VERSION "created by canmatrix"

NS_ :

BS_:

BU_: CEM HUT GW T_BOX ESP XBOX_D IFC TCU DVR Tester

BO_ 51 T_BOX_FD1: 16 T_BOX
 SG_ T_BOX_FD1_0x33 : 0|64@1+ (1,0) [0|0] ""  HUT

BO_ 68 HUT7: 8 HUT
 SG_ HUT7_0x44 : 0|64@1+ (1,0) [0|0] "" Vector__XXX

BO_ 74 HUT6: 8 HUT
 SG_ HUT6_0x4A : 0|64@1+ (1,0) [0|0] "" Vector__XXX

BO_ 86 GLO_NASS1: 8 GW
 SG_ GLO_NASS1_0x56 : 0|64@1+ (1,0) [0|0] ""  HUT

BO_ 161 CSA2: 8 GW
 SG_ CSA2_0xA1 : 0|64@1+ (1,0) [0|0] ""  HUT

BO_ 166 DCT3: 8 GW
 SG_ DCT3_0xA6 : 0|64@1+ (1,0) [0|0] ""  HUT

BO_ 200 ESP11: 8 GW
 SG_ ESP11_0xC8 : 0|64@1+ (1,0) [0|0] ""  HUT

BO_ 241 BMS4: 8 GW
 SG_ BMS4_0xF1 : 0|64@1+ (1,0) [0|0] ""  HUT

BO_ 265 IFC1: 8 GW
 SG_ IFC1_0x109 : 0|64@1+ (1,0) [0|0] ""  HUT

BO_ 273 ECM1: 8 GW
 SG_ ECM1_0x111 : 0|64@1+ (1,0) [0|0] ""  HUT

BO_ 288 Ibooster_FD2: 64 GW
 SG_ Ibooster_FD2_0x120 : 0|512@1+ (1,0) [0|0] ""  HUT

BO_ 311 ESP_FD2: 64 ESP
 SG_ ESP_FD2_0x137 : 0|448@1+ (1,0) [0|0] ""  HUT

BO_ 327 EPS_FD1: 64 GW
 SG_ EPS_FD1_0x147 : 0|512@1+ (1,0) [0|0] ""  HUT

BO_ 338 ELD1: 8 GW
 SG_ ELD1_0x152 : 0|64@1+ (1,0) [0|0] ""  HUT

BO_ 347 HAP_FD1: 64 GW
 SG_ HAP_FD1_0x15B : 0|512@1+ (1,0) [0|0] ""  HUT

BO_ 350 CR_FD1: 64 GW
 SG_ CR_FD1_0x15E : 0|512@1+ (1,0) [0|0] ""  HUT

BO_ 357 CSA1: 8 GW
 SG_ CSA1_0x165 : 0|64@1+ (1,0) [0|0] ""  HUT

BO_ 363 EPB1: 8 GW
 SG_ EPB1_0x16B : 0|64@1+ (1,0) [0|0] ""  HUT

BO_ 367 RSDS_FD1: 64 GW
 SG_ RSDS_FD1_0x16F : 0|512@1+ (1,0) [0|0] ""  HUT

BO_ 368 ESP8: 8 GW
 SG_ ESP8_0x170 : 0|64@1+ (1,0) [0|0] ""  HUT

BO_ 395 AEB_FD1: 64 GW
 SG_ AEB_FD1_0x18B : 0|512@1+ (1,0) [0|0] ""  HUT

BO_ 411 F_PBOX1: 8 CEM
 SG_ F_PBOX1_0x19B : 0|64@1+ (1,0) [0|0] ""  HUT

BO_ 412 R_PBOX1: 16 GW
 SG_ R_PBOX1_0x19C : 0|64@1+ (1,0) [0|0] ""  HUT

BO_ 415 IFC_FD5: 64 GW
 SG_ IFC_FD5_0x19F : 0|512@1+ (1,0) [0|0] ""  HUT

BO_ 465 HUT49: 8 HUT
 SG_ HUT49_0x1D1 : 0|64@1+ (1,0) [0|0] "" Vector__XXX

BO_ 473 GW_OTA: 8 CEM
 SG_ GW_OTA_0x1D9 : 0|64@1+ (1,0) [0|0] ""  HUT

BO_ 474 HUT_FD4: 64 HUT
 SG_ HUT_FD4_0x1DA : 0|512@1+ (1,0) [0|0] "" Vector__XXX

BO_ 475 HUT_FD5: 64 HUT
 SG_ HUT_FD5_0x1DB : 0|512@1+ (1,0) [0|0] "" Vector__XXX

BO_ 476 HUT45: 8 HUT
 SG_ HUT45_0x1DC : 0|64@1+ (1,0) [0|0] "" Vector__XXX

BO_ 477 HUT46: 8 HUT
 SG_ HUT46_0x1DD : 0|64@1+ (1,0) [0|0] "" Vector__XXX

BO_ 479 DOCK2: 64 XBOX_D
 SG_ DOCK2_0x1DF : 0|512@1+ (1,0) [0|0] ""  HUT

BO_ 481 T_BOX_FD4: 16 T_BOX
 SG_ T_BOX_FD4_0x1E1 : 0|128@1+ (1,0) [0|0] ""  HUT

BO_ 485 HUT35: 8 HUT
 SG_ HUT35_0x1E5 : 0|64@1+ (1,0) [0|0] "" Vector__XXX

BO_ 487 HUT38: 8 HUT
 SG_ HUT38_0x1E7 : 0|64@1+ (1,0) [0|0] "" Vector__XXX

BO_ 489 HUT30: 8 HUT
 SG_ HUT30_0x1E9 : 0|64@1+ (1,0) [0|0] "" Vector__XXX

BO_ 491 HUT39: 8 HUT
 SG_ HUT39_0x1EB : 0|64@1+ (1,0) [0|0] "" Vector__XXX

BO_ 493 HUT33: 8 HUT
 SG_ HUT33_0x1ED : 0|64@1+ (1,0) [0|0] "" Vector__XXX

BO_ 494 HUT15: 16 HUT
 SG_ HUT15_0x1EE : 0|64@1+ (1,0) [0|0] "" Vector__XXX

BO_ 497 ETC2: 8 GW
 SG_ ETC2_0x1F1 : 0|64@1+ (1,0) [0|0] ""  HUT

BO_ 498 ETC4: 8 GW
 SG_ ETC4_0x1F2 : 0|64@1+ (1,0) [0|0] ""  HUT

BO_ 505 HUT42: 8 HUT
 SG_ HUT42_0x1F9 : 0|64@1+ (1,0) [0|0] "" Vector__XXX

BO_ 506 BLE5: 8 GW
 SG_ BLE5_0x1FA : 0|64@1+ (1,0) [0|0] ""  HUT

BO_ 507 HUT41: 8 HUT
 SG_ HUT41_0x1FB : 0|64@1+ (1,0) [0|0] "" Vector__XXX

BO_ 509 HUT43: 8 HUT
 SG_ HUT43_0x1FD : 0|64@1+ (1,0) [0|0] "" Vector__XXX

BO_ 545 DCT5: 8 GW
 SG_ DCT5_0x221 : 0|64@1+ (1,0) [0|0] ""  HUT

BO_ 546 IFC_FD6: 64 GW
 SG_ IFC_FD6_0x222 : 0|512@1+ (1,0) [0|0] ""  HUT

BO_ 548 HUT40: 8 HUT
 SG_ HUT40_0x224 : 0|64@1+ (1,0) [0|0] "" Vector__XXX

BO_ 551 AEB_FD2: 64 IFC
 SG_ AEB_FD2_0x227 : 0|448@1+ (1,0) [0|0] ""  HUT

BO_ 561 ABS1: 8 GW
 SG_ ABS1_0x231 : 0|64@1+ (1,0) [0|0] ""  HUT

BO_ 566 DCT_FD4: 64 TCU
 SG_ DCT_FD4_0x236 : 0|448@1+ (1,0) [0|0] ""  HUT

BO_ 568 BCM12: 8 CEM
 SG_ BCM12_0x238 : 0|64@1+ (1,0) [0|0] ""  HUT

BO_ 573 IFC_FD2: 64 IFC
 SG_ IFC_FD2_0x23D : 0|448@1+ (1,0) [0|0] ""  HUT

BO_ 579 HUT_FD3: 64 HUT
 SG_ HUT_FD3_0x243 : 0|512@1+ (1,0) [0|0] "" Vector__XXX

BO_ 580 CSA3: 8 GW
 SG_ CSA3_0x244 : 0|64@1+ (1,0) [0|0] ""  HUT

BO_ 581 ABM2: 8 GW
 SG_ ABM2_0x245 : 0|64@1+ (1,0) [0|0] ""  HUT

BO_ 582 ABS2: 8 GW
 SG_ ABS2_0x246 : 0|64@1+ (1,0) [0|0] ""  HUT

BO_ 584 HCU_PT7: 8 GW
 SG_ HCU_PT7_0x248 : 0|64@1+ (1,0) [0|0] ""  HUT

BO_ 589 DMS_FD1: 64 HUT
 SG_ DMS_FD1_0x24D : 0|512@1+ (1,0) [0|0] "" Vector__XXX

BO_ 593 TOD1: 8 GW
 SG_ TOD1_0x251 : 0|64@1+ (1,0) [0|0] ""  HUT

BO_ 604 BLE1: 8 GW
 SG_ BLE1_0x25C : 0|64@1+ (1,0) [0|0] ""  HUT

BO_ 623 HUT32: 8 HUT
 SG_ HUT32_0x26F : 0|64@1+ (1,0) [0|0] "" Vector__XXX

BO_ 625 ECM2: 8 GW
 SG_ ECM2_0x271 : 0|64@1+ (1,0) [0|0] ""  HUT

BO_ 627 Trailer1: 8 GW
 SG_ Trailer1_0x273 : 0|64@1+ (1,0) [0|0] ""  HUT

BO_ 628 HAP_FD2: 64 GW
 SG_ HAP_FD2_0x274 : 0|512@1+ (1,0) [0|0] ""  HUT

BO_ 636 AC8: 8 GW
 SG_ AC8_0x27C : 0|64@1+ (1,0) [0|0] ""  HUT

BO_ 639 IP2: 16 HUT
 SG_ IP2_0x27F : 0|64@1+ (1,0) [0|0] "" Vector__XXX

BO_ 647 ALS1: 16 GW
 SG_ ALS1_0x287 : 0|128@1+ (1,0) [0|0] ""  HUT

BO_ 649 HAP_FD6: 64 GW
 SG_ HAP_FD6_0x289 : 0|512@1+ (1,0) [0|0] ""  HUT

BO_ 653 BCM7: 8 CEM
 SG_ BCM7_0x28D : 0|64@1+ (1,0) [0|0] ""  HUT

BO_ 656 ECM_PT6: 8 GW
 SG_ ECM_PT6_0x290 : 0|64@1+ (1,0) [0|0] ""  HUT

BO_ 659 IP1: 8 HUT
 SG_ IP1_0x293 : 0|64@1+ (1,0) [0|0] "" Vector__XXX

BO_ 661 PEPS2: 8 CEM
 SG_ PEPS2_0x295 : 0|64@1+ (1,0) [0|0] ""  HUT

BO_ 664 HAP_FD3: 64 GW
 SG_ HAP_FD3_0x298 : 0|512@1+ (1,0) [0|0] ""  HUT

BO_ 665 AC14: 8 GW
 SG_ AC14_0x299 : 0|64@1+ (1,0) [0|0] ""  HUT

BO_ 667 HAP_FD7: 64 GW
 SG_ HAP_FD7_0x29B : 0|512@1+ (1,0) [0|0] ""  HUT

BO_ 669 AC1: 8 GW
 SG_ AC1_0x29D : 0|64@1+ (1,0) [0|0] ""  HUT

BO_ 671 BCM8: 8 CEM
 SG_ BCM8_0x29F : 0|64@1+ (1,0) [0|0] ""  HUT

BO_ 675 BCM14: 8 CEM
 SG_ BCM14_0x2A3 : 0|64@1+ (1,0) [0|0] ""  HUT

BO_ 680 EEM1: 8 CEM
 SG_ EEM1_0x2A8 : 0|64@1+ (1,0) [0|0] ""  HUT

BO_ 683 ACC_FD2: 64 IFC
 SG_ ACC_FD2_0x2AB : 0|448@1+ (1,0) [0|0] ""  HUT

BO_ 692 ACC_FD3: 64 GW
 SG_ ACC_FD3_0x2B4 : 0|512@1+ (1,0) [0|0] ""  HUT

BO_ 694 HUT26: 8 HUT
 SG_ HUT26_0x2B6 : 0|64@1+ (1,0) [0|0] "" Vector__XXX

BO_ 696 ACC_FD4: 64 GW
 SG_ ACC_FD4_0x2B8 : 0|512@1+ (1,0) [0|0] ""  HUT

BO_ 697 DWD1: 8 GW
 SG_ DWD1_0x2B9 : 0|64@1+ (1,0) [0|0] ""  HUT

BO_ 698 WPC1: 8 GW
 SG_ WPC1_0x2BA : 0|64@1+ (1,0) [0|0] ""  HUT

BO_ 699 GW_FD1: 64 CEM
 SG_ GW_FD1_0x2BB : 0|512@1+ (1,0) [0|0] ""  HUT

BO_ 705 DSM1: 8 CEM
 SG_ DSM1_0x2C1 : 0|64@1+ (1,0) [0|0] ""  HUT

BO_ 707 HUT_FD1: 64 HUT
 SG_ HUT_FD1_0x2C3 : 0|448@1+ (1,0) [0|0] "" Vector__XXX

BO_ 714 DDCM1: 8 GW
 SG_ DDCM1_0x2CA : 0|64@1+ (1,0) [0|0] ""  HUT

BO_ 716 AC4: 8 GW
 SG_ AC4_0x2CC : 0|64@1+ (1,0) [0|0] ""  HUT

BO_ 717 PDCM1: 8 GW
 SG_ PDCM1_0x2CD : 0|64@1+ (1,0) [0|0] ""  HUT

BO_ 718 DSC4: 8 GW
 SG_ DSC4_0x2CE : 0|64@1+ (1,0) [0|0] ""  HUT

BO_ 719 IFC_FD3: 64 GW
 SG_ IFC_FD3_0x2CF : 0|512@1+ (1,0) [0|0] ""  HUT

BO_ 720 AC7: 8 GW
 SG_ AC7_0x2D0 : 0|64@1+ (1,0) [0|0] ""  HUT

BO_ 721 SCM1: 8 CEM
 SG_ SCM1_0x2D1 : 0|64@1+ (1,0) [0|0] ""  HUT

BO_ 722 AMP4_ANC1: 8 GW
 SG_ AMP4_ANC1_0x2D2 : 0|64@1+ (1,0) [0|0] ""  HUT

BO_ 723 ECM11: 8 GW
 SG_ ECM11_0x2D3 : 0|64@1+ (1,0) [0|0] ""  HUT

BO_ 728 HUT23: 8 HUT
 SG_ HUT23_0x2D8 : 0|64@1+ (1,0) [0|0] "" Vector__XXX

BO_ 730 HUT22: 8 HUT
 SG_ HUT22_0x2DA : 0|64@1+ (1,0) [0|0] "" Vector__XXX

BO_ 733 HUT21: 8 HUT
 SG_ HUT21_0x2DD : 0|64@1+ (1,0) [0|0] "" Vector__XXX

BO_ 734 HUT20: 8 HUT
 SG_ HUT20_0x2DE : 0|64@1+ (1,0) [0|0] "" Vector__XXX

BO_ 748 DVR_FD1: 64 HUT
 SG_ DVR_FD1_0x2EC : 0|512@1+ (1,0) [0|0] "" Vector__XXX

BO_ 752 T_BOX_FD10: 64 T_BOX
 SG_ T_BOX_FD10_0x2F0 : 0|512@1+ (1,0) [0|0] ""  HUT

BO_ 759 DDCM3: 8 GW
 SG_ DDCM3_0x2F7 : 0|64@1+ (1,0) [0|0] ""  HUT

BO_ 760 AC6: 8 GW
 SG_ AC6_0x2F8 : 0|64@1+ (1,0) [0|0] ""  HUT

BO_ 762 HCU_PT4: 8 GW
 SG_ HCU_PT4_0x2FA : 0|64@1+ (1,0) [0|0] ""  HUT

BO_ 765 AC3: 8 GW
 SG_ AC3_0x2FD : 0|64@1+ (1,0) [0|0] ""  HUT

BO_ 770 PEPS4: 8 CEM
 SG_ PEPS4_0x302 : 0|64@1+ (1,0) [0|0] ""  HUT

BO_ 771 ESCL2: 8 GW
 SG_ ESCL2_0x303 : 0|64@1+ (1,0) [0|0] ""  HUT

BO_ 772 HCM_L2: 8 GW
 SG_ HCM_L2_0x304 : 0|64@1+ (1,0) [0|0] ""  HUT

BO_ 773 BCM11: 8 CEM
 SG_ BCM11_0x305 : 0|64@1+ (1,0) [0|0] ""  HUT

BO_ 776 HCM_L1: 8 GW
 SG_ HCM_L1_0x308 : 0|64@1+ (1,0) [0|0] ""  HUT

BO_ 778 RSDS_FD2: 64 GW
 SG_ RSDS_FD2_0x30A : 0|512@1+ (1,0) [0|0] ""  HUT

BO_ 780 HUT31: 8 HUT
 SG_ HUT31_0x30C : 0|64@1+ (1,0) [0|0] "" Vector__XXX

BO_ 781 HCM_R1: 8 GW
 SG_ HCM_R1_0x30D : 0|64@1+ (1,0) [0|0] ""  HUT

BO_ 783 BCM19: 8 CEM
 SG_ BCM19_0x30F : 0|64@1+ (1,0) [0|0] ""  HUT

BO_ 785 DOCK1: 64 XBOX_D
 SG_ DOCK1_0x311 : 0|512@1+ (1,0) [0|0] ""  HUT

BO_ 793 BCM1: 16 GW
 SG_ BCM1_0x319 : 0|64@1+ (1,0) [0|0] ""  HUT

BO_ 796 HUT13: 8 HUT
 SG_ HUT13_0x31C : 0|64@1+ (1,0) [0|0] "" Vector__XXX

BO_ 805 HUD1: 8 GW
 SG_ HUD1_0x325 : 0|64@1+ (1,0) [0|0] ""  HUT

BO_ 816 HCM_R2: 8 GW
 SG_ HCM_R2_0x330 : 0|64@1+ (1,0) [0|0] ""  HUT

BO_ 817 HUT10: 8 HUT
 SG_ HUT10_0x331 : 0|64@1+ (1,0) [0|0] "" Vector__XXX

BO_ 818 RFCM_L1: 8 GW
 SG_ RFCM_L1_0x332 : 0|64@1+ (1,0) [0|0] ""  HUT

BO_ 819 RFCM_R1: 8 GW
 SG_ RFCM_R1_0x333 : 0|64@1+ (1,0) [0|0] ""  HUT

BO_ 825 HUT25: 8 HUT
 SG_ HUT25_0x339 : 0|64@1+ (1,0) [0|0] "" Vector__XXX

BO_ 827 HUT17: 8 HUT
 SG_ HUT17_0x33B : 0|64@1+ (1,0) [0|0] "" Vector__XXX

BO_ 833 TPMS1: 16 GW
 SG_ TPMS1_0x341 : 0|64@1+ (1,0) [0|0] ""  HUT

BO_ 836 ETC3: 8 GW
 SG_ ETC3_0x344 : 0|64@1+ (1,0) [0|0] ""  HUT

BO_ 837 BCM3: 16 GW
 SG_ BCM3_0x345 : 0|64@1+ (1,0) [0|0] ""  HUT

BO_ 840 HUT16: 8 HUT
 SG_ HUT16_0x348 : 0|64@1+ (1,0) [0|0] "" Vector__XXX

BO_ 842 IP3: 16 HUT
 SG_ IP3_0x34A : 0|128@1+ (1,0) [0|0] "" Vector__XXX

BO_ 845 BCM18: 8 CEM
 SG_ BCM18_0x34D : 0|64@1+ (1,0) [0|0] ""  HUT

BO_ 849 ABM1: 16 GW
 SG_ ABM1_0x351 : 0|64@1+ (1,0) [0|0] ""  HUT

BO_ 862 CP1: 8 CEM
 SG_ CP1_0x35E : 0|64@1+ (1,0) [0|0] ""  HUT

BO_ 871 HUT1: 8 HUT
 SG_ HUT1_0x367 : 0|64@1+ (1,0) [0|0] "" Vector__XXX

BO_ 873 HUT2: 8 HUT
 SG_ HUT2_0x369 : 0|64@1+ (1,0) [0|0] "" Vector__XXX

BO_ 875 HUT3: 8 HUT
 SG_ HUT3_0x36B : 0|64@1+ (1,0) [0|0] "" Vector__XXX

BO_ 877 HUT4: 8 HUT
 SG_ HUT4_0x36D : 0|64@1+ (1,0) [0|0] "" Vector__XXX

BO_ 880 HUT34: 8 HUT
 SG_ HUT34_0x370 : 0|64@1+ (1,0) [0|0] "" Vector__XXX

BO_ 881 ECM3: 8 GW
 SG_ ECM3_0x371 : 0|64@1+ (1,0) [0|0] ""  HUT

BO_ 901 AC2: 8 GW
 SG_ AC2_0x385 : 0|64@1+ (1,0) [0|0] ""  HUT

BO_ 917 TPMS2: 16 GW
 SG_ TPMS2_0x395 : 0|64@1+ (1,0) [0|0] ""  HUT

BO_ 943 HUT12: 8 HUT
 SG_ HUT12_0x3AF : 0|64@1+ (1,0) [0|0] "" Vector__XXX

BO_ 949 ECM19: 8 GW
 SG_ ECM19_0x3B5 : 0|64@1+ (1,0) [0|0] ""  HUT

BO_ 951 ECM20: 8 GW
 SG_ ECM20_0x3B7 : 0|64@1+ (1,0) [0|0] ""  HUT

BO_ 962 HCU_HC7: 8 GW
 SG_ HCU_HC7_0x3C2 : 0|64@1+ (1,0) [0|0] ""  HUT

BO_ 993 AMP1: 8 GW
 SG_ AMP1_0x3E1 : 0|64@1+ (1,0) [0|0] ""  HUT

BO_ 995 AMP2: 16 GW
 SG_ AMP2_0x3E3 : 0|64@1+ (1,0) [0|0] ""  HUT

BO_ 997 AMP3: 8 GW
 SG_ AMP3_0x3E5 : 0|64@1+ (1,0) [0|0] ""  HUT

BO_ 1001 T_BOX_FD3: 16 T_BOX
 SG_ T_BOX_FD3_0x3E9 : 0|64@1+ (1,0) [0|0] ""  HUT

BO_ 1045 HUT19: 8 HUT
 SG_ HUT19_0x415 : 0|64@1+ (1,0) [0|0] "" Vector__XXX

BO_ 1888 DiagFuncReq: 8 Tester
 SG_ DiagFuncReq : 7|64@0+ (1,0) [0|1.84467440737096E+019] ""  GW,CEM,T_BOX,XBOX_D,DVR,HUT

BO_ 1889 GW_Phy_Req: 8 Tester
 SG_ GW_Phy_Req : 7|64@0+ (1,0) [0|1.84467440737096E+019] ""  GW

BO_ 1918 T_Box_Phy_Req: 8 Tester
 SG_ T_Box_Phy_Req : 7|64@0+ (1,0) [0|1.84467440737096E+019] ""  GW,T_BOX

BO_ 1843 XBOX_D_Phy_Req: 8 Tester
 SG_ XBOX_D_Phy_Req : 7|64@0+ (1,0) [0|1.84467440737096E+019] ""  GW,XBOX_D

BO_ 1907 HUT_Phy_Req: 8 Tester
 SG_ HUT_Phy_Req : 7|64@0+ (1,0) [0|1.84467440737096E+019] ""  GW,HUT

BO_ 1953 GW_Phy_Resp: 8 GW
 SG_ GW_Phy_Resp : 7|64@0+ (1,0) [0|1.84467440737096E+019] ""  Tester

BO_ 1982 T_Box_Phy_Resp: 8 T_BOX
 SG_ T_Box_Phy_Resp : 7|64@0+ (1,0) [0|1.84467440737096E+019] ""  GW,Tester

BO_ 1844 XBOX_D_Phy_Resp: 8 XBOX_D
 SG_ XBOX_D_Phy_Resp : 7|64@0+ (1,0) [0|1.84467440737096E+019] ""  GW,Tester

BO_ 1971 HUT_Phy_Resp: 8 HUT
 SG_ HUT_Phy_Resp : 7|64@0+ (1,0) [0|1.84467440737096E+019] ""  GW,Tester

BO_ 1290 T_Box_NM: 8 T_BOX
 SG_ Destination_T_Box_NM : 7|8@0+ (1,0) [0|255] ""  CEM,XBOX_D,DVR,HUT
 SG_ OpCode_T_Box_NM : 15|8@0+ (1,0) [0|255] ""  CEM,XBOX_D,DVR,HUT

BO_ 1289 HUT_NM: 8 HUT
 SG_ Destination_HUT_NM : 7|8@0+ (1,0) [0|255] ""  CEM,T_BOX,XBOX_D,DVR
 SG_ OpCode_HUT_NM : 15|8@0+ (1,0) [0|255] ""  CEM,T_BOX,XBOX_D,DVR

BO_ 1334 XBOX_D_NM: 8 XBOX_D
 SG_ Destination_XBOX_D_NM : 7|8@0+ (1,0) [0|255] ""  CEM,T_BOX,DVR,HUT
 SG_ OpCode_XBOX_D_NM : 15|8@0+ (1,0) [0|255] ""  CEM,T_BOX,DVR,HUT

BO_ 1281 CEM_NM: 8 CEM
 SG_ Destination_CEM_NM : 7|8@0+ (1,0) [0|255] ""  T_BOX,XBOX_D,DVR,HUT
 SG_ OpCode_CEM_NM : 15|8@0+ (1,0) [0|255] ""  T_BOX,XBOX_D,DVR,HUT

BO_ 1122 HUT_Sync_Req: 16 HUT
 SG_ SyncRequestMessageId : 7|8@0+ (1,0) [0|0] ""  GW
 SG_ SyncRequstReseverData : 15|56@0+ (1,0) [0|0] ""  GW

BO_ 1121 GW_Sync_Req: 16 GW
 SG_ ResetCount : 31|16@0+ (1,0) [0|0] ""  HUT
 SG_ CMACMessageInfo : 47|88@0+ (1,0) [0|0] ""  HUT
 SG_ TripCount : 7|24@0+ (1,0) [0|0] ""  HUT

BO_ 53 PEPS5: 8 CEM
 SG_ PEPS_T_BOXAuth1 : 7|64@0+ (1,0) [0|1.84467440737095E+019] ""  T_BOX

BO_ 54 T_BOX_FD2: 16 T_BOX
 SG_ T_BOX_PEPSAuth1 : 7|64@0+ (1,0) [0|1.84467440737096E+019] ""  CEM

BO_ 70 PEPS11: 8 CEM
 SG_ PEPS_T_BOXAuth2 : 7|64@0+ (1,0) [0|1.84467440737096E+019] ""  T_BOX

BO_ 72 T_BOX_FD7: 16 T_BOX
 SG_ T_BOX_PEPSAuth2 : 7|64@0+ (1,0) [0|1.84467440737096E+019] ""  CEM

BO_ 96 HCU_FD1: 64 GW
 SG_ HCU_FD1_0x60 : 0|512@1+ (1,0) [0|0] ""  HUT

BO_ 142 ECM_PT5: 8 GW
 SG_ ECM_PT5_0x8E : 0|64@1+ (1,0) [0|0] ""  HUT

BO_ 172 P2M1: 8 GW
 SG_ P2M1_0xAC : 0|64@1+ (1,0) [0|0] ""  HUT

BO_ 190 P2M3: 8 GW
 SG_ P2M3_0xBE : 0|64@1+ (1,0) [0|0] ""  HUT

BO_ 249 HCU_HP8: 8 GW
 SG_ HCU_HP8_0xF9 : 0|64@1+ (1,0) [0|0] ""  HUT

BO_ 279 ECM_PT7: 8 GW
 SG_ ECM_PT7_0x117 : 0|64@1+ (1,0) [0|0] ""  HUT

BO_ 282 HCU_HP6: 8 GW
 SG_ HCU_HP6_0x11A : 0|64@1+ (1,0) [0|0] ""  HUT

BO_ 301 EBOOSTER_FD1: 64 GW
 SG_ EBOOSTER_FD1_0x12D : 0|512@1+ (1,0) [0|0] ""  HUT

BO_ 330 HCU_PT5: 8 GW
 SG_ HCU_PT5_0x14A : 0|64@1+ (1,0) [0|0] ""  HUT

BO_ 448 HCU_PT8: 8 GW
 SG_ HCU_PT8_0x1C0 : 0|64@1+ (1,0) [0|0] ""  HUT

BO_ 482 HCU_HC8: 8 GW
 SG_ HCU_HC8_0x1E2 : 0|64@1+ (1,0) [0|0] ""  HUT

BO_ 483 BMS_FD14: 8 GW
 SG_ BMS_FD14_0x1E3 : 0|64@1+ (1,0) [0|0] ""  HUT

BO_ 510 T_BOX_FD9: 8 T_BOX
 SG_ T_BOX_FD9_0x1FE : 0|64@1+ (1,0) [0|0] ""  HUT

BO_ 513 HCU_HP5: 8 GW
 SG_ HCU_HP5_0x201 : 0|64@1+ (1,0) [0|0] ""  HUT

BO_ 515 HUT_FD2: 64 HUT
 SG_ HUT_FD2_0x203 : 0|512@1+ (1,0) [0|0] "" Vector__XXX

BO_ 616 HCU_HC3: 8 GW
 SG_ HCU_HC3_0x268 : 0|64@1+ (1,0) [0|0] ""  HUT

BO_ 645 BMS8: 8 GW
 SG_ BMS8_0x285 : 0|64@1+ (1,0) [0|0] ""  HUT

BO_ 690 HUT27: 8 HUT
 SG_ HUT27_0x2B2 : 0|64@1+ (1,0) [0|0] "" Vector__XXX

BO_ 708 BMS35: 8 GW
 SG_ BMS35_0x2C4 : 0|64@1+ (1,0) [0|0] ""  HUT

BO_ 743 BCM10: 16 CEM
 SG_ RFPosnLmpWorkCmd : 15|1@0+ (1,0) [0|1] ""  T_BOX
 SG_ LFPosnLmpWorkCmd : 12|1@0+ (1,0) [0|1] ""  T_BOX
 SG_ HiBeamWorkCmd : 11|1@0+ (1,0) [0|1] ""  T_BOX
 SG_ LowBeamWorkCmd : 10|1@0+ (1,0) [0|1] ""  T_BOX
 SG_ RTurnLmpWorkCmd : 9|1@0+ (1,0) [0|1] ""  T_BOX
 SG_ LTurnLampWorkCmd : 8|1@0+ (1,0) [0|1] ""  T_BOX
 SG_ RDayRunngLmpWorkCmd : 21|1@0+ (1,0) [0|1] ""  T_BOX
 SG_ LDayRunngLmpWorkCmd : 20|1@0+ (1,0) [0|1] ""  T_BOX
 SG_ RFFogLmpWorkCmd : 19|1@0+ (1,0) [0|1] ""  T_BOX
 SG_ LFFogLmpWorkCmd : 18|1@0+ (1,0) [0|1] ""  T_BOX
 SG_ LicPlateLmpWorkCmd : 27|1@0+ (1,0) [0|1] ""  T_BOX
 SG_ ReversLampWorkCmd : 26|1@0+ (1,0) [0|1] ""  T_BOX
 SG_ BrkLmpWorkCmd : 25|1@0+ (1,0) [0|1] ""  T_BOX
 SG_ RFogLmpWorkCmd : 24|1@0+ (1,0) [0|1] ""  T_BOX
 SG_ RRPosnLmpWorkCmd : 47|1@0+ (1,0) [0|1] ""  T_BOX
 SG_ LRPosnLmpWorkCmd : 46|1@0+ (1,0) [0|1] ""  T_BOX

BO_ 788 HCU_HC6: 8 GW
 SG_ HCU_HC6_0x314 : 0|64@1+ (1,0) [0|0] ""  HUT

BO_ 790 OBC1: 8 GW
 SG_ OBC1_0x316 : 0|64@1+ (1,0) [0|0] ""  HUT

BO_ 791 OBC2: 8 GW
 SG_ OBC2_0x317 : 0|64@1+ (1,0) [0|0] ""  HUT

BO_ 829 T_BOX_FD6: 16 T_BOX
 SG_ T_BOX_RemtLRTempSet : 21|6@0+ (0.5,16) [16.5|31.5] "ÃƒÂ‚Ã‚Â°C"  GW
 SG_ T_BOX_RemtRRTempSet : 29|6@0+ (0.5,16) [16.5|31.5] "ÃƒÂ‚Ã‚Â°C" Vector__XXX
 SG_ T_BOX_RemtRearAutoCtrl : 47|2@0+ (1,0) [0|3] ""  GW
 SG_ T_BOX_RemtSecRowLeSeatVentnLvlSe : 10|3@0+ (1,0) [0|7] ""  CEM
 SG_ T_BOX_RemtSecRowRiSeatVentnLvlSe : 13|3@0+ (1,0) [0|7] ""  CEM
 SG_ T_BOX_MbrMonrEnReq : 35|2@0+ (1,0) [0|3] "" Vector__XXX
 SG_ ReleAlarm_APP : 33|2@0+ (1,0) [0|3] "" Vector__XXX
 SG_ T_BOX_RemtSteerWheelHeatCtrl : 15|2@0+ (1,0) [0|3] ""  GW
 SG_ T_BOX_AVPActvReq : 3|2@0+ (1,0) [0|3] ""  GW

BO_ 850 BMS19: 8 GW
 SG_ BMS19_0x352 : 0|64@1+ (1,0) [0|0] ""  HUT

BO_ 865 HCU_FD6: 64 GW
 SG_ HCU_HVILSts : 218|2@0+ (1,0) [0|3] ""  T_BOX
 SG_ HCU_BMSSleepCmd : 216|1@0+ (1,0) [0|1] ""  T_BOX
 SG_ HCU_P2MActHvDcCurr_RM : 263|16@0+ (0.1,-1000) [-1000|1000] "A"  T_BOX
 SG_ HCU_P2MActHvDcVolt_RM : 279|16@0+ (0.1,0) [0|6000] "V"  T_BOX
 SG_ HCU_DTCNumber1 : 295|10@0+ (1,0) [0|1023] ""  T_BOX
 SG_ HCU_DTCNumber2 : 301|10@0+ (1,0) [0|1023] ""  T_BOX
 SG_ HCU_MotorAmount_RM : 335|8@0+ (1,0) [1|253] ""  T_BOX

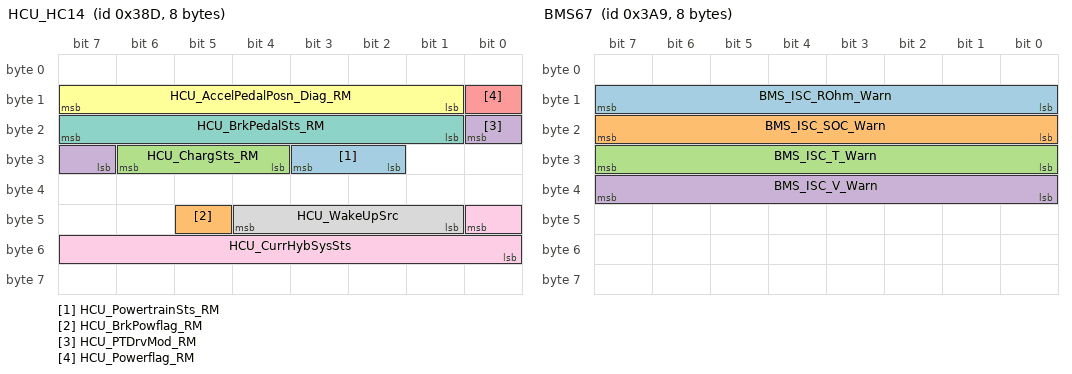
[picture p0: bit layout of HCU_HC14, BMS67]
BO_ 909 HCU_HC14: 8 GW
 SG_ HCU_PowertrainSts_RM : 27|2@0+ (1,0) [0|3] ""  T_BOX
 SG_ HCU_BrkPowflag_RM : 45|1@0+ (1,0) [0|1] ""  T_BOX
 SG_ HCU_ChargSts_RM : 30|3@0+ (1,0) [0|7] ""  T_BOX
 SG_ HCU_PTDrvMod_RM : 16|2@0+ (1,0) [0|3] ""  T_BOX
 SG_ HCU_Powerflag_RM : 8|1@0+ (1,0) [0|1] ""  T_BOX
 SG_ HCU_AccelPedalPosn_Diag_RM : 15|7@0+ (1,0) [0|100] "%"  T_BOX
 SG_ HCU_BrkPedalSts_RM : 23|7@0+ (1,0) [0|101] ""  T_BOX
 SG_ HCU_WakeUpSrc : 44|4@0+ (1,0) [0|15] ""  T_BOX
 SG_ HCU_CurrHybSysSts : 40|9@0+ (1,0) [0|500] ""  T_BOX

BO_ 937 BMS67: 8 GW
 SG_ BMS_ISC_ROhm_Warn : 15|8@0+ (0.1,0) [0|5] ""  T_BOX
 SG_ BMS_ISC_SOC_Warn : 23|8@0+ (1,0) [0|100] ""  T_BOX
 SG_ BMS_ISC_T_Warn : 31|8@0+ (1,-40) [-40|125] "ÃƒÂ‚Ã‚Â°C"  T_BOX
 SG_ BMS_ISC_V_Warn : 39|8@0+ (0.1,0) [0|5] "V"  T_BOX

BO_ 942 BMS66: 8 GW
 SG_ BMS66_0x3AE : 0|64@1+ (1,0) [0|0] ""  HUT

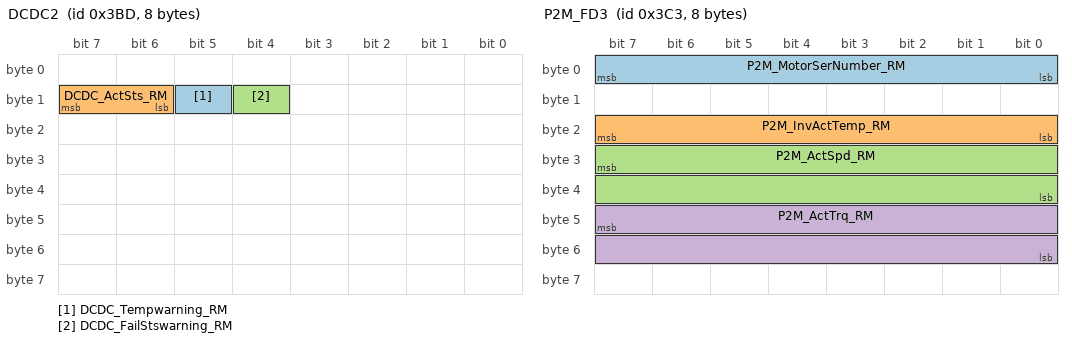
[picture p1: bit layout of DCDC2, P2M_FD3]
BO_ 957 DCDC2: 8 GW
 SG_ DCDC_Tempwarning_RM : 13|1@0+ (1,0) [0|1] ""  T_BOX
 SG_ DCDC_ActSts_RM : 15|2@0+ (1,0) [0|3] ""  T_BOX
 SG_ DCDC_FailStswarning_RM : 12|1@0+ (1,0) [0|1] ""  T_BOX

BO_ 959 BMS22: 8 GW
 SG_ BMS22_0x3BF : 0|64@1+ (1,0) [0|0] ""  HUT

BO_ 963 P2M_FD3: 8 GW
 SG_ P2M_MotorSerNumber_RM : 7|8@0+ (1,0) [1|253] ""  T_BOX
 SG_ P2M_InvActTemp_RM : 23|8@0+ (1,-40) [-40|210] "ÃƒÂ‚Ã‚Â°C"  T_BOX
 SG_ P2M_ActSpd_RM : 31|16@0+ (1,-20000) [-20000|45531] "rpm"  T_BOX
 SG_ P2M_ActTrq_RM : 47|16@0+ (0.1,-2000) [-2000|4553.1] "Nm"  T_BOX

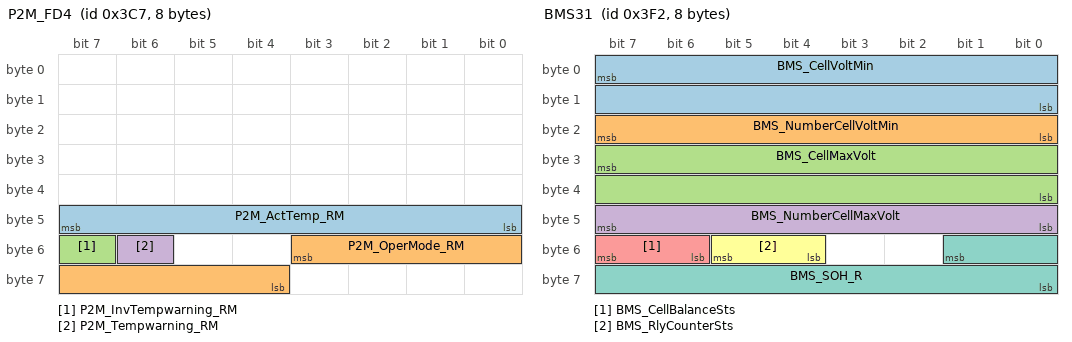
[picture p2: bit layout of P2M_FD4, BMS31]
BO_ 967 P2M_FD4: 8 GW
 SG_ P2M_ActTemp_RM : 47|8@0+ (1,-40) [-40|210] "ÃƒÂ‚Ã‚Â°C"  T_BOX
 SG_ P2M_OperMode_RM : 51|8@0+ (1,0) [0|255] ""  T_BOX
 SG_ P2M_InvTempwarning_RM : 55|1@0+ (1,0) [0|1] ""  T_BOX
 SG_ P2M_Tempwarning_RM : 54|1@0+ (1,0) [0|1] ""  T_BOX

BO_ 976 BMS26: 8 GW
 SG_ BMS_BattTempMax : 15|8@0+ (1,-40) [-40|90] "ÃƒÂ‚Ã‚Â°C"  T_BOX
 SG_ BMS_BattTempMin : 23|8@0+ (1,-40) [-40|90] "ÃƒÂ‚Ã‚Â°C"  T_BOX

BO_ 977 BMS_FD5: 64 GW
 SG_ BMS_SingleCellVolt_1 : 263|16@0+ (0.001,0) [0|60] "V"  T_BOX
 SG_ BMS_SingleCellVolt_2 : 279|16@0+ (0.001,0) [0|60] "V"  T_BOX
 SG_ BMS_SingleCellVolt_3 : 295|16@0+ (0.001,0) [0|60] "V"  T_BOX
 SG_ BMS_SingleCellVolt_4 : 311|16@0+ (0.001,0) [0|60] "V"  T_BOX
 SG_ BMS_SingleCellVolt_5 : 327|16@0+ (0.001,0) [0|60] "V"  T_BOX
 SG_ BMS_SingleCellVolt_6 : 343|16@0+ (0.001,0) [0|60] "V"  T_BOX
 SG_ BMS_SingleCellVolt_7 : 359|16@0+ (0.001,0) [0|60] "V"  T_BOX
 SG_ BMS_SingleCellVolt_8 : 375|16@0+ (0.001,0) [0|60] "V"  T_BOX
 SG_ BMS_SingleCellVolt_9 : 391|16@0+ (0.001,0) [0|60] "V"  T_BOX
 SG_ BMS_SingleCellVolt_10 : 407|16@0+ (0.001,0) [0|60] "V"  T_BOX
 SG_ BMS_SingleCellVolt_11 : 423|16@0+ (0.001,0) [0|60] "V"  T_BOX
 SG_ BMS_SingleCellVolt_12 : 439|16@0+ (0.001,0) [0|60] "V"  T_BOX
 SG_ BMS_BattModuleTe_11 : 135|8@0+ (1,-40) [-40|125] "ÃƒÂ‚Ã‚Â°C"  T_BOX
 SG_ BMS_BattModuleTe_12 : 143|8@0+ (1,-40) [-40|125] "ÃƒÂ‚Ã‚Â°C"  T_BOX
 SG_ BMS_BattModuleTe_21 : 151|8@0+ (1,-40) [-40|125] "ÃƒÂ‚Ã‚Â°C"  T_BOX
 SG_ BMS_BattModuleTe_22 : 159|8@0+ (1,-40) [-40|125] "ÃƒÂ‚Ã‚Â°C"  T_BOX
 SG_ BMS_BattModuleTe_31 : 167|8@0+ (1,-40) [-40|125] "ÃƒÂ‚Ã‚Â°C"  T_BOX
 SG_ BMS_BattModuleTe_32 : 175|8@0+ (1,-40) [-40|125] "ÃƒÂ‚Ã‚Â°C"  T_BOX
 SG_ BMS_BattModuleTe_41 : 183|8@0+ (1,-40) [-40|125] "ÃƒÂ‚Ã‚Â°C"  T_BOX
 SG_ BMS_BattModuleTe_42 : 191|8@0+ (1,-40) [-40|125] "ÃƒÂ‚Ã‚Â°C"  T_BOX
 SG_ BMS_BattModuleTe_51 : 71|8@0+ (1,-40) [-40|125] "ÃƒÂ‚Ã‚ÂºC"  T_BOX
 SG_ BMS_BattModuleTe_52 : 79|8@0+ (1,-40) [-40|125] "ÃƒÂ‚Ã‚ÂºC"  T_BOX
 SG_ BMS_BattModuleTe_61 : 87|8@0+ (1,-40) [-40|125] "ÃƒÂ‚Ã‚ÂºC"  T_BOX
 SG_ BMS_BattModuleTe_62 : 95|8@0+ (1,-40) [-40|125] "ÃƒÂ‚Ã‚ÂºC"  T_BOX
 SG_ BMS_BattModuleTe_71 : 103|8@0+ (1,-40) [-40|125] "ÃƒÂ‚Ã‚ÂºC"  T_BOX
 SG_ BMS_BattModuleTe_72 : 111|8@0+ (1,-40) [-40|125] "ÃƒÂ‚Ã‚ÂºC"  T_BOX
 SG_ BMS_BattModuleTe_81 : 119|8@0+ (1,-40) [-40|125] "ÃƒÂ‚Ã‚ÂºC"  T_BOX
 SG_ BMS_BattModuleTe_82 : 127|8@0+ (1,-40) [-40|125] "ÃƒÂ‚Ã‚ÂºC"  T_BOX

BO_ 978 BMS_FD6: 64 GW
 SG_ BMS_SingleCellVolt_13 : 7|16@0+ (0.001,0) [0|60] "V"  T_BOX
 SG_ BMS_SingleCellVolt_14 : 23|16@0+ (0.001,0) [0|60] "V"  T_BOX
 SG_ BMS_SingleCellVolt_15 : 39|16@0+ (0.001,0) [0|60] "V"  T_BOX
 SG_ BMS_SingleCellVolt_16 : 55|16@0+ (0.001,0) [0|60] "V"  T_BOX
 SG_ BMS_SingleCellVolt_17 : 71|16@0+ (0.001,0) [0|60] "V"  T_BOX
 SG_ BMS_SingleCellVolt_18 : 87|16@0+ (0.001,0) [0|60] "V"  T_BOX
 SG_ BMS_SingleCellVolt_19 : 103|16@0+ (0.001,0) [0|60] "V"  T_BOX
 SG_ BMS_SingleCellVolt_20 : 119|16@0+ (0.001,0) [0|60] "V"  T_BOX
 SG_ BMS_SingleCellVolt_21 : 135|16@0+ (0.001,0) [0|60] "V"  T_BOX
 SG_ BMS_SingleCellVolt_22 : 151|16@0+ (0.001,0) [0|60] "V"  T_BOX
 SG_ BMS_SingleCellVolt_23 : 167|16@0+ (0.001,0) [0|60] "V"  T_BOX
 SG_ BMS_SingleCellVolt_24 : 183|16@0+ (0.001,0) [0|60] "V"  T_BOX
 SG_ BMS_SingleCellVolt_25 : 199|16@0+ (0.001,0) [0|60] "V"  T_BOX
 SG_ BMS_SingleCellVolt_26 : 215|16@0+ (0.001,0) [0|60] "V"  T_BOX
 SG_ BMS_SingleCellVolt_27 : 231|16@0+ (0.001,0) [0|60] "V"  T_BOX
 SG_ BMS_SingleCellVolt_28 : 247|16@0+ (0.001,0) [0|60] "V"  T_BOX
 SG_ BMS_SingleCellVolt_29 : 263|16@0+ (0.001,0) [0|60] "V"  T_BOX
 SG_ BMS_SingleCellVolt_30 : 279|16@0+ (0.001,0) [0|60] "V"  T_BOX
 SG_ BMS_SingleCellVolt_31 : 295|16@0+ (0.001,0) [0|60] "V"  T_BOX
 SG_ BMS_SingleCellVolt_32 : 311|16@0+ (0.001,0) [0|60] "V"  T_BOX
 SG_ BMS_SingleCellVolt_33 : 327|16@0+ (0.001,0) [0|60] "V"  T_BOX
 SG_ BMS_SingleCellVolt_34 : 343|16@0+ (0.001,0) [0|60] "V"  T_BOX
 SG_ BMS_SingleCellVolt_35 : 359|16@0+ (0.001,0) [0|60] "V"  T_BOX
 SG_ BMS_SingleCellVolt_36 : 375|16@0+ (0.001,0) [0|60] "V"  T_BOX
 SG_ BMS_SingleCellVolt_37 : 391|16@0+ (0.001,0) [0|60] "V"  T_BOX
 SG_ BMS_SingleCellVolt_38 : 407|16@0+ (0.001,0) [0|60] "V"  T_BOX
 SG_ BMS_SingleCellVolt_39 : 423|16@0+ (0.001,0) [0|60] "V"  T_BOX
 SG_ BMS_SingleCellVolt_40 : 439|16@0+ (0.001,0) [0|60] "V"  T_BOX

BO_ 979 BMS_FD7: 64 GW
 SG_ BMS_SingleCellVolt_41 : 7|16@0+ (0.001,0) [0|60] "V"  T_BOX
 SG_ BMS_SingleCellVolt_42 : 23|16@0+ (0.001,0) [0|60] "V"  T_BOX
 SG_ BMS_SingleCellVolt_43 : 39|16@0+ (0.001,0) [0|60] "V"  T_BOX
 SG_ BMS_SingleCellVolt_44 : 55|16@0+ (0.001,0) [0|60] "V"  T_BOX
 SG_ BMS_SingleCellVolt_45 : 71|16@0+ (0.001,0) [0|60] "V"  T_BOX
 SG_ BMS_SingleCellVolt_46 : 87|16@0+ (0.001,0) [0|60] "V"  T_BOX
 SG_ BMS_SingleCellVolt_47 : 103|16@0+ (0.001,0) [0|60] "V"  T_BOX
 SG_ BMS_SingleCellVolt_48 : 119|16@0+ (0.001,0) [0|60] "V"  T_BOX
 SG_ BMS_SingleCellVolt_49 : 135|16@0+ (0.001,0) [0|60] "V"  T_BOX
 SG_ BMS_SingleCellVolt_50 : 151|16@0+ (0.001,0) [0|60] "V"  T_BOX
 SG_ BMS_SingleCellVolt_51 : 167|16@0+ (0.001,0) [0|60] "V"  T_BOX
 SG_ BMS_SingleCellVolt_52 : 183|16@0+ (0.001,0) [0|60] "V"  T_BOX
 SG_ BMS_SingleCellVolt_53 : 199|16@0+ (0.001,0) [0|60] "V"  T_BOX
 SG_ BMS_SingleCellVolt_54 : 215|16@0+ (0.001,0) [0|60] "V"  T_BOX
 SG_ BMS_SingleCellVolt_55 : 231|16@0+ (0.001,0) [0|60] "V"  T_BOX
 SG_ BMS_SingleCellVolt_56 : 247|16@0+ (0.001,0) [0|60] "V"  T_BOX
 SG_ BMS_SingleCellVolt_57 : 263|16@0+ (0.001,0) [0|60] "V"  T_BOX
 SG_ BMS_SingleCellVolt_58 : 279|16@0+ (0.001,0) [0|60] "V"  T_BOX
 SG_ BMS_SingleCellVolt_59 : 295|16@0+ (0.001,0) [0|60] "V"  T_BOX
 SG_ BMS_SingleCellVolt_60 : 311|16@0+ (0.001,0) [0|60] "V"  T_BOX
 SG_ BMS_SingleCellVolt_61 : 327|16@0+ (0.001,0) [0|60] "V"  T_BOX
 SG_ BMS_SingleCellVolt_62 : 343|16@0+ (0.001,0) [0|60] "V"  T_BOX
 SG_ BMS_SingleCellVolt_63 : 359|16@0+ (0.001,0) [0|60] "V"  T_BOX
 SG_ BMS_SingleCellVolt_64 : 375|16@0+ (0.001,0) [0|60] "V"  T_BOX
 SG_ BMS_SingleCellVolt_65 : 391|16@0+ (0.001,0) [0|60] "V"  T_BOX
 SG_ BMS_SingleCellVolt_66 : 407|16@0+ (0.001,0) [0|60] "V"  T_BOX
 SG_ BMS_SingleCellVolt_67 : 423|16@0+ (0.001,0) [0|60] "V"  T_BOX
 SG_ BMS_SingleCellVolt_68 : 439|16@0+ (0.001,0) [0|60] "V"  T_BOX

BO_ 980 BMS_FD8: 64 GW
 SG_ BMS_SingleCellVolt_69 : 7|16@0+ (0.001,0) [0|60] "V"  T_BOX
 SG_ BMS_SingleCellVolt_70 : 23|16@0+ (0.001,0) [0|60] "V"  T_BOX
 SG_ BMS_SingleCellVolt_71 : 39|16@0+ (0.001,0) [0|60] "V"  T_BOX
 SG_ BMS_SingleCellVolt_72 : 55|16@0+ (0.001,0) [0|60] "V"  T_BOX
 SG_ BMS_SingleCellVolt_73 : 71|16@0+ (0.001,0) [0|60] "V"  T_BOX
 SG_ BMS_SingleCellVolt_74 : 87|16@0+ (0.001,0) [0|60] "V"  T_BOX
 SG_ BMS_SingleCellVolt_75 : 103|16@0+ (0.001,0) [0|60] "V"  T_BOX
 SG_ BMS_SingleCellVolt_76 : 119|16@0+ (0.001,0) [0|60] "V"  T_BOX
 SG_ BMS_SingleCellVolt_77 : 135|16@0+ (0.001,0) [0|60] "V"  T_BOX
 SG_ BMS_SingleCellVolt_78 : 151|16@0+ (0.001,0) [0|60] "V"  T_BOX
 SG_ BMS_SingleCellVolt_79 : 167|16@0+ (0.001,0) [0|60] "V"  T_BOX
 SG_ BMS_SingleCellVolt_80 : 183|16@0+ (0.001,0) [0|60] "V"  T_BOX
 SG_ BMS_SingleCellVolt_81 : 199|16@0+ (0.001,0) [0|60] "V"  T_BOX
 SG_ BMS_SingleCellVolt_82 : 215|16@0+ (0.001,0) [0|60] "V"  T_BOX
 SG_ BMS_SingleCellVolt_83 : 231|16@0+ (0.001,0) [0|60] "V"  T_BOX
 SG_ BMS_SingleCellVolt_84 : 247|16@0+ (0.001,0) [0|60] "V"  T_BOX
 SG_ BMS_SingleCellVolt_85 : 263|16@0+ (0.001,0) [0|60] "V"  T_BOX
 SG_ BMS_SingleCellVolt_86 : 279|16@0+ (0.001,0) [0|60] "V"  T_BOX
 SG_ BMS_SingleCellVolt_87 : 295|16@0+ (0.001,0) [0|60] "V"  T_BOX
 SG_ BMS_SingleCellVolt_88 : 311|16@0+ (0.001,0) [0|60] "V"  T_BOX
 SG_ BMS_SingleCellVolt_89 : 327|16@0+ (0.001,0) [0|60] "V"  T_BOX
 SG_ BMS_SingleCellVolt_90 : 343|16@0+ (0.001,0) [0|60] "V"  T_BOX
 SG_ BMS_SingleCellVolt_91 : 359|16@0+ (0.001,0) [0|60] "V"  T_BOX
 SG_ BMS_SingleCellVolt_92 : 375|16@0+ (0.001,0) [0|60] "V"  T_BOX
 SG_ BMS_SingleCellVolt_93 : 391|16@0+ (0.001,0) [0|60] "V"  T_BOX
 SG_ BMS_SingleCellVolt_94 : 407|16@0+ (0.001,0) [0|60] "V"  T_BOX
 SG_ BMS_SingleCellVolt_95 : 423|16@0+ (0.001,0) [0|60] "V"  T_BOX
 SG_ BMS_SingleCellVolt_96 : 439|16@0+ (0.001,0) [0|60] "V"  T_BOX

BO_ 981 BMS_FD9: 64 GW
 SG_ BMS_SingleCellVolt_97 : 7|16@0+ (0.001,0) [0|60] "V"  T_BOX
 SG_ BMS_SingleCellVolt_98 : 23|16@0+ (0.001,0) [0|60] "V"  T_BOX
 SG_ BMS_SingleCellVolt_99 : 39|16@0+ (0.001,0) [0|60] "V"  T_BOX
 SG_ BMS_SingleCellVolt_100 : 55|16@0+ (0.001,0) [0|60] "V"  T_BOX
 SG_ BMS_SingleCellVolt_101 : 71|16@0+ (0.001,0) [0|60] "V"  T_BOX
 SG_ BMS_SingleCellVolt_102 : 87|16@0+ (0.001,0) [0|60] "V"  T_BOX
 SG_ BMS_SingleCellVolt_103 : 103|16@0+ (0.001,0) [0|60] "V"  T_BOX
 SG_ BMS_SingleCellVolt_104 : 119|16@0+ (0.001,0) [0|60] "V"  T_BOX
 SG_ BMS_SingleCellVolt_105 : 135|16@0+ (0.001,0) [0|60] "V"  T_BOX
 SG_ BMS_SingleCellVolt_106 : 151|16@0+ (0.001,0) [0|60] "V"  T_BOX
 SG_ BMS_SingleCellVolt_107 : 167|16@0+ (0.001,0) [0|60] "V"  T_BOX
 SG_ BMS_SingleCellVolt_108 : 183|16@0+ (0.001,0) [0|60] "V"  T_BOX
 SG_ BMS_BattModuleTe_13 : 391|8@0+ (1,-40) [-40|125] "ÃƒÂ‚Ã‚Â°C"  T_BOX
 SG_ BMS_BattModuleTe_23 : 399|8@0+ (1,-40) [-40|125] "ÃƒÂ‚Ã‚Â°C"  T_BOX
 SG_ BMS_BattModuleTe_33 : 407|8@0+ (1,-40) [-40|125] "ÃƒÂ‚Ã‚Â°C"  T_BOX
 SG_ BMS_DTCNumber : 279|9@0+ (1,0) [0|501] ""  T_BOX
 SG_ BMS_BattModuleTe_91 : 263|8@0+ (1,-40) [-40|125] "ÃƒÂ‚Ã‚Â°C"  T_BOX
 SG_ BMS_BattModuleTe_92 : 271|8@0+ (1,-40) [-40|125] "ÃƒÂ‚Ã‚Â°C"  T_BOX
 SG_ BMS_DTCNumber1 : 335|9@0+ (1,0) [0|500] ""  T_BOX
 SG_ BMS_DTCNumber2 : 342|9@0+ (1,0) [0|500] ""  T_BOX

BO_ 1009 BMS30: 8 GW
 SG_ BMS30_0x3F1 : 0|64@1+ (1,0) [0|0] ""  HUT

BO_ 1010 BMS31: 8 GW
 SG_ BMS_CellVoltMin : 7|16@0+ (0.001,0) [0|5] "V"  T_BOX
 SG_ BMS_NumberCellVoltMin : 23|8@0+ (1,1) [1|108] ""  T_BOX
 SG_ BMS_CellMaxVolt : 31|16@0+ (0.001,0) [0|5] "V"  T_BOX
 SG_ BMS_NumberCellMaxVolt : 47|8@0+ (1,1) [1|108] ""  T_BOX
 SG_ BMS_CellBalanceSts : 55|2@0+ (1,0) [0|1] ""  T_BOX
 SG_ BMS_RlyCounterSts : 53|2@0+ (1,0) [0|3] ""  T_BOX
 SG_ BMS_SOH_R : 49|10@0+ (0.1,100) [100|200] "%"  T_BOX

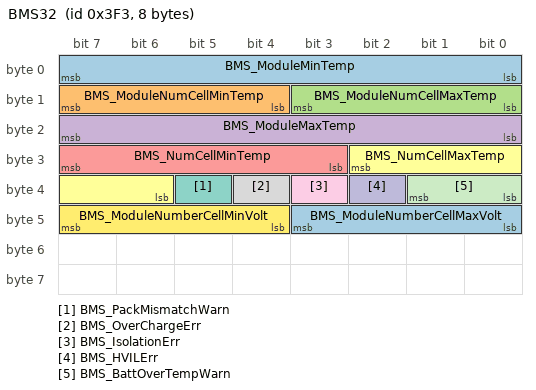
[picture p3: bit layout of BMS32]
BO_ 1011 BMS32: 8 GW
 SG_ BMS_ModuleMinTemp : 7|8@0+ (1,-40) [-40|90] "ÃƒÂ‚Ã‚ÂºC"  T_BOX
 SG_ BMS_ModuleNumCellMinTemp : 15|4@0+ (1,1) [1|9] ""  T_BOX
 SG_ BMS_ModuleNumCellMaxTemp : 11|4@0+ (1,1) [1|9] ""  T_BOX
 SG_ BMS_ModuleMaxTemp : 23|8@0+ (1,-40) [-40|90] "ÃƒÂ‚Ã‚ÂºC"  T_BOX
 SG_ BMS_NumCellMinTemp : 31|5@0+ (1,1) [1|18] "_"  T_BOX
 SG_ BMS_NumCellMaxTemp : 26|5@0+ (1,1) [1|18] "_"  T_BOX
 SG_ BMS_PackMismatchWarn : 37|1@0+ (1,0) [0|1] ""  T_BOX
 SG_ BMS_OverChargeErr : 36|1@0+ (1,0) [0|1] ""  T_BOX
 SG_ BMS_IsolationErr : 35|1@0+ (1,0) [0|1] ""  T_BOX
 SG_ BMS_HVILErr : 34|1@0+ (1,0) [0|1] ""  T_BOX
 SG_ BMS_BattOverTempWarn : 33|2@0+ (1,0) [0|3] ""  T_BOX
 SG_ BMS_ModuleNumberCellMinVolt : 47|4@0+ (1,1) [1|9] ""  T_BOX
 SG_ BMS_ModuleNumberCellMaxVolt : 43|4@0+ (1,1) [1|9] ""  T_BOX

BO_ 130 ECM4: 8 GW
 SG_ ECM4_0x82 : 0|64@1+ (1,0) [0|0] ""  HUT

BO_ 132 ECM7: 8 GW
 SG_ ECM7_0x84 : 0|64@1+ (1,0) [0|0] ""  HUT

BO_ 158 HCU_HC16: 8 GW
 SG_ HCU_HC16_0x9E : 0|64@1+ (1,0) [0|0] ""  HUT

BO_ 258 ECM9: 8 GW
 SG_ ECM9_0x102 : 0|64@1+ (1,0) [0|0] ""  HUT

BO_ 335 BMS65: 8 GW
 SG_ BMS65_0x14F : 0|64@1+ (1,0) [0|0] ""  HUT

BO_ 486 HUT36: 8 HUT
 SG_ HUT36_0x1E6 : 0|64@1+ (1,0) [0|0] "" Vector__XXX

BO_ 492 HUT37: 8 HUT
 SG_ HUT37_0x1EC : 0|64@1+ (1,0) [0|0] "" Vector__XXX

BO_ 724 ECM16: 8 GW
 SG_ ECM16_0x2D4 : 0|64@1+ (1,0) [0|0] ""  HUT

BO_ 763 VMDR1: 8 GW
 SG_ VMDR1_0x2FB : 0|64@1+ (1,0) [0|0] ""  HUT

BO_ 848 ECM24: 8 GW
 SG_ ECM24_0x350 : 0|64@1+ (1,0) [0|0] ""  HUT

BO_ 1560 DVR_Phy_Req: 8 Tester
 SG_ DVR_Phy_Req : 7|64@0+ (1,0) [0|1.84467440737096E+019] ""  GW,DVR

BO_ 1561 DVR_Phy_Resp: 8 DVR
 SG_ DVR_Phy_Resp : 7|64@0+ (1,0) [0|1.84467440737096E+019] ""  GW,Tester

BO_ 1303 DVR_NM: 8 DVR
 SG_ Destination_DVR_NM : 7|8@0+ (1,0) [0|255] ""  CEM,T_BOX,XBOX_D,HUT
 SG_ OpCode_DVR_NM : 15|8@0+ (1,0) [0|255] ""  CEM,T_BOX,XBOX_D,HUT

CM_ SG_ 53 PEPS_T_BOXAuth1 "PEPS anti-theft related signals,PEPS send to T_box";
CM_ SG_ 54 T_BOX_PEPSAuth1 "T_BOX_PEPS anti-theft authentication signals,T_box send to PEPS";
CM_ SG_ 70 PEPS_T_BOXAuth2 "Anti-theft authentication related signals,PEPSKBCMTBK send to T_Box";
CM_ SG_ 72 T_BOX_PEPSAuth2 "Anti-theft authentication related signals,T_BOX send to PEPSKBCMTBK";
CM_ SG_ 743 RFPosnLmpWorkCmd "Right front position lamp work command";
CM_ SG_ 743 LFPosnLmpWorkCmd "Left front position lamp work command";
CM_ SG_ 743 HiBeamWorkCmd "High Beam Command";
CM_ SG_ 743 LowBeamWorkCmd "Low Beam Command";
CM_ SG_ 743 RTurnLmpWorkCmd "Right turn lamp command request";
CM_ SG_ 743 LTurnLampWorkCmd "Left turn lamp command request";
CM_ SG_ 743 RDayRunngLmpWorkCmd "Right day run lamp work command";
CM_ SG_ 743 LDayRunngLmpWorkCmd "Left day run lamp work command";
CM_ SG_ 743 RFFogLmpWorkCmd "Right front fog lamp work command";
CM_ SG_ 743 LFFogLmpWorkCmd "Left front fog lamp work command";
CM_ SG_ 743 LicPlateLmpWorkCmd "License plate lamp work command";
CM_ SG_ 743 ReversLampWorkCmd "Revers Lamp Work  command";
CM_ SG_ 743 BrkLmpWorkCmd "Brake Lamp Work command";
CM_ SG_ 743 RFogLmpWorkCmd "rear  fog lamp work command";
CM_ SG_ 743 RRPosnLmpWorkCmd "Right rear position lamp work command";
CM_ SG_ 743 LRPosnLmpWorkCmd "Left rear position lamp work command";
CM_ SG_ 829 T_BOX_RemtLRTempSet "Remote Left  Rear side temperature setBD1_CAN:To AC";
CM_ SG_ 829 T_BOX_RemtRRTempSet "Remote  Right Rear side temperature set";
CM_ SG_ 829 T_BOX_RemtRearAutoCtrl "Remote Rear auto mode controlBD1_CAN:To AC";
CM_ SG_ 829 T_BOX_RemtSecRowLeSeatVentnLvlSe "Remote second row left seat ventilation set";
CM_ SG_ 829 T_BOX_RemtSecRowRiSeatVentnLvlSe "Remote second row right seat ventilation set";
CM_ SG_ 829 T_BOX_MbrMonrEnReq "Member monitoring enable request from TBOX";
CM_ SG_ 829 ReleAlarm_APP "Relieve  alarm form app";
CM_ SG_ 829 T_BOX_RemtSteerWheelHeatCtrl "Remote  Steer Wheel Heat ControlBD1-CAN To:CSA";
CM_ SG_ 829 T_BOX_AVPActvReq "T_BOX AVP Active RequestADAS_CAN:To IDC1.5";
CM_ SG_ 865 HCU_HVILSts "Hcu HVIL(High voltage interaction loop) statusTSP signal";
CM_ SG_ 865 HCU_BMSSleepCmd "sleep command during power down processTSP signal";
CM_ SG_ 865 HCU_P2MActHvDcCurr_RM "Actual HV DC(High Voltage Direct Current link) Current of P2MTSP signal";
CM_ SG_ 865 HCU_P2MActHvDcVolt_RM "Actual HV DC(High Voltage Direct Current) voltage of P2MTSP signal";
CM_ SG_ 865 HCU_DTCNumber1 "HCU DTC number";
CM_ SG_ 865 HCU_DTCNumber2 "HCU DTC number";
CM_ SG_ 865 HCU_MotorAmount_RM "Actual amount of E-motor for  remote monitorTSP signal";
CM_ SG_ 909 HCU_PowertrainSts_RM "Powertrain Status.";
CM_ SG_ 909 HCU_BrkPowflag_RM "Brake Power flag to Tbox";
CM_ SG_ 909 HCU_ChargSts_RM "Charging  statue";
CM_ SG_ 909 HCU_PTDrvMod_RM "Powertrain current drive mode";
CM_ SG_ 909 HCU_Powerflag_RM "Power flag";
CM_ SG_ 909 HCU_AccelPedalPosn_Diag_RM "Physical acceleration pedal position.
it represents the physical value of acceleration pedal even in CCACC case, in which case normal acceleration pedal is replaced by virtual pedal position.";
CM_ SG_ 909 HCU_BrkPedalSts_RM "indicates the brake pedal is pressed or not or incorrect for
plausibility check.";
CM_ SG_ 909 HCU_WakeUpSrc "the wake up source of power up";
CM_ SG_ 909 HCU_CurrHybSysSts "Current vehicle hybrid system status";
CM_ SG_ 937 BMS_ISC_ROhm_Warn "Battery Internal short circuit of resistance";
CM_ SG_ 937 BMS_ISC_SOC_Warn "Battery Internal short circuit of SOC";
CM_ SG_ 937 BMS_ISC_T_Warn "Battery Internal short circuit of Temperature";
CM_ SG_ 937 BMS_ISC_V_Warn "Battery Internal short circuit of Voltage";
CM_ SG_ 957 DCDC_Tempwarning_RM "DCDC temperapure warning for  remote monitor";
CM_ SG_ 957 DCDC_ActSts_RM "DCDC states";
CM_ SG_ 957 DCDC_FailStswarning_RM "DCDC state warning for  remote monitor";
CM_ SG_ 963 P2M_MotorSerNumber_RM "Actual serial number of E-motor for  remote monitor";
CM_ SG_ 963 P2M_InvActTemp_RM "Actual Virtual Junction Temperature state of hottest Inverter Power-Semiconductor";
CM_ SG_ 963 P2M_ActSpd_RM "Actual mechanical speed of EM(Electric Motor)";
CM_ SG_ 963 P2M_ActTrq_RM "Actual torque at EM(Electric Motor)   shaft";
CM_ SG_ 967 P2M_ActTemp_RM "Actual Temperature of hottest sensor element in EM(Electric Motor)  Winding";
CM_ SG_ 967 P2M_OperMode_RM "Actual operation mode of Actuation Motor";
CM_ SG_ 967 P2M_InvTempwarning_RM "Actual Temperature warrning of hottest sensor element in EM Inverter(Electric Motor)  Winding";
CM_ SG_ 967 P2M_Tempwarning_RM "Actual Temperature warrning of hottest sensor element in EM(Electric Motor)  Winding";
CM_ SG_ 976 BMS_BattTempMax "Battery max temperature of module temperature";
CM_ SG_ 976 BMS_BattTempMin "Battery min temperature of module temperature";
CM_ SG_ 977 BMS_SingleCellVolt_1 "Single cell vlotage of power battery1";
CM_ SG_ 977 BMS_SingleCellVolt_2 "Single cell vlotage of power battery2";
CM_ SG_ 977 BMS_SingleCellVolt_3 "Single cell vlotage of power battery3";
CM_ SG_ 977 BMS_SingleCellVolt_4 "Single cell vlotage of power battery4";
CM_ SG_ 977 BMS_SingleCellVolt_5 "Single cell vlotage of power battery5";
CM_ SG_ 977 BMS_SingleCellVolt_6 "Single cell vlotage of power battery6";
CM_ SG_ 977 BMS_SingleCellVolt_7 "Single cell vlotage of power battery7";
CM_ SG_ 977 BMS_SingleCellVolt_8 "Single cell vlotage of power battery8";
CM_ SG_ 977 BMS_SingleCellVolt_9 "Single cell vlotage of power battery9";
CM_ SG_ 977 BMS_SingleCellVolt_10 "Single cell vlotage of power battery10";
CM_ SG_ 977 BMS_SingleCellVolt_11 "Single cell vlotage of power battery11";
CM_ SG_ 977 BMS_SingleCellVolt_12 "Single cell vlotage of power battery12";
CM_ SG_ 977 BMS_BattModuleTe_11 "module temperature of power battery_1";
CM_ SG_ 977 BMS_BattModuleTe_12 "module temperature of power battery_1";
CM_ SG_ 977 BMS_BattModuleTe_21 "module temperature of power battery_2";
CM_ SG_ 977 BMS_BattModuleTe_22 "module temperature of power battery_2";
CM_ SG_ 977 BMS_BattModuleTe_31 "module temperature of power battery_3";
CM_ SG_ 977 BMS_BattModuleTe_32 "module temperature of power battery_3";
CM_ SG_ 977 BMS_BattModuleTe_41 "module temperature of power battery_4";
CM_ SG_ 977 BMS_BattModuleTe_42 "module temperature of power battery_4";
CM_ SG_ 977 BMS_BattModuleTe_51 "module temperature of power battery_5";
CM_ SG_ 977 BMS_BattModuleTe_52 "module temperature of power battery_5";
CM_ SG_ 977 BMS_BattModuleTe_61 "module temperature of power battery_6";
CM_ SG_ 977 BMS_BattModuleTe_62 "module temperature of power battery_6";
CM_ SG_ 977 BMS_BattModuleTe_71 "module temperature of power battery_7";
CM_ SG_ 977 BMS_BattModuleTe_72 "module temperature of power battery_7";
CM_ SG_ 977 BMS_BattModuleTe_81 "module temperature of power battery_8";
CM_ SG_ 977 BMS_BattModuleTe_82 "module temperature of power battery_8";
CM_ SG_ 978 BMS_SingleCellVolt_13 "Single cell vlotage of power battery13";
CM_ SG_ 978 BMS_SingleCellVolt_14 "Single cell vlotage of power battery14";
CM_ SG_ 978 BMS_SingleCellVolt_15 "Single cell vlotage of power battery15";
CM_ SG_ 978 BMS_SingleCellVolt_16 "Single cell vlotage of power battery16";
CM_ SG_ 978 BMS_SingleCellVolt_17 "Single cell vlotage of power battery17";
CM_ SG_ 978 BMS_SingleCellVolt_18 "Single cell vlotage of power battery18";
CM_ SG_ 978 BMS_SingleCellVolt_19 "Single cell vlotage of power battery19";
CM_ SG_ 978 BMS_SingleCellVolt_20 "Single cell vlotage of power battery20";
CM_ SG_ 978 BMS_SingleCellVolt_21 "Single cell vlotage of power battery21";
CM_ SG_ 978 BMS_SingleCellVolt_22 "Single cell vlotage of power battery22";
CM_ SG_ 978 BMS_SingleCellVolt_23 "Single cell vlotage of power battery23";
CM_ SG_ 978 BMS_SingleCellVolt_24 "Single cell vlotage of power battery24";
CM_ SG_ 978 BMS_SingleCellVolt_25 "Single cell vlotage of power battery25";
CM_ SG_ 978 BMS_SingleCellVolt_26 "Single cell vlotage of power battery26";
CM_ SG_ 978 BMS_SingleCellVolt_27 "Single cell vlotage of power battery27";
CM_ SG_ 978 BMS_SingleCellVolt_28 "Single cell vlotage of power battery28";
CM_ SG_ 978 BMS_SingleCellVolt_29 "Single cell vlotage of power battery29";
CM_ SG_ 978 BMS_SingleCellVolt_30 "Single cell vlotage of power battery30";
CM_ SG_ 978 BMS_SingleCellVolt_31 "Single cell vlotage of power battery31";
CM_ SG_ 978 BMS_SingleCellVolt_32 "Single cell vlotage of power battery32";
CM_ SG_ 978 BMS_SingleCellVolt_33 "Single cell vlotage of power battery33";
CM_ SG_ 978 BMS_SingleCellVolt_34 "Single cell vlotage of power battery34";
CM_ SG_ 978 BMS_SingleCellVolt_35 "Single cell vlotage of power battery35";
CM_ SG_ 978 BMS_SingleCellVolt_36 "Single cell vlotage of power battery36";
CM_ SG_ 978 BMS_SingleCellVolt_37 "Single cell vlotage of power battery37";
CM_ SG_ 978 BMS_SingleCellVolt_38 "Single cell vlotage of power battery38";
CM_ SG_ 978 BMS_SingleCellVolt_39 "Single cell vlotage of power battery39";
CM_ SG_ 978 BMS_SingleCellVolt_40 "Single cell vlotage of power battery40";
CM_ SG_ 979 BMS_SingleCellVolt_41 "Single cell vlotage of power battery41";
CM_ SG_ 979 BMS_SingleCellVolt_42 "Single cell vlotage of power battery42";
CM_ SG_ 979 BMS_SingleCellVolt_43 "Single cell vlotage of power battery43";
CM_ SG_ 979 BMS_SingleCellVolt_44 "Single cell vlotage of power battery44";
CM_ SG_ 979 BMS_SingleCellVolt_45 "Single cell vlotage of power battery45";
CM_ SG_ 979 BMS_SingleCellVolt_46 "Single cell vlotage of power battery46";
CM_ SG_ 979 BMS_SingleCellVolt_47 "Single cell vlotage of power battery47";
CM_ SG_ 979 BMS_SingleCellVolt_48 "Single cell vlotage of power battery48";
CM_ SG_ 979 BMS_SingleCellVolt_49 "Single cell vlotage of power battery49";
CM_ SG_ 979 BMS_SingleCellVolt_50 "Single cell vlotage of power battery50";
CM_ SG_ 979 BMS_SingleCellVolt_51 "Single cell vlotage of power battery51";
CM_ SG_ 979 BMS_SingleCellVolt_52 "Single cell vlotage of power battery52";
CM_ SG_ 979 BMS_SingleCellVolt_53 "Single cell vlotage of power battery53";
CM_ SG_ 979 BMS_SingleCellVolt_54 "Single cell vlotage of power battery54";
CM_ SG_ 979 BMS_SingleCellVolt_55 "Single cell vlotage of power battery55";
CM_ SG_ 979 BMS_SingleCellVolt_56 "Single cell vlotage of power battery56";
CM_ SG_ 979 BMS_SingleCellVolt_57 "Single cell vlotage of power battery57";
CM_ SG_ 979 BMS_SingleCellVolt_58 "Single cell vlotage of power battery58";
CM_ SG_ 979 BMS_SingleCellVolt_59 "Single cell vlotage of power battery59";
CM_ SG_ 979 BMS_SingleCellVolt_60 "Single cell vlotage of power battery60";
CM_ SG_ 979 BMS_SingleCellVolt_61 "Single cell vlotage of power battery61";
CM_ SG_ 979 BMS_SingleCellVolt_62 "Single cell vlotage of power battery62";
CM_ SG_ 979 BMS_SingleCellVolt_63 "Single cell vlotage of power battery63";
CM_ SG_ 979 BMS_SingleCellVolt_64 "Single cell vlotage of power battery64";
CM_ SG_ 979 BMS_SingleCellVolt_65 "Single cell vlotage of power battery65";
CM_ SG_ 979 BMS_SingleCellVolt_66 "Single cell vlotage of power battery66";
CM_ SG_ 979 BMS_SingleCellVolt_67 "Single cell vlotage of power battery67";
CM_ SG_ 979 BMS_SingleCellVolt_68 "Single cell vlotage of power battery68";
CM_ SG_ 980 BMS_SingleCellVolt_69 "Single cell vlotage of power battery69";
CM_ SG_ 980 BMS_SingleCellVolt_70 "Single cell vlotage of power battery70";
CM_ SG_ 980 BMS_SingleCellVolt_71 "Single cell vlotage of power battery71";
CM_ SG_ 980 BMS_SingleCellVolt_72 "Single cell vlotage of power battery72";
CM_ SG_ 980 BMS_SingleCellVolt_73 "Single cell vlotage of power battery73";
CM_ SG_ 980 BMS_SingleCellVolt_74 "Single cell vlotage of power battery74";
CM_ SG_ 980 BMS_SingleCellVolt_75 "Single cell vlotage of power battery75";
CM_ SG_ 980 BMS_SingleCellVolt_76 "Single cell vlotage of power battery76";
CM_ SG_ 980 BMS_SingleCellVolt_77 "Single cell vlotage of power battery77";
CM_ SG_ 980 BMS_SingleCellVolt_78 "Single cell vlotage of power battery78";
CM_ SG_ 980 BMS_SingleCellVolt_79 "Single cell vlotage of power battery79";
CM_ SG_ 980 BMS_SingleCellVolt_80 "Single cell vlotage of power battery80";
CM_ SG_ 980 BMS_SingleCellVolt_81 "Single cell vlotage of power battery81";
CM_ SG_ 980 BMS_SingleCellVolt_82 "Single cell vlotage of power battery82";
CM_ SG_ 980 BMS_SingleCellVolt_83 "Single cell vlotage of power battery83";
CM_ SG_ 980 BMS_SingleCellVolt_84 "Single cell vlotage of power battery84";
CM_ SG_ 980 BMS_SingleCellVolt_85 "Single cell vlotage of power battery85";
CM_ SG_ 980 BMS_SingleCellVolt_86 "Single cell vlotage of power battery86";
CM_ SG_ 980 BMS_SingleCellVolt_87 "Single cell vlotage of power battery87";
CM_ SG_ 980 BMS_SingleCellVolt_88 "Single cell vlotage of power battery88";
CM_ SG_ 980 BMS_SingleCellVolt_89 "Single cell vlotage of power battery89";
CM_ SG_ 980 BMS_SingleCellVolt_90 "Single cell vlotage of power battery90";
CM_ SG_ 980 BMS_SingleCellVolt_91 "Single cell vlotage of power battery91";
CM_ SG_ 980 BMS_SingleCellVolt_92 "Single cell vlotage of power battery92";
CM_ SG_ 980 BMS_SingleCellVolt_93 "Single cell vlotage of power battery93";
CM_ SG_ 980 BMS_SingleCellVolt_94 "Single cell vlotage of power battery94";
CM_ SG_ 980 BMS_SingleCellVolt_95 "Single cell vlotage of power battery95";
CM_ SG_ 980 BMS_SingleCellVolt_96 "Single cell vlotage of power battery96";
CM_ SG_ 981 BMS_SingleCellVolt_97 "Single cell vlotage of power battery97";
CM_ SG_ 981 BMS_SingleCellVolt_98 "Single cell vlotage of power battery98";
CM_ SG_ 981 BMS_SingleCellVolt_99 "Single cell vlotage of power battery99";
CM_ SG_ 981 BMS_SingleCellVolt_100 "Single cell vlotage of power battery100";
CM_ SG_ 981 BMS_SingleCellVolt_101 "Single cell vlotage of power battery101";
CM_ SG_ 981 BMS_SingleCellVolt_102 "Single cell vlotage of power battery102";
CM_ SG_ 981 BMS_SingleCellVolt_103 "Single cell vlotage of power battery103";
CM_ SG_ 981 BMS_SingleCellVolt_104 "Single cell vlotage of power battery104";
CM_ SG_ 981 BMS_SingleCellVolt_105 "Single cell vlotage of power battery105";
CM_ SG_ 981 BMS_SingleCellVolt_106 "Single cell vlotage of power battery106";
CM_ SG_ 981 BMS_SingleCellVolt_107 "Single cell vlotage of power battery107";
CM_ SG_ 981 BMS_SingleCellVolt_108 "Single cell vlotage of power battery108";
CM_ SG_ 981 BMS_BattModuleTe_13 "module temperature of power battery_1";
CM_ SG_ 981 BMS_BattModuleTe_23 "module temperature of power battery_2";
CM_ SG_ 981 BMS_BattModuleTe_33 "module temperature of power battery_3";
CM_ SG_ 981 BMS_DTCNumber "BMS DTC Number
ÃƒÂ§Ã‚Â”Ã‚ÂµÃƒÂ¦Ã‚Â±Ã‚Â ÃƒÂ¤Ã‚Â¸Ã‚ÂŠÃƒÂ¦Ã‚ÂŠÃ‚Â¥ÃƒÂ§Ã‚ÂšÃ‚Â„DTCÃƒÂ§Ã‚ÂŠÃ‚Â¶ÃƒÂ¦Ã‚Â€Ã‚Â";
CM_ SG_ 981 BMS_BattModuleTe_91 "module temperature of power battery_9";
CM_ SG_ 981 BMS_BattModuleTe_92 "module temperature of power battery_9";
CM_ SG_ 981 BMS_DTCNumber1 "BMS_DTCNumber1";
CM_ SG_ 981 BMS_DTCNumber2 "BMS_DTCNumber2";
CM_ SG_ 1010 BMS_CellVoltMin "minimal voltage of cell";
CM_ SG_ 1010 BMS_NumberCellVoltMin "number of minimal voltage of cell";
CM_ SG_ 1010 BMS_CellMaxVolt "maximal voltage of cell";
CM_ SG_ 1010 BMS_NumberCellMaxVolt "number of maximal voltage of cell";
CM_ SG_ 1010 BMS_CellBalanceSts "cell balance state";
CM_ SG_ 1010 BMS_RlyCounterSts "BMS relay counter status";
CM_ SG_ 1010 BMS_SOH_R "SOH( resistance) value";
CM_ SG_ 1011 BMS_ModuleMinTemp "minimal temperature of module";
CM_ SG_ 1011 BMS_ModuleNumCellMinTemp "module number of minimal temperature of cell";
CM_ SG_ 1011 BMS_ModuleNumCellMaxTemp "module number of maximal temperature of cell";
CM_ SG_ 1011 BMS_ModuleMaxTemp "maximal temperature of module";
CM_ SG_ 1011 BMS_NumCellMinTemp "number of minimal temperature of Cell";
CM_ SG_ 1011 BMS_NumCellMaxTemp "number of maximal temperature of Cell";
CM_ SG_ 1011 BMS_PackMismatchWarn "Pack mismatch warning of module";
CM_ SG_ 1011 BMS_OverChargeErr "Battery over charging error";
CM_ SG_ 1011 BMS_IsolationErr "Isolation resistance error";
CM_ SG_ 1011 BMS_HVILErr "HVIL(High voltage interaction loop) error";
CM_ SG_ 1011 BMS_BattOverTempWarn "battery temperature is too higher";
CM_ SG_ 1011 BMS_ModuleNumberCellMinVolt "module number of minimal voltage of cell";
CM_ SG_ 1011 BMS_ModuleNumberCellMaxVolt "module number of minimal voltage of cell";
BA_DEF_ BO_  "DiagRequest" ENUM  "No","Yes";
BA_DEF_ BO_  "DiagResponse" ENUM  "No","Yes";
BA_DEF_ BO_  "DiagState" ENUM  "No","Yes";
BA_DEF_ BO_  "GenMsgCycleTime" INT 0 65535;
BA_DEF_ BO_  "GenMsgCycleTimeFast" INT 0 65535;
BA_DEF_ BO_  "GenMsgILSupport" ENUM  "No","Yes";
BA_DEF_ BO_  "GenMsgNrOfRepetition" INT 0 65535;
BA_DEF_ BO_  "GenMsgSendType" ENUM  "Cyclic","CyclicAndSpontanX","Event";
BA_DEF_ BO_  "NmAsrMessage" ENUM  "No","Yes";
BA_DEF_ BO_  "OriginFrame" STRING ;
BA_DEF_ BO_  "SCP_AuthInfoTxLength" INT 0 512;
BA_DEF_ BO_  "SCP_DataId" INT 0 65535;
BA_DEF_ BO_  "SCP_FreshnessValueLength" INT 0 512;
BA_DEF_ BO_  "SCP_FreshnessValueTxLength" INT 0 512;
BA_DEF_ BO_  "SC_Message" ENUM  "NO","YES";
BA_DEF_ BO_  "VFrameFormat" ENUM  "StandardCAN","ExtendedCAN","reserved","reserved","reserved","reserved","reserved","reserved","reserved","reserved","reserved","reserved","reserved","reserved","StandardCAN_FD","ExtendedCAN_FD";
BA_DEF_ SG_  "GenSigCycleTime" INT 0 65535;
BA_DEF_ SG_  "GenSigSendType" ENUM  "Cyclic","OnWrite","OnWriteWithRepetition","OnChange","OnChangeWithRepetition","NotUsed","NotUsed","NoSigSendType";
BA_DEF_ SG_  "GenSigStartValue" FLOAT 0 100000000000;
BA_DEF_ SG_  "Match" STRING ;
BA_DEF_ SG_  "Origin" STRING ;
BA_DEF_ SG_  "TransparentInitValue" STRING ;
BA_DEF_ BU_  "NmAsrNode" ENUM  "No","Yes";
BA_DEF_  "BusType" STRING ;
BA_DEF_  "DBName" STRING ;
BA_DEF_  "NmAsrBaseAddress" HEX 1024 536870911;
BA_DEF_  "NmAsrCanMsgCycleTime" INT 1 65535;
BA_DEF_  "NmAsrMessageCount" INT 1 256;
BA_DEF_  "NmAsrRepeatMessageTime" INT 1 65535;
BA_DEF_  "NmAsrTimeoutTime" INT 1 65535;
BA_DEF_  "NmAsrWaitBusSleepTime" INT 1 65535;
BA_DEF_  "NmType" STRING ;
BA_DEF_ SG_  "SystemSignalLongSymbol" STRING ;
BA_DEF_DEF_  "DiagRequest" "No";
BA_DEF_DEF_  "DiagResponse" "No";
BA_DEF_DEF_  "DiagState" "No";
BA_DEF_DEF_  "GenMsgCycleTime" 0;
BA_DEF_DEF_  "GenMsgCycleTimeFast" 0;
BA_DEF_DEF_  "GenMsgILSupport" "No";
BA_DEF_DEF_  "GenMsgNrOfRepetition" 0;
BA_DEF_DEF_  "GenMsgSendType" "Cyclic";
BA_DEF_DEF_  "NmAsrMessage" "No";
BA_DEF_DEF_  "OriginFrame" "";
BA_DEF_DEF_  "SCP_AuthInfoTxLength" 0;
BA_DEF_DEF_  "SCP_DataId" 0;
BA_DEF_DEF_  "SCP_FreshnessValueLength" 0;
BA_DEF_DEF_  "SCP_FreshnessValueTxLength" 0;
BA_DEF_DEF_  "SC_Message" "NO";
BA_DEF_DEF_  "VFrameFormat" "";
BA_DEF_DEF_  "GenSigCycleTime" 0;
BA_DEF_DEF_  "GenSigSendType" "Cyclic";
BA_DEF_DEF_  "GenSigStartValue" 0;
BA_DEF_DEF_  "Match" "";
BA_DEF_DEF_  "Origin" "";
BA_DEF_DEF_  "TransparentInitValue" "";
BA_DEF_DEF_  "NmAsrNode" "Yes";
BA_DEF_DEF_  "BusType" "";
BA_DEF_DEF_  "DBName" "B30_for_SC_CAN_V3_2";
BA_DEF_DEF_  "NmAsrBaseAddress" 1280;
BA_DEF_DEF_  "NmAsrCanMsgCycleTime" 500;
BA_DEF_DEF_  "NmAsrMessageCount" 100;
BA_DEF_DEF_  "NmAsrRepeatMessageTime" 1500;
BA_DEF_DEF_  "NmAsrTimeoutTime" 2000;
BA_DEF_DEF_  "NmAsrWaitBusSleepTime" 5000;
BA_DEF_DEF_  "NmType" "NmAsr";
BA_DEF_DEF_  "SystemSignalLongSymbol" "";
BA_ "BusType" "CAN FD";
BA_ "SC_Message" BO_ 51 1;
BA_ "SCP_FreshnessValueTxLength" BO_ 51 16;
BA_ "SCP_FreshnessValueLength" BO_ 51 64;
BA_ "SCP_DataId" BO_ 51 51;
BA_ "SCP_AuthInfoTxLength" BO_ 51 48;
BA_ "OriginFrame" BO_ 51 "fuel,ev";
BA_ "GenMsgSendType" BO_ 51 2;
BA_ "GenMsgNrOfRepetition" BO_ 51 5;
BA_ "GenMsgILSupport" BO_ 51 1;
BA_ "GenMsgCycleTimeFast" BO_ 51 20;
BA_ "VFrameFormat" BO_ 51 14;
BA_ "OriginFrame" BO_ 68 "fuel,ev";
BA_ "GenMsgSendType" BO_ 68 2;
BA_ "GenMsgNrOfRepetition" BO_ 68 5;
BA_ "GenMsgILSupport" BO_ 68 1;
BA_ "GenMsgCycleTimeFast" BO_ 68 50;
BA_ "VFrameFormat" BO_ 68 14;
BA_ "OriginFrame" BO_ 74 "fuel,ev";
BA_ "GenMsgSendType" BO_ 74 2;
BA_ "GenMsgNrOfRepetition" BO_ 74 5;
BA_ "GenMsgILSupport" BO_ 74 1;
BA_ "GenMsgCycleTimeFast" BO_ 74 50;
BA_ "VFrameFormat" BO_ 74 14;
BA_ "OriginFrame" BO_ 86 "fuel,ev";
BA_ "GenMsgSendType" BO_ 86 2;
BA_ "GenMsgNrOfRepetition" BO_ 86 5;
BA_ "GenMsgILSupport" BO_ 86 1;
BA_ "GenMsgCycleTimeFast" BO_ 86 20;
BA_ "VFrameFormat" BO_ 86 14;
BA_ "OriginFrame" BO_ 161 "fuel,ev";
BA_ "GenMsgILSupport" BO_ 161 1;
BA_ "GenMsgCycleTime" BO_ 161 10;
BA_ "VFrameFormat" BO_ 161 14;
BA_ "OriginFrame" BO_ 166 "fuel,ev";
BA_ "GenMsgILSupport" BO_ 166 1;
BA_ "GenMsgCycleTime" BO_ 166 10;
BA_ "VFrameFormat" BO_ 166 14;
BA_ "OriginFrame" BO_ 200 "fuel,ev";
BA_ "GenMsgILSupport" BO_ 200 1;
BA_ "GenMsgCycleTime" BO_ 200 10;
BA_ "VFrameFormat" BO_ 200 14;
BA_ "OriginFrame" BO_ 241 "fuel,ev";
BA_ "GenMsgILSupport" BO_ 241 1;
BA_ "GenMsgCycleTime" BO_ 241 10;
BA_ "VFrameFormat" BO_ 241 14;
BA_ "OriginFrame" BO_ 265 "fuel,ev";
BA_ "GenMsgILSupport" BO_ 265 1;
BA_ "GenMsgCycleTime" BO_ 265 20;
BA_ "VFrameFormat" BO_ 265 14;
BA_ "OriginFrame" BO_ 273 "fuel,ev";
BA_ "GenMsgILSupport" BO_ 273 1;
BA_ "GenMsgCycleTime" BO_ 273 10;
BA_ "VFrameFormat" BO_ 273 14;
BA_ "OriginFrame" BO_ 288 "fuel,ev";
BA_ "GenMsgILSupport" BO_ 288 1;
BA_ "GenMsgCycleTime" BO_ 288 20;
BA_ "VFrameFormat" BO_ 288 14;
BA_ "SC_Message" BO_ 311 1;
BA_ "SCP_FreshnessValueTxLength" BO_ 311 16;
BA_ "SCP_FreshnessValueLength" BO_ 311 64;
BA_ "SCP_DataId" BO_ 311 311;
BA_ "SCP_AuthInfoTxLength" BO_ 311 48;
BA_ "OriginFrame" BO_ 311 "fuel,ev";
BA_ "GenMsgILSupport" BO_ 311 1;
BA_ "GenMsgCycleTime" BO_ 311 20;
BA_ "VFrameFormat" BO_ 311 14;
BA_ "OriginFrame" BO_ 327 "fuel,ev";
BA_ "GenMsgILSupport" BO_ 327 1;
BA_ "GenMsgCycleTime" BO_ 327 20;
BA_ "VFrameFormat" BO_ 327 14;
BA_ "OriginFrame" BO_ 338 "fuel,ev";
BA_ "GenMsgILSupport" BO_ 338 1;
BA_ "GenMsgCycleTime" BO_ 338 20;
BA_ "VFrameFormat" BO_ 338 14;
BA_ "OriginFrame" BO_ 347 "fuel,ev";
BA_ "GenMsgILSupport" BO_ 347 1;
BA_ "GenMsgCycleTime" BO_ 347 20;
BA_ "VFrameFormat" BO_ 347 14;
BA_ "OriginFrame" BO_ 350 "fuel,ev";
BA_ "GenMsgILSupport" BO_ 350 1;
BA_ "GenMsgCycleTime" BO_ 350 20;
BA_ "VFrameFormat" BO_ 350 14;
BA_ "OriginFrame" BO_ 357 "fuel,ev";
BA_ "GenMsgILSupport" BO_ 357 1;
BA_ "GenMsgCycleTime" BO_ 357 20;
BA_ "VFrameFormat" BO_ 357 14;
BA_ "OriginFrame" BO_ 363 "fuel,ev";
BA_ "GenMsgILSupport" BO_ 363 1;
BA_ "GenMsgCycleTime" BO_ 363 20;
BA_ "VFrameFormat" BO_ 363 14;
BA_ "OriginFrame" BO_ 367 "fuel,ev";
BA_ "GenMsgILSupport" BO_ 367 1;
BA_ "GenMsgCycleTime" BO_ 367 20;
BA_ "VFrameFormat" BO_ 367 14;
BA_ "OriginFrame" BO_ 368 "fuel,ev";
BA_ "GenMsgILSupport" BO_ 368 1;
BA_ "GenMsgCycleTime" BO_ 368 20;
BA_ "VFrameFormat" BO_ 368 14;
BA_ "OriginFrame" BO_ 395 "fuel,ev";
BA_ "GenMsgILSupport" BO_ 395 1;
BA_ "GenMsgCycleTime" BO_ 395 20;
BA_ "VFrameFormat" BO_ 395 14;
BA_ "OriginFrame" BO_ 411 "fuel,ev";
BA_ "GenMsgILSupport" BO_ 411 1;
BA_ "GenMsgCycleTime" BO_ 411 50;
BA_ "VFrameFormat" BO_ 411 14;
BA_ "SC_Message" BO_ 412 1;
BA_ "SCP_FreshnessValueTxLength" BO_ 412 16;
BA_ "SCP_FreshnessValueLength" BO_ 412 64;
BA_ "SCP_DataId" BO_ 412 412;
BA_ "SCP_AuthInfoTxLength" BO_ 412 48;
BA_ "OriginFrame" BO_ 412 "fuel,ev";
BA_ "GenMsgILSupport" BO_ 412 1;
BA_ "GenMsgCycleTime" BO_ 412 50;
BA_ "VFrameFormat" BO_ 412 14;
BA_ "OriginFrame" BO_ 415 "fuel,ev";
BA_ "GenMsgILSupport" BO_ 415 1;
BA_ "GenMsgCycleTime" BO_ 415 50;
BA_ "VFrameFormat" BO_ 415 14;
BA_ "OriginFrame" BO_ 465 "fuel,ev";
BA_ "GenMsgSendType" BO_ 465 2;
BA_ "GenMsgNrOfRepetition" BO_ 465 5;
BA_ "GenMsgILSupport" BO_ 465 1;
BA_ "GenMsgCycleTimeFast" BO_ 465 50;
BA_ "VFrameFormat" BO_ 465 14;
BA_ "OriginFrame" BO_ 473 "fuel,ev";
BA_ "GenMsgSendType" BO_ 473 2;
BA_ "GenMsgNrOfRepetition" BO_ 473 5;
BA_ "GenMsgILSupport" BO_ 473 1;
BA_ "GenMsgCycleTimeFast" BO_ 473 20;
BA_ "VFrameFormat" BO_ 473 14;
BA_ "OriginFrame" BO_ 474 "fuel,ev";
BA_ "GenMsgSendType" BO_ 474 2;
BA_ "GenMsgNrOfRepetition" BO_ 474 5;
BA_ "GenMsgILSupport" BO_ 474 1;
BA_ "GenMsgCycleTimeFast" BO_ 474 50;
BA_ "VFrameFormat" BO_ 474 14;
BA_ "OriginFrame" BO_ 475 "fuel,ev";
BA_ "GenMsgSendType" BO_ 475 2;
BA_ "GenMsgNrOfRepetition" BO_ 475 5;
BA_ "GenMsgILSupport" BO_ 475 1;
BA_ "GenMsgCycleTimeFast" BO_ 475 50;
BA_ "VFrameFormat" BO_ 475 14;
BA_ "OriginFrame" BO_ 476 "fuel,ev";
BA_ "GenMsgSendType" BO_ 476 2;
BA_ "GenMsgNrOfRepetition" BO_ 476 5;
BA_ "GenMsgILSupport" BO_ 476 1;
BA_ "GenMsgCycleTimeFast" BO_ 476 50;
BA_ "VFrameFormat" BO_ 476 14;
BA_ "OriginFrame" BO_ 477 "fuel,ev";
BA_ "GenMsgSendType" BO_ 477 2;
BA_ "GenMsgNrOfRepetition" BO_ 477 5;
BA_ "GenMsgILSupport" BO_ 477 1;
BA_ "GenMsgCycleTimeFast" BO_ 477 50;
BA_ "VFrameFormat" BO_ 477 14;
BA_ "OriginFrame" BO_ 479 "fuel,ev";
BA_ "GenMsgSendType" BO_ 479 2;
BA_ "GenMsgNrOfRepetition" BO_ 479 5;
BA_ "GenMsgILSupport" BO_ 479 1;
BA_ "GenMsgCycleTimeFast" BO_ 479 20;
BA_ "VFrameFormat" BO_ 479 14;
BA_ "OriginFrame" BO_ 481 "fuel,ev";
BA_ "GenMsgSendType" BO_ 481 2;
BA_ "GenMsgNrOfRepetition" BO_ 481 5;
BA_ "GenMsgILSupport" BO_ 481 1;
BA_ "GenMsgCycleTimeFast" BO_ 481 20;
BA_ "VFrameFormat" BO_ 481 14;
BA_ "OriginFrame" BO_ 485 "fuel,ev";
BA_ "GenMsgSendType" BO_ 485 2;
BA_ "GenMsgNrOfRepetition" BO_ 485 5;
BA_ "GenMsgILSupport" BO_ 485 1;
BA_ "GenMsgCycleTimeFast" BO_ 485 50;
BA_ "VFrameFormat" BO_ 485 14;
BA_ "OriginFrame" BO_ 487 "fuel,ev";
BA_ "GenMsgSendType" BO_ 487 2;
BA_ "GenMsgNrOfRepetition" BO_ 487 5;
BA_ "GenMsgILSupport" BO_ 487 1;
BA_ "GenMsgCycleTimeFast" BO_ 487 50;
BA_ "VFrameFormat" BO_ 487 14;
BA_ "OriginFrame" BO_ 489 "fuel,ev";
BA_ "GenMsgSendType" BO_ 489 2;
BA_ "GenMsgNrOfRepetition" BO_ 489 5;
BA_ "GenMsgILSupport" BO_ 489 1;
BA_ "GenMsgCycleTimeFast" BO_ 489 50;
BA_ "VFrameFormat" BO_ 489 14;
BA_ "OriginFrame" BO_ 491 "fuel,ev";
BA_ "GenMsgSendType" BO_ 491 2;
BA_ "GenMsgNrOfRepetition" BO_ 491 5;
BA_ "GenMsgILSupport" BO_ 491 1;
BA_ "GenMsgCycleTimeFast" BO_ 491 50;
BA_ "VFrameFormat" BO_ 491 14;
BA_ "OriginFrame" BO_ 493 "fuel,ev";
BA_ "GenMsgSendType" BO_ 493 2;
BA_ "GenMsgNrOfRepetition" BO_ 493 6;
BA_ "GenMsgILSupport" BO_ 493 1;
BA_ "GenMsgCycleTimeFast" BO_ 493 50;
BA_ "VFrameFormat" BO_ 493 14;
BA_ "SC_Message" BO_ 494 1;
BA_ "SCP_FreshnessValueTxLength" BO_ 494 16;
BA_ "SCP_FreshnessValueLength" BO_ 494 64;
BA_ "SCP_DataId" BO_ 494 494;
BA_ "SCP_AuthInfoTxLength" BO_ 494 48;
BA_ "OriginFrame" BO_ 494 "fuel,ev";
BA_ "GenMsgSendType" BO_ 494 2;
BA_ "GenMsgNrOfRepetition" BO_ 494 5;
BA_ "GenMsgILSupport" BO_ 494 1;
BA_ "GenMsgCycleTimeFast" BO_ 494 50;
BA_ "VFrameFormat" BO_ 494 14;
BA_ "OriginFrame" BO_ 497 "fuel,ev";
BA_ "GenMsgSendType" BO_ 497 2;
BA_ "GenMsgNrOfRepetition" BO_ 497 5;
BA_ "GenMsgILSupport" BO_ 497 1;
BA_ "GenMsgCycleTimeFast" BO_ 497 20;
BA_ "VFrameFormat" BO_ 497 14;
BA_ "OriginFrame" BO_ 498 "fuel,ev";
BA_ "GenMsgSendType" BO_ 498 2;
BA_ "GenMsgNrOfRepetition" BO_ 498 5;
BA_ "GenMsgILSupport" BO_ 498 1;
BA_ "GenMsgCycleTimeFast" BO_ 498 20;
BA_ "VFrameFormat" BO_ 498 14;
BA_ "OriginFrame" BO_ 505 "fuel,ev";
BA_ "GenMsgSendType" BO_ 505 2;
BA_ "GenMsgNrOfRepetition" BO_ 505 5;
BA_ "GenMsgILSupport" BO_ 505 1;
BA_ "GenMsgCycleTimeFast" BO_ 505 50;
BA_ "VFrameFormat" BO_ 505 14;
BA_ "OriginFrame" BO_ 506 "fuel,ev";
BA_ "GenMsgSendType" BO_ 506 2;
BA_ "GenMsgNrOfRepetition" BO_ 506 5;
BA_ "GenMsgILSupport" BO_ 506 1;
BA_ "GenMsgCycleTimeFast" BO_ 506 20;
BA_ "VFrameFormat" BO_ 506 14;
BA_ "OriginFrame" BO_ 507 "fuel,ev";
BA_ "GenMsgSendType" BO_ 507 2;
BA_ "GenMsgNrOfRepetition" BO_ 507 5;
BA_ "GenMsgILSupport" BO_ 507 1;
BA_ "GenMsgCycleTimeFast" BO_ 507 50;
BA_ "VFrameFormat" BO_ 507 14;
BA_ "OriginFrame" BO_ 509 "fuel,ev";
BA_ "GenMsgSendType" BO_ 509 2;
BA_ "GenMsgNrOfRepetition" BO_ 509 5;
BA_ "GenMsgILSupport" BO_ 509 1;
BA_ "GenMsgCycleTimeFast" BO_ 509 50;
BA_ "VFrameFormat" BO_ 509 14;
BA_ "OriginFrame" BO_ 545 "fuel,ev";
BA_ "GenMsgILSupport" BO_ 545 1;
BA_ "GenMsgCycleTime" BO_ 545 20;
BA_ "VFrameFormat" BO_ 545 14;
BA_ "OriginFrame" BO_ 546 "fuel,ev";
BA_ "GenMsgILSupport" BO_ 546 1;
BA_ "GenMsgCycleTime" BO_ 546 50;
BA_ "VFrameFormat" BO_ 546 14;
BA_ "OriginFrame" BO_ 548 "fuel,ev";
BA_ "GenMsgILSupport" BO_ 548 1;
BA_ "GenMsgCycleTime" BO_ 548 50;
BA_ "VFrameFormat" BO_ 548 14;
BA_ "SC_Message" BO_ 551 1;
BA_ "SCP_FreshnessValueTxLength" BO_ 551 16;
BA_ "SCP_FreshnessValueLength" BO_ 551 64;
BA_ "SCP_DataId" BO_ 551 551;
BA_ "SCP_AuthInfoTxLength" BO_ 551 48;
BA_ "OriginFrame" BO_ 551 "fuel,ev";
BA_ "GenMsgILSupport" BO_ 551 1;
BA_ "GenMsgCycleTime" BO_ 551 50;
BA_ "VFrameFormat" BO_ 551 14;
BA_ "OriginFrame" BO_ 561 "fuel,ev";
BA_ "GenMsgILSupport" BO_ 561 1;
BA_ "GenMsgCycleTime" BO_ 561 20;
BA_ "VFrameFormat" BO_ 561 14;
BA_ "SC_Message" BO_ 566 1;
BA_ "SCP_FreshnessValueTxLength" BO_ 566 16;
BA_ "SCP_FreshnessValueLength" BO_ 566 64;
BA_ "SCP_DataId" BO_ 566 566;
BA_ "SCP_AuthInfoTxLength" BO_ 566 48;
BA_ "OriginFrame" BO_ 566 "fuel,ev";
BA_ "GenMsgILSupport" BO_ 566 1;
BA_ "GenMsgCycleTime" BO_ 566 50;
BA_ "VFrameFormat" BO_ 566 14;
BA_ "OriginFrame" BO_ 568 "fuel,ev";
BA_ "GenMsgILSupport" BO_ 568 1;
BA_ "GenMsgCycleTime" BO_ 568 50;
BA_ "VFrameFormat" BO_ 568 14;
BA_ "SC_Message" BO_ 573 1;
BA_ "SCP_FreshnessValueTxLength" BO_ 573 16;
BA_ "SCP_FreshnessValueLength" BO_ 573 64;
BA_ "SCP_DataId" BO_ 573 573;
BA_ "SCP_AuthInfoTxLength" BO_ 573 48;
BA_ "OriginFrame" BO_ 573 "fuel,ev";
BA_ "GenMsgILSupport" BO_ 573 1;
BA_ "GenMsgCycleTime" BO_ 573 50;
BA_ "VFrameFormat" BO_ 573 14;
BA_ "OriginFrame" BO_ 579 "fuel,ev";
BA_ "GenMsgILSupport" BO_ 579 1;
BA_ "GenMsgCycleTime" BO_ 579 50;
BA_ "VFrameFormat" BO_ 579 14;
BA_ "OriginFrame" BO_ 580 "fuel,ev";
BA_ "GenMsgILSupport" BO_ 580 1;
BA_ "GenMsgCycleTime" BO_ 580 50;
BA_ "VFrameFormat" BO_ 580 14;
BA_ "OriginFrame" BO_ 581 "fuel,ev";
BA_ "GenMsgILSupport" BO_ 581 1;
BA_ "GenMsgCycleTime" BO_ 581 20;
BA_ "VFrameFormat" BO_ 581 14;
BA_ "OriginFrame" BO_ 582 "fuel,ev";
BA_ "GenMsgILSupport" BO_ 582 1;
BA_ "GenMsgCycleTime" BO_ 582 20;
BA_ "VFrameFormat" BO_ 582 14;
BA_ "OriginFrame" BO_ 584 "fuel,ev";
BA_ "GenMsgILSupport" BO_ 584 1;
BA_ "GenMsgCycleTime" BO_ 584 50;
BA_ "VFrameFormat" BO_ 584 14;
BA_ "OriginFrame" BO_ 589 "fuel,ev";
BA_ "GenMsgILSupport" BO_ 589 1;
BA_ "GenMsgCycleTime" BO_ 589 50;
BA_ "VFrameFormat" BO_ 589 14;
BA_ "OriginFrame" BO_ 593 "fuel,ev";
BA_ "GenMsgILSupport" BO_ 593 1;
BA_ "GenMsgCycleTime" BO_ 593 20;
BA_ "VFrameFormat" BO_ 593 14;
BA_ "OriginFrame" BO_ 604 "fuel,ev";
BA_ "GenMsgILSupport" BO_ 604 1;
BA_ "GenMsgCycleTime" BO_ 604 50;
BA_ "VFrameFormat" BO_ 604 14;
BA_ "OriginFrame" BO_ 623 "fuel,ev";
BA_ "GenMsgILSupport" BO_ 623 1;
BA_ "GenMsgCycleTime" BO_ 623 50;
BA_ "VFrameFormat" BO_ 623 14;
BA_ "OriginFrame" BO_ 625 "fuel,ev";
BA_ "GenMsgILSupport" BO_ 625 1;
BA_ "GenMsgCycleTime" BO_ 625 20;
BA_ "VFrameFormat" BO_ 625 14;
BA_ "OriginFrame" BO_ 627 "fuel,ev";
BA_ "GenMsgILSupport" BO_ 627 1;
BA_ "GenMsgCycleTime" BO_ 627 50;
BA_ "VFrameFormat" BO_ 627 14;
BA_ "OriginFrame" BO_ 628 "fuel,ev";
BA_ "GenMsgILSupport" BO_ 628 1;
BA_ "GenMsgCycleTime" BO_ 628 50;
BA_ "VFrameFormat" BO_ 628 14;
BA_ "OriginFrame" BO_ 636 "fuel,ev";
BA_ "GenMsgILSupport" BO_ 636 1;
BA_ "GenMsgCycleTime" BO_ 636 50;
BA_ "VFrameFormat" BO_ 636 14;
BA_ "SC_Message" BO_ 639 1;
BA_ "SCP_FreshnessValueTxLength" BO_ 639 16;
BA_ "SCP_FreshnessValueLength" BO_ 639 64;
BA_ "SCP_DataId" BO_ 639 639;
BA_ "SCP_AuthInfoTxLength" BO_ 639 48;
BA_ "OriginFrame" BO_ 639 "fuel,ev";
BA_ "GenMsgILSupport" BO_ 639 1;
BA_ "GenMsgCycleTime" BO_ 639 50;
BA_ "VFrameFormat" BO_ 639 14;
BA_ "OriginFrame" BO_ 647 "fuel,ev";
BA_ "GenMsgILSupport" BO_ 647 1;
BA_ "GenMsgCycleTime" BO_ 647 100;
BA_ "VFrameFormat" BO_ 647 14;
BA_ "OriginFrame" BO_ 649 "fuel,ev";
BA_ "GenMsgILSupport" BO_ 649 1;
BA_ "GenMsgCycleTime" BO_ 649 100;
BA_ "VFrameFormat" BO_ 649 14;
BA_ "OriginFrame" BO_ 653 "fuel,ev";
BA_ "GenMsgILSupport" BO_ 653 1;
BA_ "GenMsgCycleTime" BO_ 653 100;
BA_ "VFrameFormat" BO_ 653 14;
BA_ "OriginFrame" BO_ 656 "fuel,ev";
BA_ "GenMsgILSupport" BO_ 656 1;
BA_ "GenMsgCycleTime" BO_ 656 100;
BA_ "VFrameFormat" BO_ 656 14;
BA_ "OriginFrame" BO_ 659 "fuel,ev";
BA_ "GenMsgILSupport" BO_ 659 1;
BA_ "GenMsgCycleTime" BO_ 659 100;
BA_ "VFrameFormat" BO_ 659 14;
BA_ "OriginFrame" BO_ 661 "fuel,ev";
BA_ "GenMsgILSupport" BO_ 661 1;
BA_ "GenMsgCycleTime" BO_ 661 50;
BA_ "VFrameFormat" BO_ 661 14;
BA_ "OriginFrame" BO_ 664 "fuel,ev";
BA_ "GenMsgILSupport" BO_ 664 1;
BA_ "GenMsgCycleTime" BO_ 664 100;
BA_ "VFrameFormat" BO_ 664 14;
BA_ "OriginFrame" BO_ 665 "fuel,ev";
BA_ "GenMsgILSupport" BO_ 665 1;
BA_ "GenMsgCycleTime" BO_ 665 100;
BA_ "VFrameFormat" BO_ 665 14;
BA_ "OriginFrame" BO_ 667 "fuel,ev";
BA_ "GenMsgILSupport" BO_ 667 1;
BA_ "GenMsgCycleTime" BO_ 667 100;
BA_ "VFrameFormat" BO_ 667 14;
BA_ "OriginFrame" BO_ 669 "fuel,ev";
BA_ "GenMsgILSupport" BO_ 669 1;
BA_ "GenMsgCycleTime" BO_ 669 100;
BA_ "VFrameFormat" BO_ 669 14;
BA_ "OriginFrame" BO_ 671 "fuel,ev";
BA_ "GenMsgILSupport" BO_ 671 1;
BA_ "GenMsgCycleTime" BO_ 671 100;
BA_ "VFrameFormat" BO_ 671 14;
BA_ "OriginFrame" BO_ 675 "fuel,ev";
BA_ "GenMsgILSupport" BO_ 675 1;
BA_ "GenMsgCycleTime" BO_ 675 100;
BA_ "VFrameFormat" BO_ 675 14;
BA_ "OriginFrame" BO_ 680 "fuel,ev";
BA_ "GenMsgILSupport" BO_ 680 1;
BA_ "GenMsgCycleTime" BO_ 680 100;
BA_ "VFrameFormat" BO_ 680 14;
BA_ "SC_Message" BO_ 683 1;
BA_ "SCP_FreshnessValueTxLength" BO_ 683 16;
BA_ "SCP_FreshnessValueLength" BO_ 683 64;
BA_ "SCP_DataId" BO_ 683 683;
BA_ "SCP_AuthInfoTxLength" BO_ 683 48;
BA_ "OriginFrame" BO_ 683 "fuel,ev";
BA_ "GenMsgILSupport" BO_ 683 1;
BA_ "GenMsgCycleTime" BO_ 683 100;
BA_ "VFrameFormat" BO_ 683 14;
BA_ "OriginFrame" BO_ 692 "fuel,ev";
BA_ "GenMsgILSupport" BO_ 692 1;
BA_ "GenMsgCycleTime" BO_ 692 100;
BA_ "VFrameFormat" BO_ 692 14;
BA_ "OriginFrame" BO_ 694 "fuel,ev";
BA_ "GenMsgILSupport" BO_ 694 1;
BA_ "GenMsgCycleTime" BO_ 694 100;
BA_ "VFrameFormat" BO_ 694 14;
BA_ "OriginFrame" BO_ 696 "fuel,ev";
BA_ "GenMsgILSupport" BO_ 696 1;
BA_ "GenMsgCycleTime" BO_ 696 100;
BA_ "VFrameFormat" BO_ 696 14;
BA_ "OriginFrame" BO_ 697 "fuel,ev";
BA_ "GenMsgILSupport" BO_ 697 1;
BA_ "GenMsgCycleTime" BO_ 697 100;
BA_ "VFrameFormat" BO_ 697 14;
BA_ "OriginFrame" BO_ 698 "fuel,ev";
BA_ "GenMsgILSupport" BO_ 698 1;
BA_ "GenMsgCycleTime" BO_ 698 100;
BA_ "VFrameFormat" BO_ 698 14;
BA_ "OriginFrame" BO_ 699 "fuel,ev";
BA_ "GenMsgILSupport" BO_ 699 1;
BA_ "GenMsgCycleTime" BO_ 699 100;
BA_ "VFrameFormat" BO_ 699 14;
BA_ "OriginFrame" BO_ 705 "fuel,ev";
BA_ "GenMsgILSupport" BO_ 705 1;
BA_ "GenMsgCycleTime" BO_ 705 100;
BA_ "VFrameFormat" BO_ 705 14;
BA_ "SC_Message" BO_ 707 1;
BA_ "SCP_FreshnessValueTxLength" BO_ 707 16;
BA_ "SCP_FreshnessValueLength" BO_ 707 64;
BA_ "SCP_DataId" BO_ 707 707;
BA_ "SCP_AuthInfoTxLength" BO_ 707 48;
BA_ "OriginFrame" BO_ 707 "fuel,ev";
BA_ "GenMsgILSupport" BO_ 707 1;
BA_ "GenMsgCycleTime" BO_ 707 100;
BA_ "VFrameFormat" BO_ 707 14;
BA_ "OriginFrame" BO_ 714 "fuel,ev";
BA_ "GenMsgILSupport" BO_ 714 1;
BA_ "GenMsgCycleTime" BO_ 714 100;
BA_ "VFrameFormat" BO_ 714 14;
BA_ "OriginFrame" BO_ 716 "fuel,ev";
BA_ "GenMsgILSupport" BO_ 716 1;
BA_ "GenMsgCycleTime" BO_ 716 100;
BA_ "VFrameFormat" BO_ 716 14;
BA_ "OriginFrame" BO_ 717 "fuel,ev";
BA_ "GenMsgILSupport" BO_ 717 1;
BA_ "GenMsgCycleTime" BO_ 717 100;
BA_ "VFrameFormat" BO_ 717 14;
BA_ "OriginFrame" BO_ 718 "fuel,ev";
BA_ "GenMsgILSupport" BO_ 718 1;
BA_ "GenMsgCycleTime" BO_ 718 100;
BA_ "VFrameFormat" BO_ 718 14;
BA_ "OriginFrame" BO_ 719 "fuel,ev";
BA_ "GenMsgILSupport" BO_ 719 1;
BA_ "GenMsgCycleTime" BO_ 719 100;
BA_ "VFrameFormat" BO_ 719 14;
BA_ "OriginFrame" BO_ 720 "fuel,ev";
BA_ "GenMsgILSupport" BO_ 720 1;
BA_ "GenMsgCycleTime" BO_ 720 100;
BA_ "VFrameFormat" BO_ 720 14;
BA_ "OriginFrame" BO_ 721 "fuel,ev";
BA_ "GenMsgILSupport" BO_ 721 1;
BA_ "GenMsgCycleTime" BO_ 721 100;
BA_ "VFrameFormat" BO_ 721 14;
BA_ "OriginFrame" BO_ 722 "fuel,ev";
BA_ "GenMsgSendType" BO_ 722 2;
BA_ "GenMsgNrOfRepetition" BO_ 722 5;
BA_ "GenMsgILSupport" BO_ 722 1;
BA_ "GenMsgCycleTimeFast" BO_ 722 20;
BA_ "VFrameFormat" BO_ 722 14;
BA_ "OriginFrame" BO_ 723 "fuel,ev";
BA_ "GenMsgILSupport" BO_ 723 1;
BA_ "GenMsgCycleTime" BO_ 723 100;
BA_ "VFrameFormat" BO_ 723 14;
BA_ "OriginFrame" BO_ 728 "fuel,ev";
BA_ "GenMsgSendType" BO_ 728 2;
BA_ "GenMsgNrOfRepetition" BO_ 728 5;
BA_ "GenMsgILSupport" BO_ 728 1;
BA_ "GenMsgCycleTimeFast" BO_ 728 20;
BA_ "VFrameFormat" BO_ 728 14;
BA_ "OriginFrame" BO_ 730 "fuel,ev";
BA_ "GenMsgSendType" BO_ 730 2;
BA_ "GenMsgNrOfRepetition" BO_ 730 5;
BA_ "GenMsgILSupport" BO_ 730 1;
BA_ "GenMsgCycleTimeFast" BO_ 730 20;
BA_ "VFrameFormat" BO_ 730 14;
BA_ "OriginFrame" BO_ 733 "fuel,ev";
BA_ "GenMsgSendType" BO_ 733 2;
BA_ "GenMsgNrOfRepetition" BO_ 733 5;
BA_ "GenMsgILSupport" BO_ 733 1;
BA_ "GenMsgCycleTimeFast" BO_ 733 20;
BA_ "VFrameFormat" BO_ 733 14;
BA_ "OriginFrame" BO_ 734 "fuel,ev";
BA_ "GenMsgSendType" BO_ 734 2;
BA_ "GenMsgNrOfRepetition" BO_ 734 5;
BA_ "GenMsgILSupport" BO_ 734 1;
BA_ "GenMsgCycleTimeFast" BO_ 734 20;
BA_ "VFrameFormat" BO_ 734 14;
BA_ "OriginFrame" BO_ 748 "fuel,ev";
BA_ "GenMsgILSupport" BO_ 748 1;
BA_ "GenMsgCycleTime" BO_ 748 100;
BA_ "VFrameFormat" BO_ 748 14;
BA_ "OriginFrame" BO_ 752 "fuel,ev";
BA_ "GenMsgILSupport" BO_ 752 1;
BA_ "GenMsgCycleTime" BO_ 752 100;
BA_ "VFrameFormat" BO_ 752 14;
BA_ "OriginFrame" BO_ 759 "fuel,ev";
BA_ "GenMsgILSupport" BO_ 759 1;
BA_ "GenMsgCycleTime" BO_ 759 100;
BA_ "VFrameFormat" BO_ 759 14;
BA_ "OriginFrame" BO_ 760 "fuel,ev";
BA_ "GenMsgILSupport" BO_ 760 1;
BA_ "GenMsgCycleTime" BO_ 760 100;
BA_ "VFrameFormat" BO_ 760 14;
BA_ "OriginFrame" BO_ 762 "fuel,ev";
BA_ "GenMsgILSupport" BO_ 762 1;
BA_ "GenMsgCycleTime" BO_ 762 100;
BA_ "VFrameFormat" BO_ 762 14;
BA_ "OriginFrame" BO_ 765 "fuel,ev";
BA_ "GenMsgILSupport" BO_ 765 1;
BA_ "GenMsgCycleTime" BO_ 765 100;
BA_ "VFrameFormat" BO_ 765 14;
BA_ "OriginFrame" BO_ 770 "fuel,ev";
BA_ "GenMsgNrOfRepetition" BO_ 770 5;
BA_ "GenMsgILSupport" BO_ 770 1;
BA_ "GenMsgCycleTimeFast" BO_ 770 20;
BA_ "GenMsgCycleTime" BO_ 770 200;
BA_ "VFrameFormat" BO_ 770 14;
BA_ "OriginFrame" BO_ 771 "fuel,ev";
BA_ "GenMsgNrOfRepetition" BO_ 771 5;
BA_ "GenMsgILSupport" BO_ 771 1;
BA_ "GenMsgCycleTimeFast" BO_ 771 20;
BA_ "GenMsgCycleTime" BO_ 771 200;
BA_ "VFrameFormat" BO_ 771 14;
BA_ "OriginFrame" BO_ 772 "fuel,ev";
BA_ "GenMsgILSupport" BO_ 772 1;
BA_ "GenMsgCycleTime" BO_ 772 200;
BA_ "VFrameFormat" BO_ 772 14;
BA_ "OriginFrame" BO_ 773 "fuel,ev";
BA_ "GenMsgILSupport" BO_ 773 1;
BA_ "GenMsgCycleTime" BO_ 773 100;
BA_ "VFrameFormat" BO_ 773 14;
BA_ "OriginFrame" BO_ 776 "fuel,ev";
BA_ "GenMsgILSupport" BO_ 776 1;
BA_ "GenMsgCycleTime" BO_ 776 200;
BA_ "VFrameFormat" BO_ 776 14;
BA_ "OriginFrame" BO_ 778 "fuel,ev";
BA_ "GenMsgILSupport" BO_ 778 1;
BA_ "GenMsgCycleTime" BO_ 778 200;
BA_ "VFrameFormat" BO_ 778 14;
BA_ "OriginFrame" BO_ 780 "fuel,ev";
BA_ "GenMsgILSupport" BO_ 780 1;
BA_ "GenMsgCycleTime" BO_ 780 200;
BA_ "VFrameFormat" BO_ 780 14;
BA_ "OriginFrame" BO_ 781 "fuel,ev";
BA_ "GenMsgILSupport" BO_ 781 1;
BA_ "GenMsgCycleTime" BO_ 781 200;
BA_ "VFrameFormat" BO_ 781 14;
BA_ "OriginFrame" BO_ 783 "fuel,ev";
BA_ "GenMsgILSupport" BO_ 783 1;
BA_ "GenMsgCycleTime" BO_ 783 100;
BA_ "VFrameFormat" BO_ 783 14;
BA_ "OriginFrame" BO_ 785 "fuel,ev";
BA_ "GenMsgILSupport" BO_ 785 1;
BA_ "GenMsgCycleTime" BO_ 785 200;
BA_ "VFrameFormat" BO_ 785 14;
BA_ "SC_Message" BO_ 793 1;
BA_ "SCP_FreshnessValueTxLength" BO_ 793 16;
BA_ "SCP_FreshnessValueLength" BO_ 793 64;
BA_ "SCP_DataId" BO_ 793 793;
BA_ "SCP_AuthInfoTxLength" BO_ 793 48;
BA_ "OriginFrame" BO_ 793 "fuel,ev";
BA_ "GenMsgILSupport" BO_ 793 1;
BA_ "GenMsgCycleTime" BO_ 793 50;
BA_ "VFrameFormat" BO_ 793 14;
BA_ "OriginFrame" BO_ 796 "fuel,ev";
BA_ "GenMsgILSupport" BO_ 796 1;
BA_ "GenMsgCycleTime" BO_ 796 100;
BA_ "VFrameFormat" BO_ 796 14;
BA_ "OriginFrame" BO_ 805 "fuel,ev";
BA_ "GenMsgILSupport" BO_ 805 1;
BA_ "GenMsgCycleTime" BO_ 805 200;
BA_ "VFrameFormat" BO_ 805 14;
BA_ "OriginFrame" BO_ 816 "fuel,ev";
BA_ "GenMsgILSupport" BO_ 816 1;
BA_ "GenMsgCycleTime" BO_ 816 200;
BA_ "VFrameFormat" BO_ 816 14;
BA_ "OriginFrame" BO_ 817 "fuel,ev";
BA_ "GenMsgSendType" BO_ 817 2;
BA_ "GenMsgNrOfRepetition" BO_ 817 5;
BA_ "GenMsgILSupport" BO_ 817 1;
BA_ "GenMsgCycleTimeFast" BO_ 817 60;
BA_ "VFrameFormat" BO_ 817 14;
BA_ "OriginFrame" BO_ 818 "fuel,ev";
BA_ "GenMsgILSupport" BO_ 818 1;
BA_ "GenMsgCycleTime" BO_ 818 200;
BA_ "VFrameFormat" BO_ 818 14;
BA_ "OriginFrame" BO_ 819 "fuel,ev";
BA_ "GenMsgILSupport" BO_ 819 1;
BA_ "GenMsgCycleTime" BO_ 819 200;
BA_ "VFrameFormat" BO_ 819 14;
BA_ "OriginFrame" BO_ 825 "fuel,ev";
BA_ "GenMsgSendType" BO_ 825 2;
BA_ "GenMsgNrOfRepetition" BO_ 825 5;
BA_ "GenMsgILSupport" BO_ 825 1;
BA_ "GenMsgCycleTimeFast" BO_ 825 50;
BA_ "VFrameFormat" BO_ 825 14;
BA_ "OriginFrame" BO_ 827 "fuel,ev";
BA_ "GenMsgSendType" BO_ 827 2;
BA_ "GenMsgNrOfRepetition" BO_ 827 5;
BA_ "GenMsgILSupport" BO_ 827 1;
BA_ "GenMsgCycleTimeFast" BO_ 827 50;
BA_ "VFrameFormat" BO_ 827 14;
BA_ "SC_Message" BO_ 833 1;
BA_ "SCP_FreshnessValueTxLength" BO_ 833 16;
BA_ "SCP_FreshnessValueLength" BO_ 833 64;
BA_ "SCP_DataId" BO_ 833 833;
BA_ "SCP_AuthInfoTxLength" BO_ 833 48;
BA_ "OriginFrame" BO_ 833 "fuel,ev";
BA_ "GenMsgILSupport" BO_ 833 1;
BA_ "GenMsgCycleTime" BO_ 833 500;
BA_ "VFrameFormat" BO_ 833 14;
BA_ "OriginFrame" BO_ 836 "fuel,ev";
BA_ "GenMsgILSupport" BO_ 836 1;
BA_ "GenMsgCycleTime" BO_ 836 500;
BA_ "VFrameFormat" BO_ 836 14;
BA_ "SC_Message" BO_ 837 1;
BA_ "SCP_FreshnessValueTxLength" BO_ 837 16;
BA_ "SCP_FreshnessValueLength" BO_ 837 64;
BA_ "SCP_DataId" BO_ 837 837;
BA_ "SCP_AuthInfoTxLength" BO_ 837 48;
BA_ "OriginFrame" BO_ 837 "fuel,ev";
BA_ "GenMsgILSupport" BO_ 837 1;
BA_ "GenMsgCycleTime" BO_ 837 50;
BA_ "VFrameFormat" BO_ 837 14;
BA_ "OriginFrame" BO_ 840 "fuel,ev";
BA_ "GenMsgILSupport" BO_ 840 1;
BA_ "GenMsgCycleTime" BO_ 840 500;
BA_ "VFrameFormat" BO_ 840 14;
BA_ "OriginFrame" BO_ 842 "fuel,ev";
BA_ "GenMsgILSupport" BO_ 842 1;
BA_ "GenMsgCycleTime" BO_ 842 500;
BA_ "VFrameFormat" BO_ 842 14;
BA_ "OriginFrame" BO_ 845 "fuel,ev";
BA_ "GenMsgILSupport" BO_ 845 1;
BA_ "GenMsgCycleTime" BO_ 845 500;
BA_ "VFrameFormat" BO_ 845 14;
BA_ "SC_Message" BO_ 849 1;
BA_ "SCP_FreshnessValueTxLength" BO_ 849 16;
BA_ "SCP_FreshnessValueLength" BO_ 849 64;
BA_ "SCP_DataId" BO_ 849 849;
BA_ "SCP_AuthInfoTxLength" BO_ 849 48;
BA_ "OriginFrame" BO_ 849 "fuel,ev";
BA_ "GenMsgNrOfRepetition" BO_ 849 5;
BA_ "GenMsgILSupport" BO_ 849 1;
BA_ "GenMsgCycleTimeFast" BO_ 849 20;
BA_ "GenMsgCycleTime" BO_ 849 500;
BA_ "VFrameFormat" BO_ 849 14;
BA_ "OriginFrame" BO_ 862 "fuel,ev";
BA_ "GenMsgILSupport" BO_ 862 1;
BA_ "GenMsgCycleTime" BO_ 862 500;
BA_ "VFrameFormat" BO_ 862 14;
BA_ "OriginFrame" BO_ 871 "fuel,ev";
BA_ "GenMsgSendType" BO_ 871 2;
BA_ "GenMsgNrOfRepetition" BO_ 871 5;
BA_ "GenMsgILSupport" BO_ 871 1;
BA_ "GenMsgCycleTimeFast" BO_ 871 60;
BA_ "VFrameFormat" BO_ 871 14;
BA_ "OriginFrame" BO_ 873 "fuel,ev";
BA_ "GenMsgSendType" BO_ 873 2;
BA_ "GenMsgNrOfRepetition" BO_ 873 5;
BA_ "GenMsgILSupport" BO_ 873 1;
BA_ "GenMsgCycleTimeFast" BO_ 873 60;
BA_ "VFrameFormat" BO_ 873 14;
BA_ "OriginFrame" BO_ 875 "fuel,ev";
BA_ "GenMsgSendType" BO_ 875 2;
BA_ "GenMsgNrOfRepetition" BO_ 875 5;
BA_ "GenMsgILSupport" BO_ 875 1;
BA_ "GenMsgCycleTimeFast" BO_ 875 50;
BA_ "VFrameFormat" BO_ 875 14;
BA_ "OriginFrame" BO_ 877 "fuel,ev";
BA_ "GenMsgSendType" BO_ 877 2;
BA_ "GenMsgNrOfRepetition" BO_ 877 5;
BA_ "GenMsgILSupport" BO_ 877 1;
BA_ "GenMsgCycleTimeFast" BO_ 877 50;
BA_ "VFrameFormat" BO_ 877 14;
BA_ "OriginFrame" BO_ 880 "fuel,ev";
BA_ "GenMsgILSupport" BO_ 880 1;
BA_ "GenMsgCycleTime" BO_ 880 1000;
BA_ "VFrameFormat" BO_ 880 14;
BA_ "OriginFrame" BO_ 881 "fuel,ev";
BA_ "GenMsgILSupport" BO_ 881 1;
BA_ "GenMsgCycleTime" BO_ 881 100;
BA_ "VFrameFormat" BO_ 881 14;
BA_ "OriginFrame" BO_ 901 "fuel,ev";
BA_ "GenMsgILSupport" BO_ 901 1;
BA_ "GenMsgCycleTime" BO_ 901 100;
BA_ "VFrameFormat" BO_ 901 14;
BA_ "SC_Message" BO_ 917 1;
BA_ "SCP_FreshnessValueTxLength" BO_ 917 16;
BA_ "SCP_FreshnessValueLength" BO_ 917 64;
BA_ "SCP_DataId" BO_ 917 917;
BA_ "SCP_AuthInfoTxLength" BO_ 917 48;
BA_ "OriginFrame" BO_ 917 "fuel,ev";
BA_ "GenMsgILSupport" BO_ 917 1;
BA_ "GenMsgCycleTime" BO_ 917 500;
BA_ "VFrameFormat" BO_ 917 14;
BA_ "OriginFrame" BO_ 943 "fuel,ev";
BA_ "GenMsgILSupport" BO_ 943 1;
BA_ "GenMsgCycleTime" BO_ 943 1000;
BA_ "VFrameFormat" BO_ 943 14;
BA_ "OriginFrame" BO_ 949 "fuel,ev";
BA_ "GenMsgILSupport" BO_ 949 1;
BA_ "GenMsgCycleTime" BO_ 949 1000;
BA_ "VFrameFormat" BO_ 949 14;
BA_ "OriginFrame" BO_ 951 "fuel,ev";
BA_ "GenMsgILSupport" BO_ 951 1;
BA_ "GenMsgCycleTime" BO_ 951 1000;
BA_ "VFrameFormat" BO_ 951 14;
BA_ "OriginFrame" BO_ 962 "fuel,ev";
BA_ "GenMsgILSupport" BO_ 962 1;
BA_ "GenMsgCycleTime" BO_ 962 1000;
BA_ "VFrameFormat" BO_ 962 14;
BA_ "OriginFrame" BO_ 993 "fuel,ev";
BA_ "GenMsgSendType" BO_ 993 2;
BA_ "GenMsgNrOfRepetition" BO_ 993 5;
BA_ "GenMsgILSupport" BO_ 993 1;
BA_ "GenMsgCycleTimeFast" BO_ 993 20;
BA_ "VFrameFormat" BO_ 993 14;
BA_ "SC_Message" BO_ 995 1;
BA_ "SCP_FreshnessValueTxLength" BO_ 995 16;
BA_ "SCP_FreshnessValueLength" BO_ 995 64;
BA_ "SCP_DataId" BO_ 995 995;
BA_ "SCP_AuthInfoTxLength" BO_ 995 48;
BA_ "OriginFrame" BO_ 995 "fuel,ev";
BA_ "GenMsgSendType" BO_ 995 2;
BA_ "GenMsgNrOfRepetition" BO_ 995 5;
BA_ "GenMsgILSupport" BO_ 995 1;
BA_ "GenMsgCycleTimeFast" BO_ 995 20;
BA_ "VFrameFormat" BO_ 995 14;
BA_ "OriginFrame" BO_ 997 "fuel,ev";
BA_ "GenMsgSendType" BO_ 997 2;
BA_ "GenMsgNrOfRepetition" BO_ 997 5;
BA_ "GenMsgILSupport" BO_ 997 1;
BA_ "GenMsgCycleTimeFast" BO_ 997 20;
BA_ "VFrameFormat" BO_ 997 14;
BA_ "SC_Message" BO_ 1001 1;
BA_ "SCP_FreshnessValueTxLength" BO_ 1001 16;
BA_ "SCP_FreshnessValueLength" BO_ 1001 64;
BA_ "SCP_DataId" BO_ 1001 1001;
BA_ "SCP_AuthInfoTxLength" BO_ 1001 48;
BA_ "OriginFrame" BO_ 1001 "fuel,ev";
BA_ "GenMsgILSupport" BO_ 1001 1;
BA_ "GenMsgCycleTime" BO_ 1001 1000;
BA_ "VFrameFormat" BO_ 1001 14;
BA_ "OriginFrame" BO_ 1045 "fuel,ev";
BA_ "GenMsgILSupport" BO_ 1045 1;
BA_ "GenMsgCycleTime" BO_ 1045 5000;
BA_ "VFrameFormat" BO_ 1045 14;
BA_ "OriginFrame" BO_ 1888 "fuel,ev";
BA_ "GenMsgSendType" BO_ 1888 2;
BA_ "DiagState" BO_ 1888 1;
BA_ "VFrameFormat" BO_ 1888 14;
BA_ "OriginFrame" BO_ 1889 "fuel,ev";
BA_ "GenMsgSendType" BO_ 1889 2;
BA_ "DiagRequest" BO_ 1889 1;
BA_ "VFrameFormat" BO_ 1889 14;
BA_ "OriginFrame" BO_ 1918 "fuel,ev";
BA_ "GenMsgSendType" BO_ 1918 2;
BA_ "DiagRequest" BO_ 1918 1;
BA_ "VFrameFormat" BO_ 1918 14;
BA_ "OriginFrame" BO_ 1843 "fuel,ev";
BA_ "GenMsgSendType" BO_ 1843 2;
BA_ "DiagRequest" BO_ 1843 1;
BA_ "VFrameFormat" BO_ 1843 14;
BA_ "OriginFrame" BO_ 1907 "fuel,ev";
BA_ "GenMsgSendType" BO_ 1907 2;
BA_ "DiagRequest" BO_ 1907 1;
BA_ "VFrameFormat" BO_ 1907 14;
BA_ "OriginFrame" BO_ 1953 "fuel,ev";
BA_ "GenMsgSendType" BO_ 1953 2;
BA_ "DiagResponse" BO_ 1953 1;
BA_ "VFrameFormat" BO_ 1953 14;
BA_ "OriginFrame" BO_ 1982 "fuel,ev";
BA_ "GenMsgSendType" BO_ 1982 2;
BA_ "DiagResponse" BO_ 1982 1;
BA_ "VFrameFormat" BO_ 1982 14;
BA_ "OriginFrame" BO_ 1844 "fuel,ev";
BA_ "GenMsgSendType" BO_ 1844 2;
BA_ "DiagResponse" BO_ 1844 1;
BA_ "VFrameFormat" BO_ 1844 14;
BA_ "OriginFrame" BO_ 1971 "fuel,ev";
BA_ "GenMsgSendType" BO_ 1971 2;
BA_ "DiagResponse" BO_ 1971 1;
BA_ "VFrameFormat" BO_ 1971 14;
BA_ "VFrameFormat" BO_ 1290 0;
BA_ "OriginFrame" BO_ 1290 "fuel,ev";
BA_ "NmAsrMessage" BO_ 1290 1;
BA_ "GenMsgSendType" BO_ 1290 2;
BA_ "VFrameFormat" BO_ 1289 0;
BA_ "OriginFrame" BO_ 1289 "fuel,ev";
BA_ "NmAsrMessage" BO_ 1289 1;
BA_ "GenMsgSendType" BO_ 1289 2;
BA_ "VFrameFormat" BO_ 1334 0;
BA_ "OriginFrame" BO_ 1334 "fuel,ev";
BA_ "NmAsrMessage" BO_ 1334 1;
BA_ "GenMsgSendType" BO_ 1334 2;
BA_ "VFrameFormat" BO_ 1281 0;
BA_ "OriginFrame" BO_ 1281 "fuel,ev";
BA_ "NmAsrMessage" BO_ 1281 1;
BA_ "GenMsgSendType" BO_ 1281 2;
BA_ "OriginFrame" BO_ 1122 "fuel,ev";
BA_ "GenMsgSendType" BO_ 1122 2;
BA_ "GenMsgILSupport" BO_ 1122 1;
BA_ "VFrameFormat" BO_ 1122 14;
BA_ "SC_Message" BO_ 1121 1;
BA_ "SCP_FreshnessValueTxLength" BO_ 1121 40;
BA_ "SCP_FreshnessValueLength" BO_ 1121 40;
BA_ "SCP_DataId" BO_ 1121 1121;
BA_ "SCP_AuthInfoTxLength" BO_ 1121 88;
BA_ "OriginFrame" BO_ 1121 "fuel,ev";
BA_ "VFrameFormat" BO_ 1121 14;
BA_ "OriginFrame" BO_ 53 "ev";
BA_ "GenMsgSendType" BO_ 53 2;
BA_ "GenMsgNrOfRepetition" BO_ 53 5;
BA_ "GenMsgILSupport" BO_ 53 1;
BA_ "GenMsgCycleTimeFast" BO_ 53 20;
BA_ "VFrameFormat" BO_ 53 14;
BA_ "OriginFrame" BO_ 54 "ev";
BA_ "GenMsgSendType" BO_ 54 2;
BA_ "GenMsgNrOfRepetition" BO_ 54 5;
BA_ "GenMsgILSupport" BO_ 54 1;
BA_ "GenMsgCycleTimeFast" BO_ 54 20;
BA_ "VFrameFormat" BO_ 54 14;
BA_ "OriginFrame" BO_ 70 "ev";
BA_ "GenMsgSendType" BO_ 70 2;
BA_ "GenMsgNrOfRepetition" BO_ 70 5;
BA_ "GenMsgILSupport" BO_ 70 1;
BA_ "GenMsgCycleTimeFast" BO_ 70 20;
BA_ "VFrameFormat" BO_ 70 14;
BA_ "OriginFrame" BO_ 72 "ev";
BA_ "GenMsgSendType" BO_ 72 2;
BA_ "GenMsgNrOfRepetition" BO_ 72 5;
BA_ "GenMsgILSupport" BO_ 72 1;
BA_ "GenMsgCycleTimeFast" BO_ 72 20;
BA_ "VFrameFormat" BO_ 72 14;
BA_ "OriginFrame" BO_ 96 "ev";
BA_ "GenMsgILSupport" BO_ 96 1;
BA_ "GenMsgCycleTime" BO_ 96 10;
BA_ "VFrameFormat" BO_ 96 14;
BA_ "OriginFrame" BO_ 142 "ev";
BA_ "GenMsgILSupport" BO_ 142 1;
BA_ "GenMsgCycleTime" BO_ 142 10;
BA_ "VFrameFormat" BO_ 142 14;
BA_ "OriginFrame" BO_ 172 "ev";
BA_ "GenMsgILSupport" BO_ 172 1;
BA_ "GenMsgCycleTime" BO_ 172 10;
BA_ "VFrameFormat" BO_ 172 14;
BA_ "OriginFrame" BO_ 190 "ev";
BA_ "GenMsgILSupport" BO_ 190 1;
BA_ "GenMsgCycleTime" BO_ 190 10;
BA_ "VFrameFormat" BO_ 190 14;
BA_ "OriginFrame" BO_ 249 "ev";
BA_ "GenMsgILSupport" BO_ 249 1;
BA_ "GenMsgCycleTime" BO_ 249 10;
BA_ "VFrameFormat" BO_ 249 14;
BA_ "OriginFrame" BO_ 279 "ev";
BA_ "GenMsgILSupport" BO_ 279 1;
BA_ "GenMsgCycleTime" BO_ 279 20;
BA_ "VFrameFormat" BO_ 279 14;
BA_ "OriginFrame" BO_ 282 "ev";
BA_ "GenMsgILSupport" BO_ 282 1;
BA_ "GenMsgCycleTime" BO_ 282 20;
BA_ "VFrameFormat" BO_ 282 14;
BA_ "OriginFrame" BO_ 301 "ev";
BA_ "GenMsgILSupport" BO_ 301 1;
BA_ "GenMsgCycleTime" BO_ 301 20;
BA_ "VFrameFormat" BO_ 301 14;
BA_ "OriginFrame" BO_ 330 "ev";
BA_ "GenMsgILSupport" BO_ 330 1;
BA_ "GenMsgCycleTime" BO_ 330 20;
BA_ "VFrameFormat" BO_ 330 14;
BA_ "OriginFrame" BO_ 448 "ev";
BA_ "GenMsgILSupport" BO_ 448 1;
BA_ "GenMsgCycleTime" BO_ 448 50;
BA_ "VFrameFormat" BO_ 448 14;
BA_ "OriginFrame" BO_ 482 "ev";
BA_ "GenMsgSendType" BO_ 482 2;
BA_ "GenMsgNrOfRepetition" BO_ 482 5;
BA_ "GenMsgILSupport" BO_ 482 1;
BA_ "GenMsgCycleTimeFast" BO_ 482 20;
BA_ "VFrameFormat" BO_ 482 14;
BA_ "OriginFrame" BO_ 483 "ev";
BA_ "GenMsgSendType" BO_ 483 2;
BA_ "GenMsgNrOfRepetition" BO_ 483 5;
BA_ "GenMsgILSupport" BO_ 483 1;
BA_ "GenMsgCycleTimeFast" BO_ 483 20;
BA_ "VFrameFormat" BO_ 483 14;
BA_ "OriginFrame" BO_ 510 "ev";
BA_ "GenMsgSendType" BO_ 510 2;
BA_ "GenMsgNrOfRepetition" BO_ 510 5;
BA_ "GenMsgILSupport" BO_ 510 1;
BA_ "GenMsgCycleTimeFast" BO_ 510 20;
BA_ "VFrameFormat" BO_ 510 14;
BA_ "OriginFrame" BO_ 513 "ev";
BA_ "GenMsgILSupport" BO_ 513 1;
BA_ "GenMsgCycleTime" BO_ 513 50;
BA_ "VFrameFormat" BO_ 513 14;
BA_ "OriginFrame" BO_ 515 "ev";
BA_ "GenMsgILSupport" BO_ 515 1;
BA_ "GenMsgCycleTime" BO_ 515 50;
BA_ "VFrameFormat" BO_ 515 14;
BA_ "OriginFrame" BO_ 616 "ev";
BA_ "GenMsgILSupport" BO_ 616 1;
BA_ "GenMsgCycleTime" BO_ 616 50;
BA_ "VFrameFormat" BO_ 616 14;
BA_ "OriginFrame" BO_ 645 "ev";
BA_ "GenMsgILSupport" BO_ 645 1;
BA_ "GenMsgCycleTime" BO_ 645 100;
BA_ "VFrameFormat" BO_ 645 14;
BA_ "OriginFrame" BO_ 690 "ev";
BA_ "GenMsgILSupport" BO_ 690 1;
BA_ "GenMsgCycleTime" BO_ 690 100;
BA_ "VFrameFormat" BO_ 690 14;
BA_ "OriginFrame" BO_ 708 "ev";
BA_ "GenMsgILSupport" BO_ 708 1;
BA_ "GenMsgCycleTime" BO_ 708 100;
BA_ "VFrameFormat" BO_ 708 14;
BA_ "OriginFrame" BO_ 743 "ev";
BA_ "GenMsgILSupport" BO_ 743 1;
BA_ "GenMsgCycleTime" BO_ 743 50;
BA_ "VFrameFormat" BO_ 743 14;
BA_ "OriginFrame" BO_ 788 "ev";
BA_ "GenMsgILSupport" BO_ 788 1;
BA_ "GenMsgCycleTime" BO_ 788 200;
BA_ "VFrameFormat" BO_ 788 14;
BA_ "OriginFrame" BO_ 790 "ev";
BA_ "GenMsgILSupport" BO_ 790 1;
BA_ "GenMsgCycleTime" BO_ 790 200;
BA_ "VFrameFormat" BO_ 790 14;
BA_ "OriginFrame" BO_ 791 "ev";
BA_ "GenMsgILSupport" BO_ 791 1;
BA_ "GenMsgCycleTime" BO_ 791 200;
BA_ "VFrameFormat" BO_ 791 14;
BA_ "OriginFrame" BO_ 829 "ev";
BA_ "GenMsgSendType" BO_ 829 2;
BA_ "GenMsgNrOfRepetition" BO_ 829 5;
BA_ "GenMsgILSupport" BO_ 829 1;
BA_ "GenMsgCycleTimeFast" BO_ 829 20;
BA_ "VFrameFormat" BO_ 829 14;
BA_ "OriginFrame" BO_ 850 "ev";
BA_ "GenMsgILSupport" BO_ 850 1;
BA_ "GenMsgCycleTime" BO_ 850 500;
BA_ "VFrameFormat" BO_ 850 14;
BA_ "OriginFrame" BO_ 865 "ev";
BA_ "GenMsgILSupport" BO_ 865 1;
BA_ "GenMsgCycleTime" BO_ 865 500;
BA_ "VFrameFormat" BO_ 865 14;
BA_ "OriginFrame" BO_ 909 "ev";
BA_ "GenMsgILSupport" BO_ 909 1;
BA_ "GenMsgCycleTime" BO_ 909 1000;
BA_ "VFrameFormat" BO_ 909 14;
BA_ "OriginFrame" BO_ 937 "ev";
BA_ "GenMsgILSupport" BO_ 937 1;
BA_ "GenMsgCycleTime" BO_ 937 1000;
BA_ "VFrameFormat" BO_ 937 14;
BA_ "OriginFrame" BO_ 942 "ev";
BA_ "GenMsgILSupport" BO_ 942 1;
BA_ "GenMsgCycleTime" BO_ 942 1000;
BA_ "VFrameFormat" BO_ 942 14;
BA_ "OriginFrame" BO_ 957 "ev";
BA_ "GenMsgILSupport" BO_ 957 1;
BA_ "GenMsgCycleTime" BO_ 957 1000;
BA_ "VFrameFormat" BO_ 957 14;
BA_ "OriginFrame" BO_ 959 "ev";
BA_ "GenMsgILSupport" BO_ 959 1;
BA_ "GenMsgCycleTime" BO_ 959 1000;
BA_ "VFrameFormat" BO_ 959 14;
BA_ "OriginFrame" BO_ 963 "ev";
BA_ "GenMsgILSupport" BO_ 963 1;
BA_ "GenMsgCycleTime" BO_ 963 1000;
BA_ "VFrameFormat" BO_ 963 14;
BA_ "OriginFrame" BO_ 967 "ev";
BA_ "GenMsgILSupport" BO_ 967 1;
BA_ "GenMsgCycleTime" BO_ 967 1000;
BA_ "VFrameFormat" BO_ 967 14;
BA_ "OriginFrame" BO_ 976 "ev";
BA_ "GenMsgILSupport" BO_ 976 1;
BA_ "GenMsgCycleTime" BO_ 976 1000;
BA_ "VFrameFormat" BO_ 976 14;
BA_ "OriginFrame" BO_ 977 "ev";
BA_ "GenMsgILSupport" BO_ 977 1;
BA_ "GenMsgCycleTime" BO_ 977 1000;
BA_ "VFrameFormat" BO_ 977 14;
BA_ "OriginFrame" BO_ 978 "ev";
BA_ "GenMsgILSupport" BO_ 978 1;
BA_ "GenMsgCycleTime" BO_ 978 1000;
BA_ "VFrameFormat" BO_ 978 14;
BA_ "OriginFrame" BO_ 979 "ev";
BA_ "GenMsgILSupport" BO_ 979 1;
BA_ "GenMsgCycleTime" BO_ 979 1000;
BA_ "VFrameFormat" BO_ 979 14;
BA_ "OriginFrame" BO_ 980 "ev";
BA_ "GenMsgILSupport" BO_ 980 1;
BA_ "GenMsgCycleTime" BO_ 980 1000;
BA_ "VFrameFormat" BO_ 980 14;
BA_ "OriginFrame" BO_ 981 "ev";
BA_ "GenMsgILSupport" BO_ 981 1;
BA_ "GenMsgCycleTime" BO_ 981 1000;
BA_ "VFrameFormat" BO_ 981 14;
BA_ "OriginFrame" BO_ 1009 "ev";
BA_ "GenMsgILSupport" BO_ 1009 1;
BA_ "GenMsgCycleTime" BO_ 1009 1000;
BA_ "VFrameFormat" BO_ 1009 14;
BA_ "OriginFrame" BO_ 1010 "ev";
BA_ "GenMsgILSupport" BO_ 1010 1;
BA_ "GenMsgCycleTime" BO_ 1010 1000;
BA_ "VFrameFormat" BO_ 1010 14;
BA_ "OriginFrame" BO_ 1011 "ev";
BA_ "GenMsgILSupport" BO_ 1011 1;
BA_ "GenMsgCycleTime" BO_ 1011 1000;
BA_ "VFrameFormat" BO_ 1011 14;
BA_ "OriginFrame" BO_ 130 "fuel";
BA_ "GenMsgILSupport" BO_ 130 1;
BA_ "GenMsgCycleTime" BO_ 130 10;
BA_ "VFrameFormat" BO_ 130 14;
BA_ "OriginFrame" BO_ 132 "fuel";
BA_ "GenMsgILSupport" BO_ 132 1;
BA_ "GenMsgCycleTime" BO_ 132 10;
BA_ "VFrameFormat" BO_ 132 14;
BA_ "OriginFrame" BO_ 158 "fuel";
BA_ "GenMsgILSupport" BO_ 158 1;
BA_ "GenMsgCycleTime" BO_ 158 10;
BA_ "VFrameFormat" BO_ 158 14;
BA_ "OriginFrame" BO_ 258 "fuel";
BA_ "GenMsgILSupport" BO_ 258 1;
BA_ "GenMsgCycleTime" BO_ 258 20;
BA_ "VFrameFormat" BO_ 258 14;
BA_ "OriginFrame" BO_ 335 "fuel";
BA_ "GenMsgILSupport" BO_ 335 1;
BA_ "GenMsgCycleTime" BO_ 335 20;
BA_ "VFrameFormat" BO_ 335 14;
BA_ "OriginFrame" BO_ 486 "fuel";
BA_ "GenMsgSendType" BO_ 486 2;
BA_ "GenMsgNrOfRepetition" BO_ 486 5;
BA_ "GenMsgILSupport" BO_ 486 1;
BA_ "GenMsgCycleTimeFast" BO_ 486 50;
BA_ "VFrameFormat" BO_ 486 14;
BA_ "OriginFrame" BO_ 492 "fuel";
BA_ "GenMsgSendType" BO_ 492 2;
BA_ "GenMsgNrOfRepetition" BO_ 492 5;
BA_ "GenMsgILSupport" BO_ 492 1;
BA_ "GenMsgCycleTimeFast" BO_ 492 50;
BA_ "VFrameFormat" BO_ 492 14;
BA_ "OriginFrame" BO_ 724 "fuel";
BA_ "GenMsgILSupport" BO_ 724 1;
BA_ "GenMsgCycleTime" BO_ 724 100;
BA_ "VFrameFormat" BO_ 724 14;
BA_ "OriginFrame" BO_ 763 "fuel";
BA_ "GenMsgILSupport" BO_ 763 1;
BA_ "GenMsgCycleTime" BO_ 763 100;
BA_ "VFrameFormat" BO_ 763 14;
BA_ "OriginFrame" BO_ 848 "fuel";
BA_ "GenMsgILSupport" BO_ 848 1;
BA_ "GenMsgCycleTime" BO_ 848 500;
BA_ "VFrameFormat" BO_ 848 14;
BA_ "OriginFrame" BO_ 1560 "fuel";
BA_ "GenMsgSendType" BO_ 1560 2;
BA_ "DiagRequest" BO_ 1560 1;
BA_ "VFrameFormat" BO_ 1560 14;
BA_ "OriginFrame" BO_ 1561 "fuel";
BA_ "GenMsgSendType" BO_ 1561 2;
BA_ "DiagResponse" BO_ 1561 1;
BA_ "VFrameFormat" BO_ 1561 14;
BA_ "VFrameFormat" BO_ 1303 0;
BA_ "OriginFrame" BO_ 1303 "fuel";
BA_ "NmAsrMessage" BO_ 1303 1;
BA_ "GenMsgSendType" BO_ 1303 2;
BA_ "TransparentInitValue" SG_ 51 T_BOX_FD1_0x33 "0 0 0 0 0 7 3 255 0 0 0 0 0 0 0 0 ";
BA_ "GenSigSendType" SG_ 51 T_BOX_FD1_0x33 2;
BA_ "TransparentInitValue" SG_ 68 HUT7_0x44 "5 1 0 16 0 0 0 0 ";
BA_ "GenSigSendType" SG_ 68 HUT7_0x44 2;
BA_ "TransparentInitValue" SG_ 74 HUT6_0x4A "0 0 0 0 0 0 0 0 ";
BA_ "GenSigSendType" SG_ 74 HUT6_0x4A 2;
BA_ "TransparentInitValue" SG_ 86 GLO_NASS1_0x56 "0 0 0 0 0 0 0 0 ";
BA_ "GenSigSendType" SG_ 86 GLO_NASS1_0x56 2;
BA_ "TransparentInitValue" SG_ 161 CSA2_0xA1 "0 0 0 0 0 0 0 0 ";
BA_ "GenSigCycleTime" SG_ 161 CSA2_0xA1 10;
BA_ "TransparentInitValue" SG_ 166 DCT3_0xA6 "0 0 0 0 0 0 0 0 ";
BA_ "GenSigCycleTime" SG_ 166 DCT3_0xA6 10;
BA_ "TransparentInitValue" SG_ 200 ESP11_0xC8 "0 0 0 0 0 0 0 0 ";
BA_ "GenSigCycleTime" SG_ 200 ESP11_0xC8 10;
BA_ "TransparentInitValue" SG_ 241 BMS4_0xF1 "0 0 0 178 0 0 0 0 ";
BA_ "GenSigCycleTime" SG_ 241 BMS4_0xF1 10;
BA_ "TransparentInitValue" SG_ 265 IFC1_0x109 "0 112 4 0 127 224 0 0 ";
BA_ "GenSigCycleTime" SG_ 265 IFC1_0x109 20;
BA_ "TransparentInitValue" SG_ 273 ECM1_0x111 "0 0 0 0 0 0 0 128 ";
BA_ "GenSigCycleTime" SG_ 273 ECM1_0x111 10;
BA_ "TransparentInitValue" SG_ 288 Ibooster_FD2_0x120 "0 0 0 0 0 0 0 0 0 0 0 0 0 0 0 0 0 0 0 0 0 0 0 0 0 0 0 0 0 0 0 0 0 0 0 0 0 0 0 0 0 0 0 0 0 0 0 0 0 0 0 0 0 0 0 0 0 0 0 0 0 0 0 0 ";
BA_ "GenSigCycleTime" SG_ 288 Ibooster_FD2_0x120 20;
BA_ "TransparentInitValue" SG_ 311 ESP_FD2_0x137 "0 0 0 0 0 0 0 0 0 0 0 0 0 16 0 0 0 0 0 0 0 0 0 0 0 0 0 0 0 0 0 0 0 0 0 0 0 0 0 0 0 128 0 4 0 0 0 0 0 0 0 0 0 0 0 0 0 0 0 0 0 0 0 0 ";
BA_ "GenSigCycleTime" SG_ 311 ESP_FD2_0x137 20;
BA_ "TransparentInitValue" SG_ 327 EPS_FD1_0x147 "0 0 0 0 0 0 0 32 0 0 0 0 0 0 0 0 0 0 0 0 0 0 0 0 0 0 0 0 0 0 0 0 0 0 0 0 0 0 0 0 0 0 0 0 0 0 0 0 0 0 0 0 0 0 0 0 0 0 0 0 0 0 0 0 ";
BA_ "GenSigCycleTime" SG_ 327 EPS_FD1_0x147 20;
BA_ "TransparentInitValue" SG_ 338 ELD1_0x152 "0 0 0 0 0 0 0 0 ";
BA_ "GenSigCycleTime" SG_ 338 ELD1_0x152 20;
BA_ "TransparentInitValue" SG_ 347 HAP_FD1_0x15B "0 0 0 0 0 0 0 0 0 0 0 0 0 254 0 0 0 0 0 0 0 0 0 0 0 0 0 0 0 0 0 0 0 0 0 0 0 0 0 0 0 0 0 0 0 0 0 0 0 0 0 0 0 0 0 0 0 0 0 0 0 0 0 0 ";
BA_ "GenSigCycleTime" SG_ 347 HAP_FD1_0x15B 20;
BA_ "TransparentInitValue" SG_ 350 CR_FD1_0x15E "0 0 0 0 0 0 0 0 0 0 0 0 0 0 0 0 0 0 0 0 0 0 0 0 0 0 0 0 0 0 0 0 0 0 0 0 0 0 0 0 0 0 0 0 0 0 0 0 0 0 0 0 0 0 0 0 0 0 0 0 0 0 0 0 ";
BA_ "GenSigCycleTime" SG_ 350 CR_FD1_0x15E 20;
BA_ "TransparentInitValue" SG_ 357 CSA1_0x165 "0 0 0 0 0 0 0 0 ";
BA_ "GenSigCycleTime" SG_ 357 CSA1_0x165 20;
BA_ "TransparentInitValue" SG_ 363 EPB1_0x16B "0 0 0 0 0 0 0 0 ";
BA_ "GenSigCycleTime" SG_ 363 EPB1_0x16B 20;
BA_ "TransparentInitValue" SG_ 367 RSDS_FD1_0x16F "0 0 0 0 0 0 0 0 0 0 0 0 0 0 0 0 0 0 0 0 0 0 0 0 0 0 0 0 0 0 0 0 0 0 0 0 0 0 0 0 0 0 0 0 0 0 0 0 0 0 0 0 0 0 0 0 0 0 0 0 0 0 0 0 ";
BA_ "GenSigCycleTime" SG_ 367 RSDS_FD1_0x16F 20;
BA_ "TransparentInitValue" SG_ 368 ESP8_0x170 "0 0 0 0 0 0 0 0 ";
BA_ "GenSigCycleTime" SG_ 368 ESP8_0x170 20;
BA_ "TransparentInitValue" SG_ 395 AEB_FD1_0x18B "0 0 0 0 0 0 0 0 0 0 0 0 0 0 0 0 0 0 0 0 0 0 0 0 0 0 0 0 0 0 0 0 0 0 0 0 0 0 0 0 0 0 0 0 0 0 0 0 0 0 0 0 0 0 0 0 0 0 0 0 0 0 0 0 ";
BA_ "GenSigCycleTime" SG_ 395 AEB_FD1_0x18B 20;
BA_ "TransparentInitValue" SG_ 411 F_PBOX1_0x19B "0 0 0 0 0 0 0 0 ";
BA_ "GenSigCycleTime" SG_ 411 F_PBOX1_0x19B 50;
BA_ "TransparentInitValue" SG_ 412 R_PBOX1_0x19C "0 0 0 0 0 0 0 0 0 0 0 0 0 0 0 0 ";
BA_ "GenSigCycleTime" SG_ 412 R_PBOX1_0x19C 50;
BA_ "TransparentInitValue" SG_ 415 IFC_FD5_0x19F "0 88 75 208 151 83 0 0 0 88 75 208 151 83 0 0 0 88 75 208 151 83 0 0 0 88 75 208 151 83 0 0 0 88 75 208 151 83 0 0 0 88 75 208 151 83 0 0 0 0 0 0 0 0 0 0 0 0 0 0 0 0 0 0 ";
BA_ "GenSigCycleTime" SG_ 415 IFC_FD5_0x19F 50;
BA_ "TransparentInitValue" SG_ 465 HUT49_0x1D1 "0 0 0 0 0 0 0 0 ";
BA_ "GenSigSendType" SG_ 465 HUT49_0x1D1 2;
BA_ "TransparentInitValue" SG_ 473 GW_OTA_0x1D9 "0 0 0 0 0 0 0 0 ";
BA_ "GenSigSendType" SG_ 473 GW_OTA_0x1D9 2;
BA_ "TransparentInitValue" SG_ 474 HUT_FD4_0x1DA "0 0 0 0 0 0 0 0 0 0 0 0 0 0 0 0 0 0 0 0 0 0 0 0 0 0 0 0 0 0 0 0 0 0 0 0 0 0 0 0 0 0 0 0 0 0 0 0 0 0 0 0 0 0 0 0 0 0 0 0 0 0 0 0 ";
BA_ "GenSigSendType" SG_ 474 HUT_FD4_0x1DA 2;
BA_ "TransparentInitValue" SG_ 475 HUT_FD5_0x1DB "0 0 0 0 0 0 0 0 0 0 0 21 52 37 39 249 10 68 134 150 127 70 176 154 255 134 213 53 100 13 161 153 243 161 137 31 182 171 68 165 97 120 148 239 83 164 20 180 0 0 0 0 0 0 0 0 0 0 0 0 0 0 0 0 ";
BA_ "GenSigSendType" SG_ 475 HUT_FD5_0x1DB 2;
BA_ "TransparentInitValue" SG_ 476 HUT45_0x1DC "0 0 129 0 0 0 0 0 ";
BA_ "GenSigSendType" SG_ 476 HUT45_0x1DC 2;
BA_ "TransparentInitValue" SG_ 477 HUT46_0x1DD "0 0 0 0 0 0 0 0 ";
BA_ "GenSigSendType" SG_ 477 HUT46_0x1DD 2;
BA_ "TransparentInitValue" SG_ 479 DOCK2_0x1DF "0 0 0 0 0 0 0 0 0 0 0 21 52 37 39 249 10 68 134 150 127 70 176 154 255 134 213 53 100 13 161 153 243 161 137 31 182 171 68 165 97 120 148 239 83 164 20 180 0 0 0 0 0 0 0 0 0 0 0 0 0 0 0 0 ";
BA_ "GenSigSendType" SG_ 479 DOCK2_0x1DF 2;
BA_ "TransparentInitValue" SG_ 481 T_BOX_FD4_0x1E1 "0 0 0 0 0 0 192 0 0 0 0 0 0 0 0 0 ";
BA_ "GenSigSendType" SG_ 481 T_BOX_FD4_0x1E1 2;
BA_ "TransparentInitValue" SG_ 485 HUT35_0x1E5 "0 8 0 0 0 0 0 0 ";
BA_ "GenSigSendType" SG_ 485 HUT35_0x1E5 2;
BA_ "TransparentInitValue" SG_ 487 HUT38_0x1E7 "0 0 0 0 0 0 0 0 ";
BA_ "GenSigSendType" SG_ 487 HUT38_0x1E7 2;
BA_ "TransparentInitValue" SG_ 489 HUT30_0x1E9 "40 0 0 0 0 0 0 0 ";
BA_ "GenSigSendType" SG_ 489 HUT30_0x1E9 2;
BA_ "TransparentInitValue" SG_ 491 HUT39_0x1EB "0 0 0 0 0 64 128 128 ";
BA_ "GenSigSendType" SG_ 491 HUT39_0x1EB 2;
BA_ "TransparentInitValue" SG_ 493 HUT33_0x1ED "168 0 0 0 0 0 0 0 ";
BA_ "GenSigSendType" SG_ 493 HUT33_0x1ED 2;
BA_ "TransparentInitValue" SG_ 494 HUT15_0x1EE "5 81 0 2 0 0 0 0 0 0 0 0 0 0 0 0 ";
BA_ "GenSigSendType" SG_ 494 HUT15_0x1EE 2;
BA_ "TransparentInitValue" SG_ 497 ETC2_0x1F1 "0 0 0 0 0 0 0 0 ";
BA_ "GenSigSendType" SG_ 497 ETC2_0x1F1 2;
BA_ "TransparentInitValue" SG_ 498 ETC4_0x1F2 "0 0 0 0 0 0 0 0 ";
BA_ "GenSigSendType" SG_ 498 ETC4_0x1F2 2;
BA_ "TransparentInitValue" SG_ 505 HUT42_0x1F9 "0 0 0 0 0 0 0 0 ";
BA_ "GenSigSendType" SG_ 505 HUT42_0x1F9 2;
BA_ "TransparentInitValue" SG_ 506 BLE5_0x1FA "0 0 0 0 0 0 0 0 ";
BA_ "GenSigSendType" SG_ 506 BLE5_0x1FA 2;
BA_ "TransparentInitValue" SG_ 507 HUT41_0x1FB "128 128 129 128 0 0 0 0 ";
BA_ "GenSigSendType" SG_ 507 HUT41_0x1FB 2;
BA_ "TransparentInitValue" SG_ 509 HUT43_0x1FD "0 0 0 0 0 0 0 0 ";
BA_ "GenSigSendType" SG_ 509 HUT43_0x1FD 2;
BA_ "TransparentInitValue" SG_ 545 DCT5_0x221 "0 0 0 0 0 0 14 0 ";
BA_ "GenSigCycleTime" SG_ 545 DCT5_0x221 20;
BA_ "TransparentInitValue" SG_ 546 IFC_FD6_0x222 "0 0 0 0 1 146 201 0 0 0 0 0 0 0 0 0 0 0 0 201 0 0 201 0 0 0 0 0 0 0 0 0 0 100 128 0 0 0 201 0 0 0 0 0 0 0 0 0 0 0 0 0 0 0 0 0 0 0 0 0 0 0 0 0 ";
BA_ "GenSigCycleTime" SG_ 546 IFC_FD6_0x222 50;
BA_ "TransparentInitValue" SG_ 548 HUT40_0x224 "0 203 151 46 92 185 114 160 ";
BA_ "GenSigCycleTime" SG_ 548 HUT40_0x224 50;
BA_ "TransparentInitValue" SG_ 551 AEB_FD2_0x227 "0 0 0 0 0 0 0 0 0 200 0 0 0 0 0 0 0 0 0 0 0 0 0 0 0 0 0 0 0 120 0 0 0 120 0 0 0 120 0 0 0 0 0 0 0 0 0 0 0 0 0 0 0 0 0 0 0 0 0 0 0 0 0 0 ";
BA_ "GenSigCycleTime" SG_ 551 AEB_FD2_0x227 50;
BA_ "TransparentInitValue" SG_ 561 ABS1_0x231 "0 0 0 0 0 0 0 0 ";
BA_ "GenSigCycleTime" SG_ 561 ABS1_0x231 20;
BA_ "TransparentInitValue" SG_ 566 DCT_FD4_0x236 "0 0 0 0 0 0 0 0 0 0 0 0 0 0 0 0 0 0 0 0 0 0 0 0 0 0 0 0 0 0 0 0 0 0 0 0 0 0 0 0 0 0 0 0 0 0 0 0 0 0 0 0 0 0 0 0 0 0 0 0 0 0 0 0 ";
BA_ "GenSigCycleTime" SG_ 566 DCT_FD4_0x236 50;
BA_ "TransparentInitValue" SG_ 568 BCM12_0x238 "0 0 0 0 0 127 127 0 ";
BA_ "GenSigCycleTime" SG_ 568 BCM12_0x238 50;
BA_ "TransparentInitValue" SG_ 573 IFC_FD2_0x23D "0 0 0 0 0 0 0 0 0 0 0 0 0 0 0 0 0 0 0 0 0 0 0 0 0 127 240 0 156 9 192 0 0 156 9 192 0 0 0 0 0 0 0 0 0 0 0 0 0 0 0 0 0 0 0 0 0 0 0 0 0 0 0 0 ";
BA_ "GenSigCycleTime" SG_ 573 IFC_FD2_0x23D 50;
BA_ "TransparentInitValue" SG_ 579 HUT_FD3_0x243 "0 0 0 0 0 0 0 0 0 0 0 0 0 0 0 0 0 0 0 0 0 0 0 0 0 0 0 0 0 0 0 0 0 0 0 0 0 0 0 0 0 0 0 0 0 0 0 0 0 0 0 0 0 0 0 0 0 0 0 0 0 0 0 0 ";
BA_ "GenSigCycleTime" SG_ 579 HUT_FD3_0x243 50;
BA_ "TransparentInitValue" SG_ 580 CSA3_0x244 "0 0 0 0 0 0 0 0 ";
BA_ "GenSigCycleTime" SG_ 580 CSA3_0x244 50;
BA_ "TransparentInitValue" SG_ 581 ABM2_0x245 "0 86 17 86 17 34 17 0 ";
BA_ "GenSigCycleTime" SG_ 581 ABM2_0x245 20;
BA_ "TransparentInitValue" SG_ 582 ABS2_0x246 "0 0 0 0 0 0 0 0 ";
BA_ "GenSigCycleTime" SG_ 582 ABS2_0x246 20;
BA_ "TransparentInitValue" SG_ 584 HCU_PT7_0x248 "0 0 0 0 0 0 0 0 ";
BA_ "GenSigCycleTime" SG_ 584 HCU_PT7_0x248 50;
BA_ "TransparentInitValue" SG_ 589 DMS_FD1_0x24D "0 63 240 0 31 254 0 0 0 254 254 252 0 0 0 0 0 255 255 255 255 255 0 0 0 255 255 255 255 128 0 0 0 255 255 255 254 224 0 0 0 255 255 200 200 254 167 0 0 0 0 0 0 0 0 0 0 0 0 0 0 0 0 0 ";
BA_ "GenSigCycleTime" SG_ 589 DMS_FD1_0x24D 50;
BA_ "TransparentInitValue" SG_ 593 TOD1_0x251 "0 0 0 0 0 0 0 0 ";
BA_ "GenSigCycleTime" SG_ 593 TOD1_0x251 20;
BA_ "TransparentInitValue" SG_ 604 BLE1_0x25C "0 0 0 0 0 0 0 0 ";
BA_ "GenSigCycleTime" SG_ 604 BLE1_0x25C 50;
BA_ "TransparentInitValue" SG_ 623 HUT32_0x26F "0 0 255 231 255 0 0 0 ";
BA_ "GenSigCycleTime" SG_ 623 HUT32_0x26F 50;
BA_ "TransparentInitValue" SG_ 625 ECM2_0x271 "0 0 0 0 0 0 4 0 ";
BA_ "GenSigCycleTime" SG_ 625 ECM2_0x271 20;
BA_ "TransparentInitValue" SG_ 627 Trailer1_0x273 "0 0 0 0 0 0 0 0 ";
BA_ "GenSigCycleTime" SG_ 627 Trailer1_0x273 50;
BA_ "TransparentInitValue" SG_ 628 HAP_FD2_0x274 "0 0 0 0 0 0 0 0 0 0 0 0 0 0 0 0 0 0 0 0 0 0 0 0 0 0 0 0 0 0 0 0 0 0 0 0 0 0 0 0 0 0 0 0 0 0 0 0 0 0 0 0 0 0 0 0 0 0 0 0 0 0 0 0 ";
BA_ "GenSigCycleTime" SG_ 628 HAP_FD2_0x274 50;
BA_ "TransparentInitValue" SG_ 636 AC8_0x27C "0 0 0 132 0 254 0 0 ";
BA_ "GenSigCycleTime" SG_ 636 AC8_0x27C 50;
BA_ "TransparentInitValue" SG_ 639 IP2_0x27F "0 0 0 0 0 0 0 0 0 0 0 0 0 0 0 0 ";
BA_ "GenSigCycleTime" SG_ 639 IP2_0x27F 50;
BA_ "TransparentInitValue" SG_ 647 ALS1_0x287 "0 0 0 0 0 0 0 0 0 0 0 0 0 0 0 0 ";
BA_ "GenSigCycleTime" SG_ 647 ALS1_0x287 100;
BA_ "TransparentInitValue" SG_ 649 HAP_FD6_0x289 "0 0 0 0 0 0 0 16 0 0 0 0 0 0 0 0 0 0 0 0 0 0 0 0 0 0 0 0 0 0 0 0 0 85 0 0 0 0 0 0 0 0 0 0 0 0 0 0 0 0 0 0 0 0 0 0 0 0 0 0 0 0 0 0 ";
BA_ "GenSigCycleTime" SG_ 649 HAP_FD6_0x289 100;
BA_ "TransparentInitValue" SG_ 653 BCM7_0x28D "0 0 0 0 0 0 0 0 ";
BA_ "GenSigCycleTime" SG_ 653 BCM7_0x28D 100;
BA_ "TransparentInitValue" SG_ 656 ECM_PT6_0x290 "0 0 0 0 0 0 0 0 ";
BA_ "GenSigCycleTime" SG_ 656 ECM_PT6_0x290 100;
BA_ "TransparentInitValue" SG_ 659 IP1_0x293 "0 0 16 10 2 188 0 0 ";
BA_ "GenSigCycleTime" SG_ 659 IP1_0x293 100;
BA_ "TransparentInitValue" SG_ 661 PEPS2_0x295 "0 0 0 0 0 0 0 0 ";
BA_ "GenSigCycleTime" SG_ 661 PEPS2_0x295 50;
BA_ "TransparentInitValue" SG_ 664 HAP_FD3_0x298 "0 255 254 254 0 0 0 0 0 0 0 0 0 0 0 0 0 0 0 0 0 0 0 0 0 0 0 0 0 0 7 240 0 0 0 0 0 0 0 0 0 0 0 0 0 0 0 0 0 0 0 0 0 0 0 0 0 0 0 0 0 0 0 0 ";
BA_ "GenSigCycleTime" SG_ 664 HAP_FD3_0x298 100;
BA_ "TransparentInitValue" SG_ 665 AC14_0x299 "0 0 0 0 0 0 0 0 ";
BA_ "GenSigCycleTime" SG_ 665 AC14_0x299 100;
BA_ "TransparentInitValue" SG_ 667 HAP_FD7_0x29B "0 0 0 0 0 0 0 0 0 0 0 0 0 0 0 0 0 0 0 0 0 0 0 0 0 0 0 0 0 0 0 0 0 0 0 0 0 0 0 0 0 0 0 0 0 0 255 192 0 0 0 0 0 0 0 0 0 0 0 0 0 0 0 0 ";
BA_ "GenSigCycleTime" SG_ 667 HAP_FD7_0x29B 100;
BA_ "TransparentInitValue" SG_ 669 AC1_0x29D "0 254 224 0 0 0 0 0 ";
BA_ "GenSigCycleTime" SG_ 669 AC1_0x29D 100;
BA_ "TransparentInitValue" SG_ 671 BCM8_0x29F "0 0 0 0 0 0 0 0 ";
BA_ "GenSigCycleTime" SG_ 671 BCM8_0x29F 100;
BA_ "TransparentInitValue" SG_ 675 BCM14_0x2A3 "0 0 0 0 0 0 0 0 ";
BA_ "GenSigCycleTime" SG_ 675 BCM14_0x2A3 100;
BA_ "TransparentInitValue" SG_ 680 EEM1_0x2A8 "0 0 0 0 0 0 0 0 ";
BA_ "GenSigCycleTime" SG_ 680 EEM1_0x2A8 100;
BA_ "TransparentInitValue" SG_ 683 ACC_FD2_0x2AB "0 0 0 0 0 0 0 0 0 0 4 127 255 0 0 0 0 0 8 0 0 32 255 0 0 0 0 0 0 0 0 0 0 0 0 0 0 0 0 0 0 0 0 0 0 0 0 0 0 60 120 121 224 0 0 0 0 0 0 0 0 0 0 0 ";
BA_ "GenSigCycleTime" SG_ 683 ACC_FD2_0x2AB 100;
BA_ "TransparentInitValue" SG_ 692 ACC_FD3_0x2B4 "0 0 0 0 0 0 0 0 0 255 0 0 0 0 255 0 0 0 0 0 0 0 0 0 0 0 0 0 0 0 0 0 0 0 0 0 0 0 0 0 0 0 0 0 0 0 0 0 0 0 0 0 0 0 0 0 0 0 0 0 0 0 0 0 ";
BA_ "GenSigCycleTime" SG_ 692 ACC_FD3_0x2B4 100;
BA_ "TransparentInitValue" SG_ 694 HUT26_0x2B6 "0 0 0 0 0 0 0 0 ";
BA_ "GenSigCycleTime" SG_ 694 HUT26_0x2B6 100;
BA_ "TransparentInitValue" SG_ 696 ACC_FD4_0x2B8 "255 0 0 0 0 0 0 0 0 0 0 0 0 0 0 255 0 0 0 0 0 0 0 0 0 0 255 0 0 0 0 0 0 0 0 0 0 0 0 255 0 0 0 0 0 0 0 0 0 0 0 0 127 255 127 255 254 252 252 252 0 0 0 0 ";
BA_ "GenSigCycleTime" SG_ 696 ACC_FD4_0x2B8 100;
BA_ "TransparentInitValue" SG_ 697 DWD1_0x2B9 "0 0 0 0 0 0 0 0 ";
BA_ "GenSigCycleTime" SG_ 697 DWD1_0x2B9 100;
BA_ "TransparentInitValue" SG_ 698 WPC1_0x2BA "0 0 0 0 0 0 0 0 ";
BA_ "GenSigCycleTime" SG_ 698 WPC1_0x2BA 100;
BA_ "TransparentInitValue" SG_ 699 GW_FD1_0x2BB "0 0 0 0 0 0 0 0 255 255 255 255 0 0 0 0 255 255 0 0 0 0 240 0 0 0 0 0 0 0 0 0 0 0 0 0 0 0 0 0 0 0 0 0 0 0 0 0 0 0 0 0 0 0 0 0 0 0 0 0 0 0 0 0 ";
BA_ "GenSigCycleTime" SG_ 699 GW_FD1_0x2BB 100;
BA_ "TransparentInitValue" SG_ 705 DSM1_0x2C1 "0 0 0 0 0 0 0 0 ";
BA_ "GenSigCycleTime" SG_ 705 DSM1_0x2C1 100;
BA_ "TransparentInitValue" SG_ 707 HUT_FD1_0x2C3 "0 0 0 0 0 0 0 0 65 5 192 128 0 2 0 30 0 0 0 0 0 0 0 0 0 0 0 0 0 0 0 0 0 1 39 1 0 0 0 16 31 255 0 0 0 1 255 0 0 0 0 0 0 0 0 0 0 0 0 0 0 0 0 0 ";
BA_ "GenSigCycleTime" SG_ 707 HUT_FD1_0x2C3 100;
BA_ "TransparentInitValue" SG_ 714 DDCM1_0x2CA "0 0 0 0 0 0 0 0 ";
BA_ "GenSigCycleTime" SG_ 714 DDCM1_0x2CA 100;
BA_ "TransparentInitValue" SG_ 716 AC4_0x2CC "0 0 0 0 0 0 0 0 ";
BA_ "GenSigCycleTime" SG_ 716 AC4_0x2CC 100;
BA_ "TransparentInitValue" SG_ 717 PDCM1_0x2CD "0 0 0 0 0 0 0 0 ";
BA_ "GenSigCycleTime" SG_ 717 PDCM1_0x2CD 100;
BA_ "TransparentInitValue" SG_ 718 DSC4_0x2CE "0 0 0 0 0 0 0 0 ";
BA_ "GenSigCycleTime" SG_ 718 DSC4_0x2CE 100;
BA_ "TransparentInitValue" SG_ 719 IFC_FD3_0x2CF "0 0 0 0 0 0 0 0 0 32 0 0 15 0 0 0 0 0 0 0 0 0 0 0 0 0 0 0 0 0 0 0 0 0 0 0 0 0 0 0 0 0 0 0 0 0 0 0 0 0 0 0 0 0 0 0 0 0 0 0 0 0 0 0 ";
BA_ "GenSigCycleTime" SG_ 719 IFC_FD3_0x2CF 100;
BA_ "TransparentInitValue" SG_ 720 AC7_0x2D0 "0 0 0 0 0 0 0 0 ";
BA_ "GenSigCycleTime" SG_ 720 AC7_0x2D0 100;
BA_ "TransparentInitValue" SG_ 721 SCM1_0x2D1 "0 0 0 0 0 0 0 0 ";
BA_ "GenSigCycleTime" SG_ 721 SCM1_0x2D1 100;
BA_ "TransparentInitValue" SG_ 722 AMP4_ANC1_0x2D2 "0 0 0 0 0 0 0 4 ";
BA_ "GenSigSendType" SG_ 722 AMP4_ANC1_0x2D2 2;
BA_ "TransparentInitValue" SG_ 723 ECM11_0x2D3 "0 0 0 0 0 0 0 0 ";
BA_ "GenSigCycleTime" SG_ 723 ECM11_0x2D3 100;
BA_ "TransparentInitValue" SG_ 728 HUT23_0x2D8 "0 0 0 0 0 0 0 0 ";
BA_ "GenSigSendType" SG_ 728 HUT23_0x2D8 2;
BA_ "TransparentInitValue" SG_ 730 HUT22_0x2DA "0 0 0 0 0 0 0 0 ";
BA_ "GenSigSendType" SG_ 730 HUT22_0x2DA 2;
BA_ "TransparentInitValue" SG_ 733 HUT21_0x2DD "0 0 0 0 192 0 0 0 ";
BA_ "GenSigSendType" SG_ 733 HUT21_0x2DD 2;
BA_ "TransparentInitValue" SG_ 734 HUT20_0x2DE "0 0 0 0 0 0 0 0 ";
BA_ "GenSigSendType" SG_ 734 HUT20_0x2DE 2;
BA_ "TransparentInitValue" SG_ 748 DVR_FD1_0x2EC "0 0 0 0 0 0 0 0 0 0 0 0 0 0 0 0 0 0 0 0 0 0 0 0 0 0 0 0 0 0 0 0 0 0 0 0 0 0 0 0 0 0 0 0 0 0 0 0 0 0 0 0 0 0 0 0 0 0 0 0 0 0 0 0 ";
BA_ "GenSigCycleTime" SG_ 748 DVR_FD1_0x2EC 100;
BA_ "TransparentInitValue" SG_ 752 T_BOX_FD10_0x2F0 "0 0 0 0 0 0 0 0 0 0 255 0 0 0 0 0 0 0 0 0 0 0 0 0 0 0 0 0 0 0 0 0 0 0 0 0 0 0 0 0 0 0 0 0 0 0 0 0 0 0 0 0 0 0 0 0 0 0 0 0 0 0 0 0 ";
BA_ "GenSigCycleTime" SG_ 752 T_BOX_FD10_0x2F0 100;
BA_ "TransparentInitValue" SG_ 759 DDCM3_0x2F7 "0 0 0 0 0 0 0 0 ";
BA_ "GenSigCycleTime" SG_ 759 DDCM3_0x2F7 100;
BA_ "TransparentInitValue" SG_ 760 AC6_0x2F8 "0 0 0 0 0 0 0 0 ";
BA_ "GenSigCycleTime" SG_ 760 AC6_0x2F8 100;
BA_ "TransparentInitValue" SG_ 762 HCU_PT4_0x2FA "0 0 20 0 0 0 4 0 ";
BA_ "GenSigCycleTime" SG_ 762 HCU_PT4_0x2FA 100;
BA_ "TransparentInitValue" SG_ 765 AC3_0x2FD "0 0 0 0 240 192 0 0 ";
BA_ "GenSigCycleTime" SG_ 765 AC3_0x2FD 100;
BA_ "TransparentInitValue" SG_ 770 PEPS4_0x302 "0 0 0 0 0 0 0 0 ";
BA_ "GenSigCycleTime" SG_ 770 PEPS4_0x302 200;
BA_ "TransparentInitValue" SG_ 771 ESCL2_0x303 "0 0 0 0 0 0 0 0 ";
BA_ "GenSigCycleTime" SG_ 771 ESCL2_0x303 200;
BA_ "TransparentInitValue" SG_ 772 HCM_L2_0x304 "0 0 0 0 0 0 0 0 ";
BA_ "GenSigCycleTime" SG_ 772 HCM_L2_0x304 200;
BA_ "TransparentInitValue" SG_ 773 BCM11_0x305 "0 0 0 0 0 0 0 0 ";
BA_ "GenSigCycleTime" SG_ 773 BCM11_0x305 100;
BA_ "TransparentInitValue" SG_ 776 HCM_L1_0x308 "0 0 0 0 0 0 0 0 ";
BA_ "GenSigCycleTime" SG_ 776 HCM_L1_0x308 200;
BA_ "TransparentInitValue" SG_ 778 RSDS_FD2_0x30A "0 0 0 0 0 0 0 0 0 0 0 0 0 0 0 0 0 0 0 0 0 0 0 0 0 0 0 0 0 0 0 0 0 0 0 0 0 0 0 0 0 0 0 0 0 0 0 0 0 0 0 0 0 0 0 0 0 0 0 0 0 0 0 0 ";
BA_ "GenSigCycleTime" SG_ 778 RSDS_FD2_0x30A 200;
BA_ "TransparentInitValue" SG_ 780 HUT31_0x30C "0 0 0 0 0 0 0 0 ";
BA_ "GenSigCycleTime" SG_ 780 HUT31_0x30C 200;
BA_ "TransparentInitValue" SG_ 781 HCM_R1_0x30D "0 0 0 0 0 0 0 0 ";
BA_ "GenSigCycleTime" SG_ 781 HCM_R1_0x30D 200;
BA_ "TransparentInitValue" SG_ 783 BCM19_0x30F "0 0 0 0 0 0 0 0 ";
BA_ "GenSigCycleTime" SG_ 783 BCM19_0x30F 100;
BA_ "TransparentInitValue" SG_ 785 DOCK1_0x311 "0 0 0 0 0 0 0 0 0 0 0 21 52 37 39 249 10 68 134 150 127 70 176 154 255 134 213 53 100 13 161 153 243 161 137 31 182 171 68 165 97 120 148 239 83 164 20 180 0 0 0 0 0 0 0 0 0 0 0 0 0 0 0 0 ";
BA_ "GenSigCycleTime" SG_ 785 DOCK1_0x311 200;
BA_ "TransparentInitValue" SG_ 793 BCM1_0x319 "0 0 0 0 128 0 0 0 0 0 0 0 0 0 0 0 ";
BA_ "GenSigCycleTime" SG_ 793 BCM1_0x319 50;
BA_ "TransparentInitValue" SG_ 796 HUT13_0x31C "0 1 0 0 240 0 64 0 ";
BA_ "GenSigCycleTime" SG_ 796 HUT13_0x31C 100;
BA_ "TransparentInitValue" SG_ 805 HUD1_0x325 "0 65 40 0 0 252 0 0 ";
BA_ "GenSigCycleTime" SG_ 805 HUD1_0x325 200;
BA_ "TransparentInitValue" SG_ 816 HCM_R2_0x330 "0 0 0 0 0 0 0 0 ";
BA_ "GenSigCycleTime" SG_ 816 HCM_R2_0x330 200;
BA_ "TransparentInitValue" SG_ 817 HUT10_0x331 "0 0 0 1 0 0 0 60 ";
BA_ "GenSigSendType" SG_ 817 HUT10_0x331 2;
BA_ "TransparentInitValue" SG_ 818 RFCM_L1_0x332 "0 0 0 0 0 0 0 0 ";
BA_ "GenSigCycleTime" SG_ 818 RFCM_L1_0x332 200;
BA_ "TransparentInitValue" SG_ 819 RFCM_R1_0x333 "0 0 0 0 0 0 0 0 ";
BA_ "GenSigCycleTime" SG_ 819 RFCM_R1_0x333 200;
BA_ "TransparentInitValue" SG_ 825 HUT25_0x339 "0 0 0 0 0 0 0 192 ";
BA_ "GenSigSendType" SG_ 825 HUT25_0x339 2;
BA_ "TransparentInitValue" SG_ 827 HUT17_0x33B "0 0 64 51 165 0 16 0 ";
BA_ "GenSigSendType" SG_ 827 HUT17_0x33B 2;
BA_ "TransparentInitValue" SG_ 833 TPMS1_0x341 "0 0 0 0 0 0 0 0 0 0 0 0 0 0 0 0 ";
BA_ "GenSigCycleTime" SG_ 833 TPMS1_0x341 500;
BA_ "TransparentInitValue" SG_ 836 ETC3_0x344 "168 0 0 0 0 0 0 0 ";
BA_ "GenSigCycleTime" SG_ 836 ETC3_0x344 500;
BA_ "TransparentInitValue" SG_ 837 BCM3_0x345 "0 0 0 0 0 0 0 0 0 0 0 0 0 0 0 0 ";
BA_ "GenSigCycleTime" SG_ 837 BCM3_0x345 50;
BA_ "TransparentInitValue" SG_ 840 HUT16_0x348 "0 0 0 0 128 0 0 0 ";
BA_ "GenSigCycleTime" SG_ 840 HUT16_0x348 500;
BA_ "TransparentInitValue" SG_ 842 IP3_0x34A "0 0 0 255 255 255 192 0 0 0 0 0 0 0 0 0 ";
BA_ "GenSigCycleTime" SG_ 842 IP3_0x34A 500;
BA_ "TransparentInitValue" SG_ 845 BCM18_0x34D "0 0 0 0 0 0 0 0 ";
BA_ "GenSigCycleTime" SG_ 845 BCM18_0x34D 500;
BA_ "TransparentInitValue" SG_ 849 ABM1_0x351 "0 126 0 85 1 0 0 0 0 0 0 0 0 0 0 0 ";
BA_ "GenSigCycleTime" SG_ 849 ABM1_0x351 500;
BA_ "TransparentInitValue" SG_ 862 CP1_0x35E "0 0 0 0 0 0 0 0 ";
BA_ "GenSigCycleTime" SG_ 862 CP1_0x35E 500;
BA_ "TransparentInitValue" SG_ 871 HUT1_0x367 "34 80 0 0 16 1 0 0 ";
BA_ "GenSigSendType" SG_ 871 HUT1_0x367 2;
BA_ "TransparentInitValue" SG_ 873 HUT2_0x369 "0 82 80 82 16 80 82 0 ";
BA_ "GenSigSendType" SG_ 873 HUT2_0x369 2;
BA_ "TransparentInitValue" SG_ 875 HUT3_0x36B "40 40 40 40 0 8 0 0 ";
BA_ "GenSigSendType" SG_ 875 HUT3_0x36B 2;
BA_ "TransparentInitValue" SG_ 877 HUT4_0x36D "0 0 32 0 0 0 0 64 ";
BA_ "GenSigSendType" SG_ 877 HUT4_0x36D 2;
BA_ "TransparentInitValue" SG_ 880 HUT34_0x370 "0 248 252 252 255 0 0 0 ";
BA_ "GenSigCycleTime" SG_ 880 HUT34_0x370 1000;
BA_ "TransparentInitValue" SG_ 881 ECM3_0x371 "0 0 0 0 0 16 128 0 ";
BA_ "GenSigCycleTime" SG_ 881 ECM3_0x371 100;
BA_ "TransparentInitValue" SG_ 901 AC2_0x385 "0 15 254 0 66 6 33 0 ";
BA_ "GenSigCycleTime" SG_ 901 AC2_0x385 100;
BA_ "TransparentInitValue" SG_ 917 TPMS2_0x395 "0 0 0 0 0 0 0 0 0 0 0 0 0 0 0 0 ";
BA_ "GenSigCycleTime" SG_ 917 TPMS2_0x395 500;
BA_ "TransparentInitValue" SG_ 943 HUT12_0x3AF "0 0 0 0 0 0 0 0 ";
BA_ "GenSigCycleTime" SG_ 943 HUT12_0x3AF 1000;
BA_ "TransparentInitValue" SG_ 949 ECM19_0x3B5 "0 0 0 0 0 0 0 0 ";
BA_ "GenSigCycleTime" SG_ 949 ECM19_0x3B5 1000;
BA_ "TransparentInitValue" SG_ 951 ECM20_0x3B7 "0 0 0 0 0 0 0 0 ";
BA_ "GenSigCycleTime" SG_ 951 ECM20_0x3B7 1000;
BA_ "TransparentInitValue" SG_ 962 HCU_HC7_0x3C2 "0 0 0 0 0 0 0 0 ";
BA_ "GenSigCycleTime" SG_ 962 HCU_HC7_0x3C2 1000;
BA_ "TransparentInitValue" SG_ 993 AMP1_0x3E1 "0 0 0 0 0 0 32 0 ";
BA_ "GenSigSendType" SG_ 993 AMP1_0x3E1 2;
BA_ "TransparentInitValue" SG_ 995 AMP2_0x3E3 "0 82 80 82 0 82 82 51 0 0 0 0 0 0 0 0 ";
BA_ "GenSigSendType" SG_ 995 AMP2_0x3E3 2;
BA_ "TransparentInitValue" SG_ 997 AMP3_0x3E5 "40 40 40 40 60 4 0 0 ";
BA_ "GenSigSendType" SG_ 997 AMP3_0x3E5 2;
BA_ "TransparentInitValue" SG_ 1001 T_BOX_FD3_0x3E9 "0 0 0 0 0 0 0 0 0 0 0 0 0 0 0 0 ";
BA_ "GenSigCycleTime" SG_ 1001 T_BOX_FD3_0x3E9 1000;
BA_ "TransparentInitValue" SG_ 1045 HUT19_0x415 "0 0 0 0 128 0 0 0 ";
BA_ "GenSigCycleTime" SG_ 1045 HUT19_0x415 5000;
BA_ "Origin" SG_ 1888 DiagFuncReq "fuel,ev";
BA_ "Match" SG_ 1888 DiagFuncReq "DiagFuncReq";
BA_ "Origin" SG_ 1889 GW_Phy_Req "fuel,ev";
BA_ "Match" SG_ 1889 GW_Phy_Req "GW_Phy_Req";
BA_ "Origin" SG_ 1918 T_Box_Phy_Req "fuel,ev";
BA_ "Match" SG_ 1918 T_Box_Phy_Req "T_Box_Phy_Req";
BA_ "Origin" SG_ 1843 XBOX_D_Phy_Req "fuel,ev";
BA_ "Match" SG_ 1843 XBOX_D_Phy_Req "XBOX_D_Phy_Req";
BA_ "Origin" SG_ 1907 HUT_Phy_Req "fuel,ev";
BA_ "Match" SG_ 1907 HUT_Phy_Req "HUT_Phy_Req";
BA_ "Origin" SG_ 1953 GW_Phy_Resp "fuel,ev";
BA_ "Match" SG_ 1953 GW_Phy_Resp "GW_Phy_Resp";
BA_ "Origin" SG_ 1982 T_Box_Phy_Resp "fuel,ev";
BA_ "Match" SG_ 1982 T_Box_Phy_Resp "T_Box_Phy_Resp";
BA_ "Origin" SG_ 1844 XBOX_D_Phy_Resp "fuel,ev";
BA_ "Match" SG_ 1844 XBOX_D_Phy_Resp "XBOX_D_Phy_Resp";
BA_ "Origin" SG_ 1971 HUT_Phy_Resp "fuel,ev";
BA_ "Match" SG_ 1971 HUT_Phy_Resp "HUT_Phy_Resp";
BA_ "Origin" SG_ 1290 Destination_T_Box_NM "fuel,ev";
BA_ "Match" SG_ 1290 Destination_T_Box_NM "Destination_T_Box_NM";
BA_ "Origin" SG_ 1290 OpCode_T_Box_NM "fuel,ev";
BA_ "Match" SG_ 1290 OpCode_T_Box_NM "OpCode_T_Box_NM";
BA_ "Origin" SG_ 1289 Destination_HUT_NM "fuel,ev";
BA_ "Match" SG_ 1289 Destination_HUT_NM "Destination_HUT_NM";
BA_ "Origin" SG_ 1289 OpCode_HUT_NM "fuel,ev";
BA_ "Match" SG_ 1289 OpCode_HUT_NM "OpCode_HUT_NM";
BA_ "Origin" SG_ 1334 Destination_XBOX_D_NM "fuel,ev";
BA_ "Match" SG_ 1334 Destination_XBOX_D_NM "Destination_XBOX_D_NM";
BA_ "Origin" SG_ 1334 OpCode_XBOX_D_NM "fuel,ev";
BA_ "Match" SG_ 1334 OpCode_XBOX_D_NM "OpCode_XBOX_D_NM";
BA_ "Origin" SG_ 1281 Destination_CEM_NM "fuel,ev";
BA_ "Match" SG_ 1281 Destination_CEM_NM "Destination_CEM_NM";
BA_ "Origin" SG_ 1281 OpCode_CEM_NM "fuel,ev";
BA_ "Match" SG_ 1281 OpCode_CEM_NM "OpCode_CEM_NM";
BA_ "Origin" SG_ 1122 SyncRequestMessageId "fuel,ev";
BA_ "Match" SG_ 1122 SyncRequestMessageId "SyncRequestMessageId";
BA_ "GenSigSendType" SG_ 1122 SyncRequestMessageId 2;
BA_ "Origin" SG_ 1122 SyncRequstReseverData "fuel,ev";
BA_ "Match" SG_ 1122 SyncRequstReseverData "SyncRequstReseverData";
BA_ "GenSigSendType" SG_ 1122 SyncRequstReseverData 2;
BA_ "Origin" SG_ 1121 ResetCount "fuel,ev";
BA_ "Match" SG_ 1121 ResetCount "ResetCount";
BA_ "Origin" SG_ 1121 CMACMessageInfo "fuel,ev";
BA_ "Match" SG_ 1121 CMACMessageInfo "CMACMessageInfo";
BA_ "Origin" SG_ 1121 TripCount "fuel,ev";
BA_ "Match" SG_ 1121 TripCount "TripCount";
BA_ "Origin" SG_ 53 PEPS_T_BOXAuth1 "ev";
BA_ "Match" SG_ 53 PEPS_T_BOXAuth1 "PEPS_T_BOXAuth1";
BA_ "GenSigSendType" SG_ 53 PEPS_T_BOXAuth1 2;
BA_ "Origin" SG_ 54 T_BOX_PEPSAuth1 "ev";
BA_ "Match" SG_ 54 T_BOX_PEPSAuth1 "T_BOX_PEPSAuth1";
BA_ "GenSigSendType" SG_ 54 T_BOX_PEPSAuth1 2;
BA_ "Origin" SG_ 70 PEPS_T_BOXAuth2 "ev";
BA_ "Match" SG_ 70 PEPS_T_BOXAuth2 "PEPS_T_BOXAuth2";
BA_ "GenSigSendType" SG_ 70 PEPS_T_BOXAuth2 2;
BA_ "Origin" SG_ 72 T_BOX_PEPSAuth2 "ev";
BA_ "Match" SG_ 72 T_BOX_PEPSAuth2 "T_BOX_PEPSAuth2";
BA_ "GenSigSendType" SG_ 72 T_BOX_PEPSAuth2 2;
BA_ "TransparentInitValue" SG_ 96 HCU_FD1_0x60 "0 0 0 0 0 0 0 0 0 0 32 0 0 0 0 128 0 0 0 0 0 0 0 0 0 0 0 0 0 0 0 0 0 0 0 0 0 0 0 0 0 0 0 0 0 8 0 0 0 0 0 0 0 0 0 0 0 0 0 0 0 0 0 0 ";
BA_ "GenSigCycleTime" SG_ 96 HCU_FD1_0x60 10;
BA_ "TransparentInitValue" SG_ 142 ECM_PT5_0x8E "0 0 0 0 0 0 0 32 ";
BA_ "GenSigCycleTime" SG_ 142 ECM_PT5_0x8E 10;
BA_ "TransparentInitValue" SG_ 172 P2M1_0xAC "0 0 0 0 127 252 0 0 ";
BA_ "GenSigCycleTime" SG_ 172 P2M1_0xAC 10;
BA_ "TransparentInitValue" SG_ 190 P2M3_0xBE "0 255 224 0 0 0 0 0 ";
BA_ "GenSigCycleTime" SG_ 190 P2M3_0xBE 10;
BA_ "TransparentInitValue" SG_ 249 HCU_HP8_0xF9 "0 0 1 19 0 0 0 0 ";
BA_ "GenSigCycleTime" SG_ 249 HCU_HP8_0xF9 10;
BA_ "TransparentInitValue" SG_ 279 ECM_PT7_0x117 "0 0 0 0 0 0 0 0 ";
BA_ "GenSigCycleTime" SG_ 279 ECM_PT7_0x117 20;
BA_ "TransparentInitValue" SG_ 282 HCU_HP6_0x11A "0 0 0 0 28 0 0 0 ";
BA_ "GenSigCycleTime" SG_ 282 HCU_HP6_0x11A 20;
BA_ "TransparentInitValue" SG_ 301 EBOOSTER_FD1_0x12D "0 0 0 0 0 0 0 0 0 0 0 0 0 0 0 0 0 0 0 0 0 0 0 0 0 0 0 0 0 0 0 0 0 0 0 0 0 0 0 0 0 0 0 0 0 0 0 0 0 0 0 0 0 0 0 0 0 0 0 0 0 0 0 0 ";
BA_ "GenSigCycleTime" SG_ 301 EBOOSTER_FD1_0x12D 20;
BA_ "TransparentInitValue" SG_ 330 HCU_PT5_0x14A "0 0 0 100 100 0 0 0 ";
BA_ "GenSigCycleTime" SG_ 330 HCU_PT5_0x14A 20;
BA_ "TransparentInitValue" SG_ 448 HCU_PT8_0x1C0 "0 0 0 0 0 0 0 0 ";
BA_ "GenSigCycleTime" SG_ 448 HCU_PT8_0x1C0 50;
BA_ "TransparentInitValue" SG_ 482 HCU_HC8_0x1E2 "0 0 0 0 0 0 0 0 ";
BA_ "GenSigSendType" SG_ 482 HCU_HC8_0x1E2 2;
BA_ "TransparentInitValue" SG_ 483 BMS_FD14_0x1E3 "0 0 0 0 0 0 0 0 ";
BA_ "GenSigSendType" SG_ 483 BMS_FD14_0x1E3 2;
BA_ "TransparentInitValue" SG_ 510 T_BOX_FD9_0x1FE "0 0 0 255 255 255 128 0 ";
BA_ "GenSigSendType" SG_ 510 T_BOX_FD9_0x1FE 2;
BA_ "TransparentInitValue" SG_ 513 HCU_HP5_0x201 "0 0 0 0 0 0 0 0 ";
BA_ "GenSigCycleTime" SG_ 513 HCU_HP5_0x201 50;
BA_ "TransparentInitValue" SG_ 515 HUT_FD2_0x203 "0 0 0 0 0 0 0 0 0 0 0 0 0 0 0 0 0 0 0 0 0 0 0 0 0 0 0 0 0 0 0 0 0 0 0 0 0 0 0 0 0 0 0 0 0 0 0 0 0 0 0 0 0 0 0 0 0 0 0 0 0 0 0 0 ";
BA_ "GenSigCycleTime" SG_ 515 HUT_FD2_0x203 50;
BA_ "TransparentInitValue" SG_ 616 HCU_HC3_0x268 "0 0 0 0 128 0 0 0 ";
BA_ "GenSigCycleTime" SG_ 616 HCU_HC3_0x268 50;
BA_ "TransparentInitValue" SG_ 645 BMS8_0x285 "0 0 0 0 0 0 0 0 ";
BA_ "GenSigCycleTime" SG_ 645 BMS8_0x285 100;
BA_ "TransparentInitValue" SG_ 690 HUT27_0x2B2 "0 0 0 0 0 0 0 0 ";
BA_ "GenSigCycleTime" SG_ 690 HUT27_0x2B2 100;
BA_ "TransparentInitValue" SG_ 708 BMS35_0x2C4 "0 0 0 0 0 6 0 0 ";
BA_ "GenSigCycleTime" SG_ 708 BMS35_0x2C4 100;
BA_ "Origin" SG_ 743 RFPosnLmpWorkCmd "ev";
BA_ "Match" SG_ 743 RFPosnLmpWorkCmd "RFPosnLmpWorkCmd";
BA_ "GenSigCycleTime" SG_ 743 RFPosnLmpWorkCmd 50;
BA_ "Origin" SG_ 743 LFPosnLmpWorkCmd "ev";
BA_ "Match" SG_ 743 LFPosnLmpWorkCmd "LFPosnLmpWorkCmd";
BA_ "GenSigCycleTime" SG_ 743 LFPosnLmpWorkCmd 50;
BA_ "Origin" SG_ 743 HiBeamWorkCmd "ev";
BA_ "Match" SG_ 743 HiBeamWorkCmd "HiBeamWorkCmd";
BA_ "GenSigCycleTime" SG_ 743 HiBeamWorkCmd 50;
BA_ "Origin" SG_ 743 LowBeamWorkCmd "ev";
BA_ "Match" SG_ 743 LowBeamWorkCmd "LowBeamWorkCmd";
BA_ "GenSigCycleTime" SG_ 743 LowBeamWorkCmd 50;
BA_ "Origin" SG_ 743 RTurnLmpWorkCmd "ev";
BA_ "Match" SG_ 743 RTurnLmpWorkCmd "RTurnLmpWorkCmd";
BA_ "GenSigCycleTime" SG_ 743 RTurnLmpWorkCmd 50;
BA_ "Origin" SG_ 743 LTurnLampWorkCmd "ev";
BA_ "Match" SG_ 743 LTurnLampWorkCmd "LTurnLampWorkCmd";
BA_ "GenSigCycleTime" SG_ 743 LTurnLampWorkCmd 50;
BA_ "Origin" SG_ 743 RDayRunngLmpWorkCmd "ev";
BA_ "Match" SG_ 743 RDayRunngLmpWorkCmd "RDayRunngLmpWorkCmd";
BA_ "GenSigCycleTime" SG_ 743 RDayRunngLmpWorkCmd 50;
BA_ "Origin" SG_ 743 LDayRunngLmpWorkCmd "ev";
BA_ "Match" SG_ 743 LDayRunngLmpWorkCmd "LDayRunngLmpWorkCmd";
BA_ "GenSigCycleTime" SG_ 743 LDayRunngLmpWorkCmd 50;
BA_ "Origin" SG_ 743 RFFogLmpWorkCmd "ev";
BA_ "Match" SG_ 743 RFFogLmpWorkCmd "RFFogLmpWorkCmd";
BA_ "GenSigCycleTime" SG_ 743 RFFogLmpWorkCmd 50;
BA_ "Origin" SG_ 743 LFFogLmpWorkCmd "ev";
BA_ "Match" SG_ 743 LFFogLmpWorkCmd "LFFogLmpWorkCmd";
BA_ "GenSigCycleTime" SG_ 743 LFFogLmpWorkCmd 50;
BA_ "Origin" SG_ 743 LicPlateLmpWorkCmd "ev";
BA_ "Match" SG_ 743 LicPlateLmpWorkCmd "LicPlateLmpWorkCmd";
BA_ "GenSigCycleTime" SG_ 743 LicPlateLmpWorkCmd 50;
BA_ "Origin" SG_ 743 ReversLampWorkCmd "ev";
BA_ "Match" SG_ 743 ReversLampWorkCmd "ReversLampWorkCmd";
BA_ "GenSigCycleTime" SG_ 743 ReversLampWorkCmd 50;
BA_ "Origin" SG_ 743 BrkLmpWorkCmd "ev";
BA_ "Match" SG_ 743 BrkLmpWorkCmd "BrkLmpWorkCmd";
BA_ "GenSigCycleTime" SG_ 743 BrkLmpWorkCmd 50;
BA_ "Origin" SG_ 743 RFogLmpWorkCmd "ev";
BA_ "Match" SG_ 743 RFogLmpWorkCmd "RFogLmpWorkCmd";
BA_ "GenSigCycleTime" SG_ 743 RFogLmpWorkCmd 50;
BA_ "Origin" SG_ 743 RRPosnLmpWorkCmd "ev";
BA_ "Match" SG_ 743 RRPosnLmpWorkCmd "RRPosnLmpWorkCmd";
BA_ "GenSigCycleTime" SG_ 743 RRPosnLmpWorkCmd 50;
BA_ "Origin" SG_ 743 LRPosnLmpWorkCmd "ev";
BA_ "Match" SG_ 743 LRPosnLmpWorkCmd "LRPosnLmpWorkCmd";
BA_ "GenSigCycleTime" SG_ 743 LRPosnLmpWorkCmd 50;
BA_ "TransparentInitValue" SG_ 788 HCU_HC6_0x314 "0 0 0 0 0 0 0 0 ";
BA_ "GenSigCycleTime" SG_ 788 HCU_HC6_0x314 200;
BA_ "TransparentInitValue" SG_ 790 OBC1_0x316 "0 0 1 0 0 0 0 0 ";
BA_ "GenSigCycleTime" SG_ 790 OBC1_0x316 200;
BA_ "TransparentInitValue" SG_ 791 OBC2_0x317 "0 0 0 0 0 0 0 0 ";
BA_ "GenSigCycleTime" SG_ 791 OBC2_0x317 200;
BA_ "Origin" SG_ 829 T_BOX_RemtLRTempSet "ev";
BA_ "Match" SG_ 829 T_BOX_RemtLRTempSet "T_BOX_RemtLRTempSet";
BA_ "GenSigSendType" SG_ 829 T_BOX_RemtLRTempSet 2;
BA_ "Origin" SG_ 829 T_BOX_RemtRRTempSet "ev";
BA_ "Match" SG_ 829 T_BOX_RemtRRTempSet "T_BOX_RemtRRTempSet";
BA_ "GenSigSendType" SG_ 829 T_BOX_RemtRRTempSet 2;
BA_ "Origin" SG_ 829 T_BOX_RemtRearAutoCtrl "ev";
BA_ "Match" SG_ 829 T_BOX_RemtRearAutoCtrl "T_BOX_RemtRearAutoCtrl";
BA_ "GenSigSendType" SG_ 829 T_BOX_RemtRearAutoCtrl 2;
BA_ "Origin" SG_ 829 T_BOX_RemtSecRowLeSeatVentnLvlSe "ev";
BA_ "Match" SG_ 829 T_BOX_RemtSecRowLeSeatVentnLvlSe "T_BOX_RemtSecRowLeSeatVentnLvlSet";
BA_ "GenSigSendType" SG_ 829 T_BOX_RemtSecRowLeSeatVentnLvlSe 2;
BA_ "SystemSignalLongSymbol" SG_ 829 T_BOX_RemtSecRowLeSeatVentnLvlSe "T_BOX_RemtSecRowLeSeatVentnLvlSet";
BA_ "Origin" SG_ 829 T_BOX_RemtSecRowRiSeatVentnLvlSe "ev";
BA_ "Match" SG_ 829 T_BOX_RemtSecRowRiSeatVentnLvlSe "T_BOX_RemtSecRowRiSeatVentnLvlSet";
BA_ "GenSigSendType" SG_ 829 T_BOX_RemtSecRowRiSeatVentnLvlSe 2;
BA_ "SystemSignalLongSymbol" SG_ 829 T_BOX_RemtSecRowRiSeatVentnLvlSe "T_BOX_RemtSecRowRiSeatVentnLvlSet";
BA_ "Origin" SG_ 829 T_BOX_MbrMonrEnReq "ev";
BA_ "Match" SG_ 829 T_BOX_MbrMonrEnReq "T_BOX_MbrMonrEnReq";
BA_ "GenSigSendType" SG_ 829 T_BOX_MbrMonrEnReq 2;
BA_ "Origin" SG_ 829 ReleAlarm_APP "ev";
BA_ "Match" SG_ 829 ReleAlarm_APP "ReleAlarm_APP";
BA_ "GenSigSendType" SG_ 829 ReleAlarm_APP 2;
BA_ "Origin" SG_ 829 T_BOX_RemtSteerWheelHeatCtrl "ev";
BA_ "Match" SG_ 829 T_BOX_RemtSteerWheelHeatCtrl "T_BOX_RemtSteerWheelHeatCtrl";
BA_ "GenSigSendType" SG_ 829 T_BOX_RemtSteerWheelHeatCtrl 2;
BA_ "Origin" SG_ 829 T_BOX_AVPActvReq "ev";
BA_ "Match" SG_ 829 T_BOX_AVPActvReq "T_BOX_AVPActvReq";
BA_ "GenSigSendType" SG_ 829 T_BOX_AVPActvReq 2;
BA_ "TransparentInitValue" SG_ 850 BMS19_0x352 "0 0 0 0 0 0 0 0 ";
BA_ "GenSigCycleTime" SG_ 850 BMS19_0x352 500;
BA_ "Origin" SG_ 865 HCU_HVILSts "ev";
BA_ "Match" SG_ 865 HCU_HVILSts "HCU_HVILSts";
BA_ "GenSigCycleTime" SG_ 865 HCU_HVILSts 500;
BA_ "Origin" SG_ 865 HCU_BMSSleepCmd "ev";
BA_ "Match" SG_ 865 HCU_BMSSleepCmd "HCU_BMSSleepCmd";
BA_ "GenSigCycleTime" SG_ 865 HCU_BMSSleepCmd 500;
BA_ "Origin" SG_ 865 HCU_P2MActHvDcCurr_RM "ev";
BA_ "Match" SG_ 865 HCU_P2MActHvDcCurr_RM "HCU_P2MActHvDcCurr_RM";
BA_ "GenSigCycleTime" SG_ 865 HCU_P2MActHvDcCurr_RM 500;
BA_ "Origin" SG_ 865 HCU_P2MActHvDcVolt_RM "ev";
BA_ "Match" SG_ 865 HCU_P2MActHvDcVolt_RM "HCU_P2MActHvDcVolt_RM";
BA_ "GenSigCycleTime" SG_ 865 HCU_P2MActHvDcVolt_RM 500;
BA_ "Origin" SG_ 865 HCU_DTCNumber1 "ev";
BA_ "Match" SG_ 865 HCU_DTCNumber1 "HCU_DTCNumber1";
BA_ "GenSigCycleTime" SG_ 865 HCU_DTCNumber1 500;
BA_ "Origin" SG_ 865 HCU_DTCNumber2 "ev";
BA_ "Match" SG_ 865 HCU_DTCNumber2 "HCU_DTCNumber2";
BA_ "GenSigCycleTime" SG_ 865 HCU_DTCNumber2 500;
BA_ "Origin" SG_ 865 HCU_MotorAmount_RM "ev";
BA_ "Match" SG_ 865 HCU_MotorAmount_RM "HCU_MotorAmount_RM";
BA_ "GenSigCycleTime" SG_ 865 HCU_MotorAmount_RM 500;
BA_ "Origin" SG_ 909 HCU_PowertrainSts_RM "ev";
BA_ "Match" SG_ 909 HCU_PowertrainSts_RM "HCU_PowertrainSts_RM";
BA_ "GenSigCycleTime" SG_ 909 HCU_PowertrainSts_RM 1000;
BA_ "Origin" SG_ 909 HCU_BrkPowflag_RM "ev";
BA_ "Match" SG_ 909 HCU_BrkPowflag_RM "HCU_BrkPowflag_RM";
BA_ "GenSigCycleTime" SG_ 909 HCU_BrkPowflag_RM 1000;
BA_ "Origin" SG_ 909 HCU_ChargSts_RM "ev";
BA_ "Match" SG_ 909 HCU_ChargSts_RM "HCU_ChargSts_RM";
BA_ "GenSigStartValue" SG_ 909 HCU_ChargSts_RM 3;
BA_ "GenSigCycleTime" SG_ 909 HCU_ChargSts_RM 1000;
BA_ "Origin" SG_ 909 HCU_PTDrvMod_RM "ev";
BA_ "Match" SG_ 909 HCU_PTDrvMod_RM "HCU_PTDrvMod_RM";
BA_ "GenSigCycleTime" SG_ 909 HCU_PTDrvMod_RM 1000;
BA_ "Origin" SG_ 909 HCU_Powerflag_RM "ev";
BA_ "Match" SG_ 909 HCU_Powerflag_RM "HCU_Powerflag_RM";
BA_ "GenSigCycleTime" SG_ 909 HCU_Powerflag_RM 1000;
BA_ "Origin" SG_ 909 HCU_AccelPedalPosn_Diag_RM "ev";
BA_ "Match" SG_ 909 HCU_AccelPedalPosn_Diag_RM "HCU_AccelPedalPosn_Diag_RM";
BA_ "GenSigCycleTime" SG_ 909 HCU_AccelPedalPosn_Diag_RM 1000;
BA_ "Origin" SG_ 909 HCU_BrkPedalSts_RM "ev";
BA_ "Match" SG_ 909 HCU_BrkPedalSts_RM "HCU_BrkPedalSts_RM";
BA_ "GenSigCycleTime" SG_ 909 HCU_BrkPedalSts_RM 1000;
BA_ "Origin" SG_ 909 HCU_WakeUpSrc "ev";
BA_ "Match" SG_ 909 HCU_WakeUpSrc "HCU_WakeUpSrc";
BA_ "GenSigCycleTime" SG_ 909 HCU_WakeUpSrc 1000;
BA_ "Origin" SG_ 909 HCU_CurrHybSysSts "ev";
BA_ "Match" SG_ 909 HCU_CurrHybSysSts "HCU_CurrHybSysSts";
BA_ "GenSigCycleTime" SG_ 909 HCU_CurrHybSysSts 1000;
BA_ "Origin" SG_ 937 BMS_ISC_ROhm_Warn "ev";
BA_ "Match" SG_ 937 BMS_ISC_ROhm_Warn "BMS_ISC_ROhm_Warn";
BA_ "GenSigCycleTime" SG_ 937 BMS_ISC_ROhm_Warn 1000;
BA_ "Origin" SG_ 937 BMS_ISC_SOC_Warn "ev";
BA_ "Match" SG_ 937 BMS_ISC_SOC_Warn "BMS_ISC_SOC_Warn";
BA_ "GenSigCycleTime" SG_ 937 BMS_ISC_SOC_Warn 1000;
BA_ "Origin" SG_ 937 BMS_ISC_T_Warn "ev";
BA_ "Match" SG_ 937 BMS_ISC_T_Warn "BMS_ISC_T_Warn";
BA_ "GenSigCycleTime" SG_ 937 BMS_ISC_T_Warn 1000;
BA_ "Origin" SG_ 937 BMS_ISC_V_Warn "ev";
BA_ "Match" SG_ 937 BMS_ISC_V_Warn "BMS_ISC_V_Warn";
BA_ "GenSigCycleTime" SG_ 937 BMS_ISC_V_Warn 1000;
BA_ "TransparentInitValue" SG_ 942 BMS66_0x3AE "8 39 16 0 0 0 0 0 ";
BA_ "GenSigCycleTime" SG_ 942 BMS66_0x3AE 1000;
BA_ "Origin" SG_ 957 DCDC_Tempwarning_RM "ev";
BA_ "Match" SG_ 957 DCDC_Tempwarning_RM "DCDC_Tempwarning_RM";
BA_ "GenSigCycleTime" SG_ 957 DCDC_Tempwarning_RM 1000;
BA_ "Origin" SG_ 957 DCDC_ActSts_RM "ev";
BA_ "Match" SG_ 957 DCDC_ActSts_RM "DCDC_ActSts_RM";
BA_ "GenSigCycleTime" SG_ 957 DCDC_ActSts_RM 1000;
BA_ "Origin" SG_ 957 DCDC_FailStswarning_RM "ev";
BA_ "Match" SG_ 957 DCDC_FailStswarning_RM "DCDC_FailStswarning_RM";
BA_ "GenSigCycleTime" SG_ 957 DCDC_FailStswarning_RM 1000;
BA_ "TransparentInitValue" SG_ 959 BMS22_0x3BF "0 0 0 0 0 0 0 0 ";
BA_ "GenSigCycleTime" SG_ 959 BMS22_0x3BF 1000;
BA_ "Origin" SG_ 963 P2M_MotorSerNumber_RM "ev";
BA_ "Match" SG_ 963 P2M_MotorSerNumber_RM "P2M_MotorSerNumber_RM";
BA_ "GenSigCycleTime" SG_ 963 P2M_MotorSerNumber_RM 1000;
BA_ "Origin" SG_ 963 P2M_InvActTemp_RM "ev";
BA_ "Match" SG_ 963 P2M_InvActTemp_RM "P2M_InvActTemp_RM";
BA_ "GenSigStartValue" SG_ 963 P2M_InvActTemp_RM 65;
BA_ "GenSigCycleTime" SG_ 963 P2M_InvActTemp_RM 1000;
BA_ "Origin" SG_ 963 P2M_ActSpd_RM "ev";
BA_ "Match" SG_ 963 P2M_ActSpd_RM "P2M_ActSpd_RM";
BA_ "GenSigStartValue" SG_ 963 P2M_ActSpd_RM 20000;
BA_ "GenSigCycleTime" SG_ 963 P2M_ActSpd_RM 1000;
BA_ "Origin" SG_ 963 P2M_ActTrq_RM "ev";
BA_ "Match" SG_ 963 P2M_ActTrq_RM "P2M_ActTrq_RM";
BA_ "GenSigStartValue" SG_ 963 P2M_ActTrq_RM 20000;
BA_ "GenSigCycleTime" SG_ 963 P2M_ActTrq_RM 1000;
BA_ "Origin" SG_ 967 P2M_ActTemp_RM "ev";
BA_ "Match" SG_ 967 P2M_ActTemp_RM "P2M_ActTemp_RM";
BA_ "GenSigStartValue" SG_ 967 P2M_ActTemp_RM 65;
BA_ "GenSigCycleTime" SG_ 967 P2M_ActTemp_RM 1000;
BA_ "Origin" SG_ 967 P2M_OperMode_RM "ev";
BA_ "Match" SG_ 967 P2M_OperMode_RM "P2M_OperMode_RM";
BA_ "GenSigStartValue" SG_ 967 P2M_OperMode_RM 4;
BA_ "GenSigCycleTime" SG_ 967 P2M_OperMode_RM 1000;
BA_ "Origin" SG_ 967 P2M_InvTempwarning_RM "ev";
BA_ "Match" SG_ 967 P2M_InvTempwarning_RM "P2M_InvTempwarning_RM";
BA_ "GenSigCycleTime" SG_ 967 P2M_InvTempwarning_RM 1000;
BA_ "Origin" SG_ 967 P2M_Tempwarning_RM "ev";
BA_ "Match" SG_ 967 P2M_Tempwarning_RM "P2M_Tempwarning_RM";
BA_ "GenSigCycleTime" SG_ 967 P2M_Tempwarning_RM 1000;
BA_ "Origin" SG_ 976 BMS_BattTempMax "ev";
BA_ "Match" SG_ 976 BMS_BattTempMax "BMS_BattTempMax";
BA_ "GenSigStartValue" SG_ 976 BMS_BattTempMax 65;
BA_ "GenSigCycleTime" SG_ 976 BMS_BattTempMax 1000;
BA_ "Origin" SG_ 976 BMS_BattTempMin "ev";
BA_ "Match" SG_ 976 BMS_BattTempMin "BMS_BattTempMin";
BA_ "GenSigStartValue" SG_ 976 BMS_BattTempMin 65;
BA_ "GenSigCycleTime" SG_ 976 BMS_BattTempMin 1000;
BA_ "Origin" SG_ 977 BMS_SingleCellVolt_1 "ev";
BA_ "Match" SG_ 977 BMS_SingleCellVolt_1 "BMS_SingleCellVolt_1";
BA_ "GenSigCycleTime" SG_ 977 BMS_SingleCellVolt_1 1000;
BA_ "Origin" SG_ 977 BMS_SingleCellVolt_2 "ev";
BA_ "Match" SG_ 977 BMS_SingleCellVolt_2 "BMS_SingleCellVolt_2";
BA_ "GenSigCycleTime" SG_ 977 BMS_SingleCellVolt_2 1000;
BA_ "Origin" SG_ 977 BMS_SingleCellVolt_3 "ev";
BA_ "Match" SG_ 977 BMS_SingleCellVolt_3 "BMS_SingleCellVolt_3";
BA_ "GenSigCycleTime" SG_ 977 BMS_SingleCellVolt_3 1000;
BA_ "Origin" SG_ 977 BMS_SingleCellVolt_4 "ev";
BA_ "Match" SG_ 977 BMS_SingleCellVolt_4 "BMS_SingleCellVolt_4";
BA_ "GenSigCycleTime" SG_ 977 BMS_SingleCellVolt_4 1000;
BA_ "Origin" SG_ 977 BMS_SingleCellVolt_5 "ev";
BA_ "Match" SG_ 977 BMS_SingleCellVolt_5 "BMS_SingleCellVolt_5";
BA_ "GenSigCycleTime" SG_ 977 BMS_SingleCellVolt_5 1000;
BA_ "Origin" SG_ 977 BMS_SingleCellVolt_6 "ev";
BA_ "Match" SG_ 977 BMS_SingleCellVolt_6 "BMS_SingleCellVolt_6";
BA_ "GenSigCycleTime" SG_ 977 BMS_SingleCellVolt_6 1000;
BA_ "Origin" SG_ 977 BMS_SingleCellVolt_7 "ev";
BA_ "Match" SG_ 977 BMS_SingleCellVolt_7 "BMS_SingleCellVolt_7";
BA_ "GenSigCycleTime" SG_ 977 BMS_SingleCellVolt_7 1000;
BA_ "Origin" SG_ 977 BMS_SingleCellVolt_8 "ev";
BA_ "Match" SG_ 977 BMS_SingleCellVolt_8 "BMS_SingleCellVolt_8";
BA_ "GenSigCycleTime" SG_ 977 BMS_SingleCellVolt_8 1000;
BA_ "Origin" SG_ 977 BMS_SingleCellVolt_9 "ev";
BA_ "Match" SG_ 977 BMS_SingleCellVolt_9 "BMS_SingleCellVolt_9";
BA_ "GenSigCycleTime" SG_ 977 BMS_SingleCellVolt_9 1000;
BA_ "Origin" SG_ 977 BMS_SingleCellVolt_10 "ev";
BA_ "Match" SG_ 977 BMS_SingleCellVolt_10 "BMS_SingleCellVolt_10";
BA_ "GenSigCycleTime" SG_ 977 BMS_SingleCellVolt_10 1000;
BA_ "Origin" SG_ 977 BMS_SingleCellVolt_11 "ev";
BA_ "Match" SG_ 977 BMS_SingleCellVolt_11 "BMS_SingleCellVolt_11";
BA_ "GenSigCycleTime" SG_ 977 BMS_SingleCellVolt_11 1000;
BA_ "Origin" SG_ 977 BMS_SingleCellVolt_12 "ev";
BA_ "Match" SG_ 977 BMS_SingleCellVolt_12 "BMS_SingleCellVolt_12";
BA_ "GenSigCycleTime" SG_ 977 BMS_SingleCellVolt_12 1000;
BA_ "Origin" SG_ 977 BMS_BattModuleTe_11 "ev";
BA_ "Match" SG_ 977 BMS_BattModuleTe_11 "BMS_BattModuleTe_11";
BA_ "GenSigStartValue" SG_ 977 BMS_BattModuleTe_11 65;
BA_ "GenSigCycleTime" SG_ 977 BMS_BattModuleTe_11 1000;
BA_ "Origin" SG_ 977 BMS_BattModuleTe_12 "ev";
BA_ "Match" SG_ 977 BMS_BattModuleTe_12 "BMS_BattModuleTe_12";
BA_ "GenSigStartValue" SG_ 977 BMS_BattModuleTe_12 65;
BA_ "GenSigCycleTime" SG_ 977 BMS_BattModuleTe_12 1000;
BA_ "Origin" SG_ 977 BMS_BattModuleTe_21 "ev";
BA_ "Match" SG_ 977 BMS_BattModuleTe_21 "BMS_BattModuleTe_21";
BA_ "GenSigStartValue" SG_ 977 BMS_BattModuleTe_21 65;
BA_ "GenSigCycleTime" SG_ 977 BMS_BattModuleTe_21 1000;
BA_ "Origin" SG_ 977 BMS_BattModuleTe_22 "ev";
BA_ "Match" SG_ 977 BMS_BattModuleTe_22 "BMS_BattModuleTe_22";
BA_ "GenSigStartValue" SG_ 977 BMS_BattModuleTe_22 65;
BA_ "GenSigCycleTime" SG_ 977 BMS_BattModuleTe_22 1000;
BA_ "Origin" SG_ 977 BMS_BattModuleTe_31 "ev";
BA_ "Match" SG_ 977 BMS_BattModuleTe_31 "BMS_BattModuleTe_31";
BA_ "GenSigStartValue" SG_ 977 BMS_BattModuleTe_31 65;
BA_ "GenSigCycleTime" SG_ 977 BMS_BattModuleTe_31 1000;
BA_ "Origin" SG_ 977 BMS_BattModuleTe_32 "ev";
BA_ "Match" SG_ 977 BMS_BattModuleTe_32 "BMS_BattModuleTe_32";
BA_ "GenSigStartValue" SG_ 977 BMS_BattModuleTe_32 65;
BA_ "GenSigCycleTime" SG_ 977 BMS_BattModuleTe_32 1000;
BA_ "Origin" SG_ 977 BMS_BattModuleTe_41 "ev";
BA_ "Match" SG_ 977 BMS_BattModuleTe_41 "BMS_BattModuleTe_41";
BA_ "GenSigStartValue" SG_ 977 BMS_BattModuleTe_41 65;
BA_ "GenSigCycleTime" SG_ 977 BMS_BattModuleTe_41 1000;
BA_ "Origin" SG_ 977 BMS_BattModuleTe_42 "ev";
BA_ "Match" SG_ 977 BMS_BattModuleTe_42 "BMS_BattModuleTe_42";
BA_ "GenSigStartValue" SG_ 977 BMS_BattModuleTe_42 65;
BA_ "GenSigCycleTime" SG_ 977 BMS_BattModuleTe_42 1000;
BA_ "Origin" SG_ 977 BMS_BattModuleTe_51 "ev";
BA_ "Match" SG_ 977 BMS_BattModuleTe_51 "BMS_BattModuleTe_51";
BA_ "GenSigStartValue" SG_ 977 BMS_BattModuleTe_51 65;
BA_ "GenSigCycleTime" SG_ 977 BMS_BattModuleTe_51 1000;
BA_ "Origin" SG_ 977 BMS_BattModuleTe_52 "ev";
BA_ "Match" SG_ 977 BMS_BattModuleTe_52 "BMS_BattModuleTe_52";
BA_ "GenSigStartValue" SG_ 977 BMS_BattModuleTe_52 65;
BA_ "GenSigCycleTime" SG_ 977 BMS_BattModuleTe_52 1000;
BA_ "Origin" SG_ 977 BMS_BattModuleTe_61 "ev";
BA_ "Match" SG_ 977 BMS_BattModuleTe_61 "BMS_BattModuleTe_61";
BA_ "GenSigStartValue" SG_ 977 BMS_BattModuleTe_61 65;
BA_ "GenSigCycleTime" SG_ 977 BMS_BattModuleTe_61 1000;
BA_ "Origin" SG_ 977 BMS_BattModuleTe_62 "ev";
BA_ "Match" SG_ 977 BMS_BattModuleTe_62 "BMS_BattModuleTe_62";
BA_ "GenSigStartValue" SG_ 977 BMS_BattModuleTe_62 65;
BA_ "GenSigCycleTime" SG_ 977 BMS_BattModuleTe_62 1000;
BA_ "Origin" SG_ 977 BMS_BattModuleTe_71 "ev";
BA_ "Match" SG_ 977 BMS_BattModuleTe_71 "BMS_BattModuleTe_71";
BA_ "GenSigStartValue" SG_ 977 BMS_BattModuleTe_71 65;
BA_ "GenSigCycleTime" SG_ 977 BMS_BattModuleTe_71 1000;
BA_ "Origin" SG_ 977 BMS_BattModuleTe_72 "ev";
BA_ "Match" SG_ 977 BMS_BattModuleTe_72 "BMS_BattModuleTe_72";
BA_ "GenSigStartValue" SG_ 977 BMS_BattModuleTe_72 65;
BA_ "GenSigCycleTime" SG_ 977 BMS_BattModuleTe_72 1000;
BA_ "Origin" SG_ 977 BMS_BattModuleTe_81 "ev";
BA_ "Match" SG_ 977 BMS_BattModuleTe_81 "BMS_BattModuleTe_81";
BA_ "GenSigStartValue" SG_ 977 BMS_BattModuleTe_81 65;
BA_ "GenSigCycleTime" SG_ 977 BMS_BattModuleTe_81 1000;
BA_ "Origin" SG_ 977 BMS_BattModuleTe_82 "ev";
BA_ "Match" SG_ 977 BMS_BattModuleTe_82 "BMS_BattModuleTe_82";
BA_ "GenSigStartValue" SG_ 977 BMS_BattModuleTe_82 65;
BA_ "GenSigCycleTime" SG_ 977 BMS_BattModuleTe_82 1000;
BA_ "Origin" SG_ 978 BMS_SingleCellVolt_13 "ev";
BA_ "Match" SG_ 978 BMS_SingleCellVolt_13 "BMS_SingleCellVolt_13";
BA_ "GenSigCycleTime" SG_ 978 BMS_SingleCellVolt_13 1000;
BA_ "Origin" SG_ 978 BMS_SingleCellVolt_14 "ev";
BA_ "Match" SG_ 978 BMS_SingleCellVolt_14 "BMS_SingleCellVolt_14";
BA_ "GenSigCycleTime" SG_ 978 BMS_SingleCellVolt_14 1000;
BA_ "Origin" SG_ 978 BMS_SingleCellVolt_15 "ev";
BA_ "Match" SG_ 978 BMS_SingleCellVolt_15 "BMS_SingleCellVolt_15";
BA_ "GenSigCycleTime" SG_ 978 BMS_SingleCellVolt_15 1000;
BA_ "Origin" SG_ 978 BMS_SingleCellVolt_16 "ev";
BA_ "Match" SG_ 978 BMS_SingleCellVolt_16 "BMS_SingleCellVolt_16";
BA_ "GenSigCycleTime" SG_ 978 BMS_SingleCellVolt_16 1000;
BA_ "Origin" SG_ 978 BMS_SingleCellVolt_17 "ev";
BA_ "Match" SG_ 978 BMS_SingleCellVolt_17 "BMS_SingleCellVolt_17";
BA_ "GenSigCycleTime" SG_ 978 BMS_SingleCellVolt_17 1000;
BA_ "Origin" SG_ 978 BMS_SingleCellVolt_18 "ev";
BA_ "Match" SG_ 978 BMS_SingleCellVolt_18 "BMS_SingleCellVolt_18";
BA_ "GenSigCycleTime" SG_ 978 BMS_SingleCellVolt_18 1000;
BA_ "Origin" SG_ 978 BMS_SingleCellVolt_19 "ev";
BA_ "Match" SG_ 978 BMS_SingleCellVolt_19 "BMS_SingleCellVolt_19";
BA_ "GenSigCycleTime" SG_ 978 BMS_SingleCellVolt_19 1000;
BA_ "Origin" SG_ 978 BMS_SingleCellVolt_20 "ev";
BA_ "Match" SG_ 978 BMS_SingleCellVolt_20 "BMS_SingleCellVolt_20";
BA_ "GenSigCycleTime" SG_ 978 BMS_SingleCellVolt_20 1000;
BA_ "Origin" SG_ 978 BMS_SingleCellVolt_21 "ev";
BA_ "Match" SG_ 978 BMS_SingleCellVolt_21 "BMS_SingleCellVolt_21";
BA_ "GenSigCycleTime" SG_ 978 BMS_SingleCellVolt_21 1000;
BA_ "Origin" SG_ 978 BMS_SingleCellVolt_22 "ev";
BA_ "Match" SG_ 978 BMS_SingleCellVolt_22 "BMS_SingleCellVolt_22";
BA_ "GenSigCycleTime" SG_ 978 BMS_SingleCellVolt_22 1000;
BA_ "Origin" SG_ 978 BMS_SingleCellVolt_23 "ev";
BA_ "Match" SG_ 978 BMS_SingleCellVolt_23 "BMS_SingleCellVolt_23";
BA_ "GenSigCycleTime" SG_ 978 BMS_SingleCellVolt_23 1000;
BA_ "Origin" SG_ 978 BMS_SingleCellVolt_24 "ev";
BA_ "Match" SG_ 978 BMS_SingleCellVolt_24 "BMS_SingleCellVolt_24";
BA_ "GenSigCycleTime" SG_ 978 BMS_SingleCellVolt_24 1000;
BA_ "Origin" SG_ 978 BMS_SingleCellVolt_25 "ev";
BA_ "Match" SG_ 978 BMS_SingleCellVolt_25 "BMS_SingleCellVolt_25";
BA_ "GenSigCycleTime" SG_ 978 BMS_SingleCellVolt_25 1000;
BA_ "Origin" SG_ 978 BMS_SingleCellVolt_26 "ev";
BA_ "Match" SG_ 978 BMS_SingleCellVolt_26 "BMS_SingleCellVolt_26";
BA_ "GenSigCycleTime" SG_ 978 BMS_SingleCellVolt_26 1000;
BA_ "Origin" SG_ 978 BMS_SingleCellVolt_27 "ev";
BA_ "Match" SG_ 978 BMS_SingleCellVolt_27 "BMS_SingleCellVolt_27";
BA_ "GenSigCycleTime" SG_ 978 BMS_SingleCellVolt_27 1000;
BA_ "Origin" SG_ 978 BMS_SingleCellVolt_28 "ev";
BA_ "Match" SG_ 978 BMS_SingleCellVolt_28 "BMS_SingleCellVolt_28";
BA_ "GenSigCycleTime" SG_ 978 BMS_SingleCellVolt_28 1000;
BA_ "Origin" SG_ 978 BMS_SingleCellVolt_29 "ev";
BA_ "Match" SG_ 978 BMS_SingleCellVolt_29 "BMS_SingleCellVolt_29";
BA_ "GenSigCycleTime" SG_ 978 BMS_SingleCellVolt_29 1000;
BA_ "Origin" SG_ 978 BMS_SingleCellVolt_30 "ev";
BA_ "Match" SG_ 978 BMS_SingleCellVolt_30 "BMS_SingleCellVolt_30";
BA_ "GenSigCycleTime" SG_ 978 BMS_SingleCellVolt_30 1000;
BA_ "Origin" SG_ 978 BMS_SingleCellVolt_31 "ev";
BA_ "Match" SG_ 978 BMS_SingleCellVolt_31 "BMS_SingleCellVolt_31";
BA_ "GenSigCycleTime" SG_ 978 BMS_SingleCellVolt_31 1000;
BA_ "Origin" SG_ 978 BMS_SingleCellVolt_32 "ev";
BA_ "Match" SG_ 978 BMS_SingleCellVolt_32 "BMS_SingleCellVolt_32";
BA_ "GenSigCycleTime" SG_ 978 BMS_SingleCellVolt_32 1000;
BA_ "Origin" SG_ 978 BMS_SingleCellVolt_33 "ev";
BA_ "Match" SG_ 978 BMS_SingleCellVolt_33 "BMS_SingleCellVolt_33";
BA_ "GenSigCycleTime" SG_ 978 BMS_SingleCellVolt_33 1000;
BA_ "Origin" SG_ 978 BMS_SingleCellVolt_34 "ev";
BA_ "Match" SG_ 978 BMS_SingleCellVolt_34 "BMS_SingleCellVolt_34";
BA_ "GenSigCycleTime" SG_ 978 BMS_SingleCellVolt_34 1000;
BA_ "Origin" SG_ 978 BMS_SingleCellVolt_35 "ev";
BA_ "Match" SG_ 978 BMS_SingleCellVolt_35 "BMS_SingleCellVolt_35";
BA_ "GenSigCycleTime" SG_ 978 BMS_SingleCellVolt_35 1000;
BA_ "Origin" SG_ 978 BMS_SingleCellVolt_36 "ev";
BA_ "Match" SG_ 978 BMS_SingleCellVolt_36 "BMS_SingleCellVolt_36";
BA_ "GenSigCycleTime" SG_ 978 BMS_SingleCellVolt_36 1000;
BA_ "Origin" SG_ 978 BMS_SingleCellVolt_37 "ev";
BA_ "Match" SG_ 978 BMS_SingleCellVolt_37 "BMS_SingleCellVolt_37";
BA_ "GenSigCycleTime" SG_ 978 BMS_SingleCellVolt_37 1000;
BA_ "Origin" SG_ 978 BMS_SingleCellVolt_38 "ev";
BA_ "Match" SG_ 978 BMS_SingleCellVolt_38 "BMS_SingleCellVolt_38";
BA_ "GenSigCycleTime" SG_ 978 BMS_SingleCellVolt_38 1000;
BA_ "Origin" SG_ 978 BMS_SingleCellVolt_39 "ev";
BA_ "Match" SG_ 978 BMS_SingleCellVolt_39 "BMS_SingleCellVolt_39";
BA_ "GenSigCycleTime" SG_ 978 BMS_SingleCellVolt_39 1000;
BA_ "Origin" SG_ 978 BMS_SingleCellVolt_40 "ev";
BA_ "Match" SG_ 978 BMS_SingleCellVolt_40 "BMS_SingleCellVolt_40";
BA_ "GenSigCycleTime" SG_ 978 BMS_SingleCellVolt_40 1000;
BA_ "Origin" SG_ 979 BMS_SingleCellVolt_41 "ev";
BA_ "Match" SG_ 979 BMS_SingleCellVolt_41 "BMS_SingleCellVolt_41";
BA_ "GenSigCycleTime" SG_ 979 BMS_SingleCellVolt_41 1000;
BA_ "Origin" SG_ 979 BMS_SingleCellVolt_42 "ev";
BA_ "Match" SG_ 979 BMS_SingleCellVolt_42 "BMS_SingleCellVolt_42";
BA_ "GenSigCycleTime" SG_ 979 BMS_SingleCellVolt_42 1000;
BA_ "Origin" SG_ 979 BMS_SingleCellVolt_43 "ev";
BA_ "Match" SG_ 979 BMS_SingleCellVolt_43 "BMS_SingleCellVolt_43";
BA_ "GenSigCycleTime" SG_ 979 BMS_SingleCellVolt_43 1000;
BA_ "Origin" SG_ 979 BMS_SingleCellVolt_44 "ev";
BA_ "Match" SG_ 979 BMS_SingleCellVolt_44 "BMS_SingleCellVolt_44";
BA_ "GenSigCycleTime" SG_ 979 BMS_SingleCellVolt_44 1000;
BA_ "Origin" SG_ 979 BMS_SingleCellVolt_45 "ev";
BA_ "Match" SG_ 979 BMS_SingleCellVolt_45 "BMS_SingleCellVolt_45";
BA_ "GenSigCycleTime" SG_ 979 BMS_SingleCellVolt_45 1000;
BA_ "Origin" SG_ 979 BMS_SingleCellVolt_46 "ev";
BA_ "Match" SG_ 979 BMS_SingleCellVolt_46 "BMS_SingleCellVolt_46";
BA_ "GenSigCycleTime" SG_ 979 BMS_SingleCellVolt_46 1000;
BA_ "Origin" SG_ 979 BMS_SingleCellVolt_47 "ev";
BA_ "Match" SG_ 979 BMS_SingleCellVolt_47 "BMS_SingleCellVolt_47";
BA_ "GenSigCycleTime" SG_ 979 BMS_SingleCellVolt_47 1000;
BA_ "Origin" SG_ 979 BMS_SingleCellVolt_48 "ev";
BA_ "Match" SG_ 979 BMS_SingleCellVolt_48 "BMS_SingleCellVolt_48";
BA_ "GenSigCycleTime" SG_ 979 BMS_SingleCellVolt_48 1000;
BA_ "Origin" SG_ 979 BMS_SingleCellVolt_49 "ev";
BA_ "Match" SG_ 979 BMS_SingleCellVolt_49 "BMS_SingleCellVolt_49";
BA_ "GenSigCycleTime" SG_ 979 BMS_SingleCellVolt_49 1000;
BA_ "Origin" SG_ 979 BMS_SingleCellVolt_50 "ev";
BA_ "Match" SG_ 979 BMS_SingleCellVolt_50 "BMS_SingleCellVolt_50";
BA_ "GenSigCycleTime" SG_ 979 BMS_SingleCellVolt_50 1000;
BA_ "Origin" SG_ 979 BMS_SingleCellVolt_51 "ev";
BA_ "Match" SG_ 979 BMS_SingleCellVolt_51 "BMS_SingleCellVolt_51";
BA_ "GenSigCycleTime" SG_ 979 BMS_SingleCellVolt_51 1000;
BA_ "Origin" SG_ 979 BMS_SingleCellVolt_52 "ev";
BA_ "Match" SG_ 979 BMS_SingleCellVolt_52 "BMS_SingleCellVolt_52";
BA_ "GenSigCycleTime" SG_ 979 BMS_SingleCellVolt_52 1000;
BA_ "Origin" SG_ 979 BMS_SingleCellVolt_53 "ev";
BA_ "Match" SG_ 979 BMS_SingleCellVolt_53 "BMS_SingleCellVolt_53";
BA_ "GenSigCycleTime" SG_ 979 BMS_SingleCellVolt_53 1000;
BA_ "Origin" SG_ 979 BMS_SingleCellVolt_54 "ev";
BA_ "Match" SG_ 979 BMS_SingleCellVolt_54 "BMS_SingleCellVolt_54";
BA_ "GenSigCycleTime" SG_ 979 BMS_SingleCellVolt_54 1000;
BA_ "Origin" SG_ 979 BMS_SingleCellVolt_55 "ev";
BA_ "Match" SG_ 979 BMS_SingleCellVolt_55 "BMS_SingleCellVolt_55";
BA_ "GenSigCycleTime" SG_ 979 BMS_SingleCellVolt_55 1000;
BA_ "Origin" SG_ 979 BMS_SingleCellVolt_56 "ev";
BA_ "Match" SG_ 979 BMS_SingleCellVolt_56 "BMS_SingleCellVolt_56";
BA_ "GenSigCycleTime" SG_ 979 BMS_SingleCellVolt_56 1000;
BA_ "Origin" SG_ 979 BMS_SingleCellVolt_57 "ev";
BA_ "Match" SG_ 979 BMS_SingleCellVolt_57 "BMS_SingleCellVolt_57";
BA_ "GenSigCycleTime" SG_ 979 BMS_SingleCellVolt_57 1000;
BA_ "Origin" SG_ 979 BMS_SingleCellVolt_58 "ev";
BA_ "Match" SG_ 979 BMS_SingleCellVolt_58 "BMS_SingleCellVolt_58";
BA_ "GenSigCycleTime" SG_ 979 BMS_SingleCellVolt_58 1000;
BA_ "Origin" SG_ 979 BMS_SingleCellVolt_59 "ev";
BA_ "Match" SG_ 979 BMS_SingleCellVolt_59 "BMS_SingleCellVolt_59";
BA_ "GenSigCycleTime" SG_ 979 BMS_SingleCellVolt_59 1000;
BA_ "Origin" SG_ 979 BMS_SingleCellVolt_60 "ev";
BA_ "Match" SG_ 979 BMS_SingleCellVolt_60 "BMS_SingleCellVolt_60";
BA_ "GenSigCycleTime" SG_ 979 BMS_SingleCellVolt_60 1000;
BA_ "Origin" SG_ 979 BMS_SingleCellVolt_61 "ev";
BA_ "Match" SG_ 979 BMS_SingleCellVolt_61 "BMS_SingleCellVolt_61";
BA_ "GenSigCycleTime" SG_ 979 BMS_SingleCellVolt_61 1000;
BA_ "Origin" SG_ 979 BMS_SingleCellVolt_62 "ev";
BA_ "Match" SG_ 979 BMS_SingleCellVolt_62 "BMS_SingleCellVolt_62";
BA_ "GenSigCycleTime" SG_ 979 BMS_SingleCellVolt_62 1000;
BA_ "Origin" SG_ 979 BMS_SingleCellVolt_63 "ev";
BA_ "Match" SG_ 979 BMS_SingleCellVolt_63 "BMS_SingleCellVolt_63";
BA_ "GenSigCycleTime" SG_ 979 BMS_SingleCellVolt_63 1000;
BA_ "Origin" SG_ 979 BMS_SingleCellVolt_64 "ev";
BA_ "Match" SG_ 979 BMS_SingleCellVolt_64 "BMS_SingleCellVolt_64";
BA_ "GenSigCycleTime" SG_ 979 BMS_SingleCellVolt_64 1000;
BA_ "Origin" SG_ 979 BMS_SingleCellVolt_65 "ev";
BA_ "Match" SG_ 979 BMS_SingleCellVolt_65 "BMS_SingleCellVolt_65";
BA_ "GenSigCycleTime" SG_ 979 BMS_SingleCellVolt_65 1000;
BA_ "Origin" SG_ 979 BMS_SingleCellVolt_66 "ev";
BA_ "Match" SG_ 979 BMS_SingleCellVolt_66 "BMS_SingleCellVolt_66";
BA_ "GenSigCycleTime" SG_ 979 BMS_SingleCellVolt_66 1000;
BA_ "Origin" SG_ 979 BMS_SingleCellVolt_67 "ev";
BA_ "Match" SG_ 979 BMS_SingleCellVolt_67 "BMS_SingleCellVolt_67";
BA_ "GenSigCycleTime" SG_ 979 BMS_SingleCellVolt_67 1000;
BA_ "Origin" SG_ 979 BMS_SingleCellVolt_68 "ev";
BA_ "Match" SG_ 979 BMS_SingleCellVolt_68 "BMS_SingleCellVolt_68";
BA_ "GenSigCycleTime" SG_ 979 BMS_SingleCellVolt_68 1000;
BA_ "Origin" SG_ 980 BMS_SingleCellVolt_69 "ev";
BA_ "Match" SG_ 980 BMS_SingleCellVolt_69 "BMS_SingleCellVolt_69";
BA_ "GenSigCycleTime" SG_ 980 BMS_SingleCellVolt_69 1000;
BA_ "Origin" SG_ 980 BMS_SingleCellVolt_70 "ev";
BA_ "Match" SG_ 980 BMS_SingleCellVolt_70 "BMS_SingleCellVolt_70";
BA_ "GenSigCycleTime" SG_ 980 BMS_SingleCellVolt_70 1000;
BA_ "Origin" SG_ 980 BMS_SingleCellVolt_71 "ev";
BA_ "Match" SG_ 980 BMS_SingleCellVolt_71 "BMS_SingleCellVolt_71";
BA_ "GenSigCycleTime" SG_ 980 BMS_SingleCellVolt_71 1000;
BA_ "Origin" SG_ 980 BMS_SingleCellVolt_72 "ev";
BA_ "Match" SG_ 980 BMS_SingleCellVolt_72 "BMS_SingleCellVolt_72";
BA_ "GenSigCycleTime" SG_ 980 BMS_SingleCellVolt_72 1000;
BA_ "Origin" SG_ 980 BMS_SingleCellVolt_73 "ev";
BA_ "Match" SG_ 980 BMS_SingleCellVolt_73 "BMS_SingleCellVolt_73";
BA_ "GenSigCycleTime" SG_ 980 BMS_SingleCellVolt_73 1000;
BA_ "Origin" SG_ 980 BMS_SingleCellVolt_74 "ev";
BA_ "Match" SG_ 980 BMS_SingleCellVolt_74 "BMS_SingleCellVolt_74";
BA_ "GenSigCycleTime" SG_ 980 BMS_SingleCellVolt_74 1000;
BA_ "Origin" SG_ 980 BMS_SingleCellVolt_75 "ev";
BA_ "Match" SG_ 980 BMS_SingleCellVolt_75 "BMS_SingleCellVolt_75";
BA_ "GenSigCycleTime" SG_ 980 BMS_SingleCellVolt_75 1000;
BA_ "Origin" SG_ 980 BMS_SingleCellVolt_76 "ev";
BA_ "Match" SG_ 980 BMS_SingleCellVolt_76 "BMS_SingleCellVolt_76";
BA_ "GenSigCycleTime" SG_ 980 BMS_SingleCellVolt_76 1000;
BA_ "Origin" SG_ 980 BMS_SingleCellVolt_77 "ev";
BA_ "Match" SG_ 980 BMS_SingleCellVolt_77 "BMS_SingleCellVolt_77";
BA_ "GenSigCycleTime" SG_ 980 BMS_SingleCellVolt_77 1000;
BA_ "Origin" SG_ 980 BMS_SingleCellVolt_78 "ev";
BA_ "Match" SG_ 980 BMS_SingleCellVolt_78 "BMS_SingleCellVolt_78";
BA_ "GenSigCycleTime" SG_ 980 BMS_SingleCellVolt_78 1000;
BA_ "Origin" SG_ 980 BMS_SingleCellVolt_79 "ev";
BA_ "Match" SG_ 980 BMS_SingleCellVolt_79 "BMS_SingleCellVolt_79";
BA_ "GenSigCycleTime" SG_ 980 BMS_SingleCellVolt_79 1000;
BA_ "Origin" SG_ 980 BMS_SingleCellVolt_80 "ev";
BA_ "Match" SG_ 980 BMS_SingleCellVolt_80 "BMS_SingleCellVolt_80";
BA_ "GenSigCycleTime" SG_ 980 BMS_SingleCellVolt_80 1000;
BA_ "Origin" SG_ 980 BMS_SingleCellVolt_81 "ev";
BA_ "Match" SG_ 980 BMS_SingleCellVolt_81 "BMS_SingleCellVolt_81";
BA_ "GenSigCycleTime" SG_ 980 BMS_SingleCellVolt_81 1000;
BA_ "Origin" SG_ 980 BMS_SingleCellVolt_82 "ev";
BA_ "Match" SG_ 980 BMS_SingleCellVolt_82 "BMS_SingleCellVolt_82";
BA_ "GenSigCycleTime" SG_ 980 BMS_SingleCellVolt_82 1000;
BA_ "Origin" SG_ 980 BMS_SingleCellVolt_83 "ev";
BA_ "Match" SG_ 980 BMS_SingleCellVolt_83 "BMS_SingleCellVolt_83";
BA_ "GenSigCycleTime" SG_ 980 BMS_SingleCellVolt_83 1000;
BA_ "Origin" SG_ 980 BMS_SingleCellVolt_84 "ev";
BA_ "Match" SG_ 980 BMS_SingleCellVolt_84 "BMS_SingleCellVolt_84";
BA_ "GenSigCycleTime" SG_ 980 BMS_SingleCellVolt_84 1000;
BA_ "Origin" SG_ 980 BMS_SingleCellVolt_85 "ev";
BA_ "Match" SG_ 980 BMS_SingleCellVolt_85 "BMS_SingleCellVolt_85";
BA_ "GenSigCycleTime" SG_ 980 BMS_SingleCellVolt_85 1000;
BA_ "Origin" SG_ 980 BMS_SingleCellVolt_86 "ev";
BA_ "Match" SG_ 980 BMS_SingleCellVolt_86 "BMS_SingleCellVolt_86";
BA_ "GenSigCycleTime" SG_ 980 BMS_SingleCellVolt_86 1000;
BA_ "Origin" SG_ 980 BMS_SingleCellVolt_87 "ev";
BA_ "Match" SG_ 980 BMS_SingleCellVolt_87 "BMS_SingleCellVolt_87";
BA_ "GenSigCycleTime" SG_ 980 BMS_SingleCellVolt_87 1000;
BA_ "Origin" SG_ 980 BMS_SingleCellVolt_88 "ev";
BA_ "Match" SG_ 980 BMS_SingleCellVolt_88 "BMS_SingleCellVolt_88";
BA_ "GenSigCycleTime" SG_ 980 BMS_SingleCellVolt_88 1000;
BA_ "Origin" SG_ 980 BMS_SingleCellVolt_89 "ev";
BA_ "Match" SG_ 980 BMS_SingleCellVolt_89 "BMS_SingleCellVolt_89";
BA_ "GenSigCycleTime" SG_ 980 BMS_SingleCellVolt_89 1000;
BA_ "Origin" SG_ 980 BMS_SingleCellVolt_90 "ev";
BA_ "Match" SG_ 980 BMS_SingleCellVolt_90 "BMS_SingleCellVolt_90";
BA_ "GenSigCycleTime" SG_ 980 BMS_SingleCellVolt_90 1000;
BA_ "Origin" SG_ 980 BMS_SingleCellVolt_91 "ev";
BA_ "Match" SG_ 980 BMS_SingleCellVolt_91 "BMS_SingleCellVolt_91";
BA_ "GenSigCycleTime" SG_ 980 BMS_SingleCellVolt_91 1000;
BA_ "Origin" SG_ 980 BMS_SingleCellVolt_92 "ev";
BA_ "Match" SG_ 980 BMS_SingleCellVolt_92 "BMS_SingleCellVolt_92";
BA_ "GenSigCycleTime" SG_ 980 BMS_SingleCellVolt_92 1000;
BA_ "Origin" SG_ 980 BMS_SingleCellVolt_93 "ev";
BA_ "Match" SG_ 980 BMS_SingleCellVolt_93 "BMS_SingleCellVolt_93";
BA_ "GenSigCycleTime" SG_ 980 BMS_SingleCellVolt_93 1000;
BA_ "Origin" SG_ 980 BMS_SingleCellVolt_94 "ev";
BA_ "Match" SG_ 980 BMS_SingleCellVolt_94 "BMS_SingleCellVolt_94";
BA_ "GenSigCycleTime" SG_ 980 BMS_SingleCellVolt_94 1000;
BA_ "Origin" SG_ 980 BMS_SingleCellVolt_95 "ev";
BA_ "Match" SG_ 980 BMS_SingleCellVolt_95 "BMS_SingleCellVolt_95";
BA_ "GenSigCycleTime" SG_ 980 BMS_SingleCellVolt_95 1000;
BA_ "Origin" SG_ 980 BMS_SingleCellVolt_96 "ev";
BA_ "Match" SG_ 980 BMS_SingleCellVolt_96 "BMS_SingleCellVolt_96";
BA_ "GenSigCycleTime" SG_ 980 BMS_SingleCellVolt_96 1000;
BA_ "Origin" SG_ 981 BMS_SingleCellVolt_97 "ev";
BA_ "Match" SG_ 981 BMS_SingleCellVolt_97 "BMS_SingleCellVolt_97";
BA_ "GenSigCycleTime" SG_ 981 BMS_SingleCellVolt_97 1000;
BA_ "Origin" SG_ 981 BMS_SingleCellVolt_98 "ev";
BA_ "Match" SG_ 981 BMS_SingleCellVolt_98 "BMS_SingleCellVolt_98";
BA_ "GenSigCycleTime" SG_ 981 BMS_SingleCellVolt_98 1000;
BA_ "Origin" SG_ 981 BMS_SingleCellVolt_99 "ev";
BA_ "Match" SG_ 981 BMS_SingleCellVolt_99 "BMS_SingleCellVolt_99";
BA_ "GenSigCycleTime" SG_ 981 BMS_SingleCellVolt_99 1000;
BA_ "Origin" SG_ 981 BMS_SingleCellVolt_100 "ev";
BA_ "Match" SG_ 981 BMS_SingleCellVolt_100 "BMS_SingleCellVolt_100";
BA_ "GenSigCycleTime" SG_ 981 BMS_SingleCellVolt_100 1000;
BA_ "Origin" SG_ 981 BMS_SingleCellVolt_101 "ev";
BA_ "Match" SG_ 981 BMS_SingleCellVolt_101 "BMS_SingleCellVolt_101";
BA_ "GenSigCycleTime" SG_ 981 BMS_SingleCellVolt_101 1000;
BA_ "Origin" SG_ 981 BMS_SingleCellVolt_102 "ev";
BA_ "Match" SG_ 981 BMS_SingleCellVolt_102 "BMS_SingleCellVolt_102";
BA_ "GenSigCycleTime" SG_ 981 BMS_SingleCellVolt_102 1000;
BA_ "Origin" SG_ 981 BMS_SingleCellVolt_103 "ev";
BA_ "Match" SG_ 981 BMS_SingleCellVolt_103 "BMS_SingleCellVolt_103";
BA_ "GenSigCycleTime" SG_ 981 BMS_SingleCellVolt_103 1000;
BA_ "Origin" SG_ 981 BMS_SingleCellVolt_104 "ev";
BA_ "Match" SG_ 981 BMS_SingleCellVolt_104 "BMS_SingleCellVolt_104";
BA_ "GenSigCycleTime" SG_ 981 BMS_SingleCellVolt_104 1000;
BA_ "Origin" SG_ 981 BMS_SingleCellVolt_105 "ev";
BA_ "Match" SG_ 981 BMS_SingleCellVolt_105 "BMS_SingleCellVolt_105";
BA_ "GenSigCycleTime" SG_ 981 BMS_SingleCellVolt_105 1000;
BA_ "Origin" SG_ 981 BMS_SingleCellVolt_106 "ev";
BA_ "Match" SG_ 981 BMS_SingleCellVolt_106 "BMS_SingleCellVolt_106";
BA_ "GenSigCycleTime" SG_ 981 BMS_SingleCellVolt_106 1000;
BA_ "Origin" SG_ 981 BMS_SingleCellVolt_107 "ev";
BA_ "Match" SG_ 981 BMS_SingleCellVolt_107 "BMS_SingleCellVolt_107";
BA_ "GenSigCycleTime" SG_ 981 BMS_SingleCellVolt_107 1000;
BA_ "Origin" SG_ 981 BMS_SingleCellVolt_108 "ev";
BA_ "Match" SG_ 981 BMS_SingleCellVolt_108 "BMS_SingleCellVolt_108";
BA_ "GenSigCycleTime" SG_ 981 BMS_SingleCellVolt_108 1000;
BA_ "Origin" SG_ 981 BMS_BattModuleTe_13 "ev";
BA_ "Match" SG_ 981 BMS_BattModuleTe_13 "BMS_BattModuleTe_13";
BA_ "GenSigStartValue" SG_ 981 BMS_BattModuleTe_13 65;
BA_ "GenSigCycleTime" SG_ 981 BMS_BattModuleTe_13 1000;
BA_ "Origin" SG_ 981 BMS_BattModuleTe_23 "ev";
BA_ "Match" SG_ 981 BMS_BattModuleTe_23 "BMS_BattModuleTe_23";
BA_ "GenSigStartValue" SG_ 981 BMS_BattModuleTe_23 65;
BA_ "GenSigCycleTime" SG_ 981 BMS_BattModuleTe_23 1000;
BA_ "Origin" SG_ 981 BMS_BattModuleTe_33 "ev";
BA_ "Match" SG_ 981 BMS_BattModuleTe_33 "BMS_BattModuleTe_33";
BA_ "GenSigStartValue" SG_ 981 BMS_BattModuleTe_33 65;
BA_ "GenSigCycleTime" SG_ 981 BMS_BattModuleTe_33 1000;
BA_ "Origin" SG_ 981 BMS_DTCNumber "ev";
BA_ "Match" SG_ 981 BMS_DTCNumber "BMS_DTCNumber";
BA_ "GenSigCycleTime" SG_ 981 BMS_DTCNumber 1000;
BA_ "Origin" SG_ 981 BMS_BattModuleTe_91 "ev";
BA_ "Match" SG_ 981 BMS_BattModuleTe_91 "BMS_BattModuleTe_91";
BA_ "GenSigStartValue" SG_ 981 BMS_BattModuleTe_91 65;
BA_ "GenSigCycleTime" SG_ 981 BMS_BattModuleTe_91 1000;
BA_ "Origin" SG_ 981 BMS_BattModuleTe_92 "ev";
BA_ "Match" SG_ 981 BMS_BattModuleTe_92 "BMS_BattModuleTe_92";
BA_ "GenSigStartValue" SG_ 981 BMS_BattModuleTe_92 65;
BA_ "GenSigCycleTime" SG_ 981 BMS_BattModuleTe_92 1000;
BA_ "Origin" SG_ 981 BMS_DTCNumber1 "ev";
BA_ "Match" SG_ 981 BMS_DTCNumber1 "BMS_DTCNumber1";
BA_ "GenSigCycleTime" SG_ 981 BMS_DTCNumber1 1000;
BA_ "Origin" SG_ 981 BMS_DTCNumber2 "ev";
BA_ "Match" SG_ 981 BMS_DTCNumber2 "BMS_DTCNumber2";
BA_ "GenSigCycleTime" SG_ 981 BMS_DTCNumber2 1000;
BA_ "TransparentInitValue" SG_ 1009 BMS30_0x3F1 "0 0 0 1 1 1 0 0 ";
BA_ "GenSigCycleTime" SG_ 1009 BMS30_0x3F1 1000;
BA_ "Origin" SG_ 1010 BMS_CellVoltMin "ev";
BA_ "Match" SG_ 1010 BMS_CellVoltMin "BMS_CellVoltMin";
BA_ "GenSigCycleTime" SG_ 1010 BMS_CellVoltMin 1000;
BA_ "Origin" SG_ 1010 BMS_NumberCellVoltMin "ev";
BA_ "Match" SG_ 1010 BMS_NumberCellVoltMin "BMS_NumberCellVoltMin";
BA_ "GenSigCycleTime" SG_ 1010 BMS_NumberCellVoltMin 1000;
BA_ "Origin" SG_ 1010 BMS_CellMaxVolt "ev";
BA_ "Match" SG_ 1010 BMS_CellMaxVolt "BMS_CellMaxVolt";
BA_ "GenSigCycleTime" SG_ 1010 BMS_CellMaxVolt 1000;
BA_ "Origin" SG_ 1010 BMS_NumberCellMaxVolt "ev";
BA_ "Match" SG_ 1010 BMS_NumberCellMaxVolt "BMS_NumberCellMaxVolt";
BA_ "GenSigCycleTime" SG_ 1010 BMS_NumberCellMaxVolt 1000;
BA_ "Origin" SG_ 1010 BMS_CellBalanceSts "ev";
BA_ "Match" SG_ 1010 BMS_CellBalanceSts "BMS_CellBalanceSts";
BA_ "GenSigCycleTime" SG_ 1010 BMS_CellBalanceSts 1000;
BA_ "Origin" SG_ 1010 BMS_RlyCounterSts "ev";
BA_ "Match" SG_ 1010 BMS_RlyCounterSts "BMS_RlyCounterSts";
BA_ "GenSigCycleTime" SG_ 1010 BMS_RlyCounterSts 1000;
BA_ "Origin" SG_ 1010 BMS_SOH_R "ev";
BA_ "Match" SG_ 1010 BMS_SOH_R "BMS_SOH_R";
BA_ "GenSigCycleTime" SG_ 1010 BMS_SOH_R 1000;
BA_ "Origin" SG_ 1011 BMS_ModuleMinTemp "ev";
BA_ "Match" SG_ 1011 BMS_ModuleMinTemp "BMS_ModuleMinTemp";
BA_ "GenSigStartValue" SG_ 1011 BMS_ModuleMinTemp 65;
BA_ "GenSigCycleTime" SG_ 1011 BMS_ModuleMinTemp 1000;
BA_ "Origin" SG_ 1011 BMS_ModuleNumCellMinTemp "ev";
BA_ "Match" SG_ 1011 BMS_ModuleNumCellMinTemp "BMS_ModuleNumCellMinTemp";
BA_ "GenSigStartValue" SG_ 1011 BMS_ModuleNumCellMinTemp 1;
BA_ "GenSigCycleTime" SG_ 1011 BMS_ModuleNumCellMinTemp 1000;
BA_ "Origin" SG_ 1011 BMS_ModuleNumCellMaxTemp "ev";
BA_ "Match" SG_ 1011 BMS_ModuleNumCellMaxTemp "BMS_ModuleNumCellMaxTemp";
BA_ "GenSigStartValue" SG_ 1011 BMS_ModuleNumCellMaxTemp 1;
BA_ "GenSigCycleTime" SG_ 1011 BMS_ModuleNumCellMaxTemp 1000;
BA_ "Origin" SG_ 1011 BMS_ModuleMaxTemp "ev";
BA_ "Match" SG_ 1011 BMS_ModuleMaxTemp "BMS_ModuleMaxTemp";
BA_ "GenSigStartValue" SG_ 1011 BMS_ModuleMaxTemp 65;
BA_ "GenSigCycleTime" SG_ 1011 BMS_ModuleMaxTemp 1000;
BA_ "Origin" SG_ 1011 BMS_NumCellMinTemp "ev";
BA_ "Match" SG_ 1011 BMS_NumCellMinTemp "BMS_NumCellMinTemp";
BA_ "GenSigStartValue" SG_ 1011 BMS_NumCellMinTemp 1;
BA_ "GenSigCycleTime" SG_ 1011 BMS_NumCellMinTemp 1000;
BA_ "Origin" SG_ 1011 BMS_NumCellMaxTemp "ev";
BA_ "Match" SG_ 1011 BMS_NumCellMaxTemp "BMS_NumCellMaxTemp";
BA_ "GenSigStartValue" SG_ 1011 BMS_NumCellMaxTemp 1;
BA_ "GenSigCycleTime" SG_ 1011 BMS_NumCellMaxTemp 1000;
BA_ "Origin" SG_ 1011 BMS_PackMismatchWarn "ev";
BA_ "Match" SG_ 1011 BMS_PackMismatchWarn "BMS_PackMismatchWarn";
BA_ "GenSigCycleTime" SG_ 1011 BMS_PackMismatchWarn 1000;
BA_ "Origin" SG_ 1011 BMS_OverChargeErr "ev";
BA_ "Match" SG_ 1011 BMS_OverChargeErr "BMS_OverChargeErr";
BA_ "GenSigCycleTime" SG_ 1011 BMS_OverChargeErr 1000;
BA_ "Origin" SG_ 1011 BMS_IsolationErr "ev";
BA_ "Match" SG_ 1011 BMS_IsolationErr "BMS_IsolationErr";
BA_ "GenSigCycleTime" SG_ 1011 BMS_IsolationErr 1000;
BA_ "Origin" SG_ 1011 BMS_HVILErr "ev";
BA_ "Match" SG_ 1011 BMS_HVILErr "BMS_HVILErr";
BA_ "GenSigCycleTime" SG_ 1011 BMS_HVILErr 1000;
BA_ "Origin" SG_ 1011 BMS_BattOverTempWarn "ev";
BA_ "Match" SG_ 1011 BMS_BattOverTempWarn "BMS_BattOverTempWarn";
BA_ "GenSigCycleTime" SG_ 1011 BMS_BattOverTempWarn 1000;
BA_ "Origin" SG_ 1011 BMS_ModuleNumberCellMinVolt "ev";
BA_ "Match" SG_ 1011 BMS_ModuleNumberCellMinVolt "BMS_ModuleNumberCellMinVolt";
BA_ "GenSigStartValue" SG_ 1011 BMS_ModuleNumberCellMinVolt 1;
BA_ "GenSigCycleTime" SG_ 1011 BMS_ModuleNumberCellMinVolt 1000;
BA_ "Origin" SG_ 1011 BMS_ModuleNumberCellMaxVolt "ev";
BA_ "Match" SG_ 1011 BMS_ModuleNumberCellMaxVolt "BMS_ModuleNumberCellMaxVolt";
BA_ "GenSigStartValue" SG_ 1011 BMS_ModuleNumberCellMaxVolt 1;
BA_ "GenSigCycleTime" SG_ 1011 BMS_ModuleNumberCellMaxVolt 1000;
BA_ "TransparentInitValue" SG_ 130 ECM4_0x82 "0 127 255 127 255 0 0 0 ";
BA_ "GenSigCycleTime" SG_ 130 ECM4_0x82 10;
BA_ "TransparentInitValue" SG_ 132 ECM7_0x84 "0 0 0 0 0 0 0 0 ";
BA_ "GenSigCycleTime" SG_ 132 ECM7_0x84 10;
BA_ "TransparentInitValue" SG_ 158 HCU_HC16_0x9E "0 0 0 1 144 0 0 0 ";
BA_ "GenSigCycleTime" SG_ 158 HCU_HC16_0x9E 10;
BA_ "TransparentInitValue" SG_ 258 ECM9_0x102 "0 0 0 0 0 0 0 0 ";
BA_ "GenSigCycleTime" SG_ 258 ECM9_0x102 20;
BA_ "TransparentInitValue" SG_ 335 BMS65_0x14F "0 0 0 0 0 0 0 0 ";
BA_ "GenSigCycleTime" SG_ 335 BMS65_0x14F 20;
BA_ "TransparentInitValue" SG_ 486 HUT36_0x1E6 "16 18 2 0 0 0 0 0 ";
BA_ "GenSigSendType" SG_ 486 HUT36_0x1E6 2;
BA_ "TransparentInitValue" SG_ 492 HUT37_0x1EC "0 0 0 0 0 0 0 0 ";
BA_ "GenSigSendType" SG_ 492 HUT37_0x1EC 2;
BA_ "TransparentInitValue" SG_ 724 ECM16_0x2D4 "0 0 0 0 0 0 0 0 ";
BA_ "GenSigCycleTime" SG_ 724 ECM16_0x2D4 100;
BA_ "TransparentInitValue" SG_ 763 VMDR1_0x2FB "0 0 0 0 0 0 0 0 ";
BA_ "GenSigCycleTime" SG_ 763 VMDR1_0x2FB 100;
BA_ "TransparentInitValue" SG_ 848 ECM24_0x350 "0 0 0 0 0 0 0 0 ";
BA_ "GenSigCycleTime" SG_ 848 ECM24_0x350 500;
BA_ "Origin" SG_ 1560 DVR_Phy_Req "fuel";
BA_ "Match" SG_ 1560 DVR_Phy_Req "DVR_Phy_Req";
BA_ "Origin" SG_ 1561 DVR_Phy_Resp "fuel";
BA_ "Match" SG_ 1561 DVR_Phy_Resp "DVR_Phy_Resp";
BA_ "Origin" SG_ 1303 Destination_DVR_NM "fuel";
BA_ "Match" SG_ 1303 Destination_DVR_NM "Destination_DVR_NM";
BA_ "Origin" SG_ 1303 OpCode_DVR_NM "fuel";
BA_ "Match" SG_ 1303 OpCode_DVR_NM "OpCode_DVR_NM";
VAL_ 53 PEPS_T_BOXAuth1 -2147483648 "Valid Value" 0 "Valid Value" ;
VAL_ 54 T_BOX_PEPSAuth1 -2147483648 "Valid Value" 0 "Valid Value" ;
VAL_ 70 PEPS_T_BOXAuth2 6 "Reserved" 7 "Reserved" ;
VAL_ 72 T_BOX_PEPSAuth2 6 "Reserved" 7 "Reserved" ;
VAL_ 743 RFPosnLmpWorkCmd 0 "OFF" 1 "ON" ;
VAL_ 743 LFPosnLmpWorkCmd 0 "OFF" 1 "ON" ;
VAL_ 743 HiBeamWorkCmd 0 "OFF" 1 "ON" ;
VAL_ 743 LowBeamWorkCmd 0 "OFF" 1 "ON" ;
VAL_ 743 RTurnLmpWorkCmd 0 "OFF" 1 "ON" ;
VAL_ 743 LTurnLampWorkCmd 0 "OFF" 1 "ON" ;
VAL_ 743 RDayRunngLmpWorkCmd 0 "OFF" 1 "ON" ;
VAL_ 743 LDayRunngLmpWorkCmd 0 "OFF" 1 "ON" ;
VAL_ 743 RFFogLmpWorkCmd 0 "OFF" 1 "ON" ;
VAL_ 743 LFFogLmpWorkCmd 0 "OFF" 1 "ON" ;
VAL_ 743 LicPlateLmpWorkCmd 0 "OFF" 1 "ON" ;
VAL_ 743 ReversLampWorkCmd 0 "OFF" 1 "ON" ;
VAL_ 743 BrkLmpWorkCmd 0 "OFF" 1 "ON" ;
VAL_ 743 RFogLmpWorkCmd 0 "OFF" 1 "ON" ;
VAL_ 743 RRPosnLmpWorkCmd 0 "OFF" 1 "ON" ;
VAL_ 743 LRPosnLmpWorkCmd 0 "OFF" 1 "ON" ;
VAL_ 829 T_BOX_RemtLRTempSet 0 "No action" 1 "Valid Value(Phys = 0.5 * raw + 16)" 31 "Valid Value(Phys = 0.5 * raw + 16)" 32 "Reserved" 63 "Reserved" ;
VAL_ 829 T_BOX_RemtRRTempSet 0 "No action" 1 "Valid Value(Phys = 0.5 * raw + 16)" 31 "Valid Value(Phys = 0.5 * raw + 16)" 32 "Reserved" 63 "Reserved" ;
VAL_ 829 T_BOX_RemtRearAutoCtrl 0 "No action" 1 "OFF" 2 "ON" 3 "Reserved" ;
VAL_ 829 T_BOX_RemtSecRowLeSeatVentnLvlSe 0 "No Action" 1 "OFF" 2 "Level1_Low" 3 "Level2_Middle" 4 "Level3_High" 5 "Reserved" 7 "Reserved" ;
VAL_ 829 T_BOX_RemtSecRowRiSeatVentnLvlSe 0 "No Action" 1 "OFF" 2 "Level1_Low" 3 "Level2_Middle" 4 "Level3_High" 5 "Reserved" 7 "Reserved" ;
VAL_ 829 T_BOX_MbrMonrEnReq 0 "No action" 1 "Disable" 2 "Enable" 3 "Reserved" ;
VAL_ 829 ReleAlarm_APP 0 "No Action" 1 "Relieve alarm" 2 "Alarm" 3 "Reserved" ;
VAL_ 829 T_BOX_RemtSteerWheelHeatCtrl 0 "No Action" 1 "OFF" 2 "ON" 3 "Reserved" ;
VAL_ 829 T_BOX_AVPActvReq 0 "No Request" 1 "Request HAVP" 2 "Request PAVP" 3 "Reserved" ;
VAL_ 865 HCU_HVILSts 0 "Init" 1 "Normal" 2 "Error" 3 "Reserved" ;
VAL_ 865 HCU_BMSSleepCmd 0 "no sleep" 1 "sleep" ;
VAL_ 865 HCU_P2MActHvDcCurr_RM 0 "Valid value" 20000 "Valid value" 20001 "Reserved" 65533 "Reserved" 65534 "Error" 65535 "Invalid" ;
VAL_ 865 HCU_P2MActHvDcVolt_RM 0 "Valid value" 60000 "Valid value" 60001 "Reserved" 65533 "Reserved" 65534 "Error" 65535 "Invalid" ;
VAL_ 865 HCU_DTCNumber1 0 "Valid values" 1023 "Valid values" ;
VAL_ 865 HCU_DTCNumber2 0 "Valid values" 1023 "Valid values" ;
VAL_ 865 HCU_MotorAmount_RM 0 "Reserved" 1 "Valid value" 253 "Valid value" 254 "Invalid value" 255 "Invalid value" ;
VAL_ 909 HCU_PowertrainSts_RM 1 "ON" 2 "OFF" 3 "Other Mode" ;
VAL_ 909 HCU_BrkPowflag_RM 0 "No power" 1 "Power" ;
VAL_ 909 HCU_ChargSts_RM 1 "Parking charging" 2 "Driving charging" 3 "Uncharged" 4 "Charge end" 5 "Reserved" 7 "Reserved" ;
VAL_ 909 HCU_PTDrvMod_RM 1 "EV Mode" 2 "Hybrid Mode" 3 "Fuel oil Mode" ;
VAL_ 909 HCU_Powerflag_RM 0 "No power" 1 "Power" ;
VAL_ 909 HCU_AccelPedalPosn_Diag_RM 0 "Vaild value" 100 "Vaild value" ;
VAL_ 909 HCU_BrkPedalSts_RM 0 "0%" 101 "Brake pedal pressed" ;
VAL_ 909 HCU_WakeUpSrc 0 "Power up via ignition switch" 1 "Power up via reservation of AC" 2 "Power up via AC Immediate Charging" 3 "Power up via AC Delay Charging" 4 "Power up via DC Charging" 5 "Power up via intelligent DCDC charging" 6 "Power up via battery warm keep by charger requirement" 7 "Power up via battery reservation heating" 8 "Power up via intelligent battery temperature management" 9 "Power up via low temperature hearing before charge" 10 "Power up via V2L" 11 "Reserved" 15 "Reserved" ;
VAL_ 909 HCU_CurrHybSysSts 0 "Vaild value" 500 "Vaild value" ;
VAL_ 937 BMS_ISC_ROhm_Warn 0 "Valid value" 50 "Valid value" 51 "Reserved" 254 "Reserved" 255 "Invalid" ;
VAL_ 937 BMS_ISC_SOC_Warn 0 "Valid value" 100 "Valid value" 101 "Reserved" 254 "Reserved" 255 "Invalid" ;
VAL_ 937 BMS_ISC_T_Warn 0 "Valid value" 165 "Valid value" 166 "Reserved" 254 "Reserved" 255 "invalid" ;
VAL_ 937 BMS_ISC_V_Warn 0 "Valid value" 50 "Valid value" 51 "Reserved" 254 "Reserved" 255 "Invalid" ;
VAL_ 957 DCDC_Tempwarning_RM 0 "No warning" 1 "warning" ;
VAL_ 957 DCDC_ActSts_RM 0 "Initial value" 1 "On" 2 "Off" 3 "Reserved" ;
VAL_ 957 DCDC_FailStswarning_RM 0 "No warning" 1 "warning" ;
VAL_ 963 P2M_MotorSerNumber_RM 0 "Reserved" 1 "Valid value" 253 "Valid value" 254 "Invalid value" 255 "Invalid value" ;
VAL_ 963 P2M_InvActTemp_RM 0 "Valid value" 250 "Valid value" 251 "Reserved" 253 "Reserved" 254 "Error" 255 "Invalid value" ;
VAL_ 963 P2M_ActSpd_RM 0 "Valid value" 65531 "Valid value" 65532 "Rerserved" 65533 "Rerserved" 65534 "Error" 65535 "Invalid value" ;
VAL_ 963 P2M_ActTrq_RM 0 "Valid value" 65531 "Valid value" 65532 "Reserved" 65533 "Reserved" 65534 "Error" 65535 "Invalid value" ;
VAL_ 967 P2M_ActTemp_RM 0 "Valid value" 250 "Valid value" 251 "Reserved" 253 "Reserved" 254 "Error" 255 "Invalid value" ;
VAL_ 967 P2M_OperMode_RM 0 "Reserved" 1 "Consume power" 2 "Generate electricity" 3 "Shut down" 4 "Ready" 5 "Reserved" 253 "Reserved" 254 "Error" 255 "Invalid value" ;
VAL_ 967 P2M_InvTempwarning_RM 0 "Normal" 1 "Warning" ;
VAL_ 967 P2M_Tempwarning_RM 0 "Normal" 1 "Warning" ;
VAL_ 976 BMS_BattTempMax 0 "Valid value" 130 "Valid value" 131 "Reserved" 254 "Reserved" 255 "invalid" ;
VAL_ 976 BMS_BattTempMin 0 "Valid value" 130 "Valid value" 131 "Reserved" 254 "Reserved" 255 "invalid" ;
VAL_ 977 BMS_SingleCellVolt_1 0 "Valid value" 60000 "Valid value" 60001 "Reserved" 65535 "Reserved" ;
VAL_ 977 BMS_SingleCellVolt_2 0 "Valid value" 60000 "Valid value" 60001 "Reserved" 65535 "Reserved" ;
VAL_ 977 BMS_SingleCellVolt_3 0 "Valid value" 60000 "Valid value" 60001 "Reserved" 65535 "Reserved" ;
VAL_ 977 BMS_SingleCellVolt_4 0 "Valid value" 60000 "Valid value" 60001 "Reserved" 65535 "Reserved" ;
VAL_ 977 BMS_SingleCellVolt_5 0 "Valid value" 60000 "Valid value" 60001 "Reserved" 65535 "Reserved" ;
VAL_ 977 BMS_SingleCellVolt_6 0 "Valid value" 60000 "Valid value" 60001 "Reserved" 65535 "Reserved" ;
VAL_ 977 BMS_SingleCellVolt_7 0 "Valid value" 60000 "Valid value" 60001 "Reserved" 65535 "Reserved" ;
VAL_ 977 BMS_SingleCellVolt_8 0 "Valid value" 60000 "Valid value" 60001 "Reserved" 65535 "Reserved" ;
VAL_ 977 BMS_SingleCellVolt_9 0 "Valid value" 60000 "Valid value" 60001 "Reserved" 65535 "Reserved" ;
VAL_ 977 BMS_SingleCellVolt_10 0 "Valid value" 60000 "Valid value" 60001 "Reserved" 65535 "Reserved" ;
VAL_ 977 BMS_SingleCellVolt_11 0 "Valid value" 60000 "Valid value" 60001 "Reserved" 65535 "Reserved" ;
VAL_ 977 BMS_SingleCellVolt_12 0 "Valid value" 60000 "Valid value" 60001 "Reserved" 65535 "Reserved" ;
VAL_ 977 BMS_BattModuleTe_11 0 "Valid value" 165 "Valid value" 166 "Reserved" 254 "Reserved" 255 "invalid" ;
VAL_ 977 BMS_BattModuleTe_12 0 "Valid value" 165 "Valid value" 166 "Reserved" 254 "Reserved" 255 "invalid" ;
VAL_ 977 BMS_BattModuleTe_21 0 "Valid value" 165 "Valid value" 166 "Reserved" 254 "Reserved" 255 "invalid" ;
VAL_ 977 BMS_BattModuleTe_22 0 "Valid value" 165 "Valid value" 166 "Reserved" 254 "Reserved" 255 "invalid" ;
VAL_ 977 BMS_BattModuleTe_31 0 "Valid value" 165 "Valid value" 166 "Reserved" 254 "Reserved" 255 "invalid" ;
VAL_ 977 BMS_BattModuleTe_32 0 "Valid value" 165 "Valid value" 166 "Reserved" 254 "Reserved" 255 "invalid" ;
VAL_ 977 BMS_BattModuleTe_41 0 "Valid value" 165 "Valid value" 166 "Reserved" 254 "Reserved" 255 "invalid" ;
VAL_ 977 BMS_BattModuleTe_42 0 "Valid value" 165 "Valid value" 166 "Reserved" 254 "Reserved" 255 "invalid" ;
VAL_ 977 BMS_BattModuleTe_51 0 "Valid value" 165 "Valid value" 166 "Reserved" 254 "Reserved" 255 "invalid" ;
VAL_ 977 BMS_BattModuleTe_52 0 "Valid value" 165 "Valid value" 166 "Reserved" 254 "Reserved" 255 "invalid" ;
VAL_ 977 BMS_BattModuleTe_61 0 "Valid value" 165 "Valid value" 166 "Reserved" 254 "Reserved" 255 "invalid" ;
VAL_ 977 BMS_BattModuleTe_62 0 "Valid value" 165 "Valid value" 166 "Reserved" 254 "Reserved" 255 "invalid" ;
VAL_ 977 BMS_BattModuleTe_71 0 "Valid value" 165 "Valid value" 166 "Reserved" 254 "Reserved" 255 "invalid" ;
VAL_ 977 BMS_BattModuleTe_72 0 "Valid value" 165 "Valid value" 166 "Reserved" 254 "Reserved" 255 "invalid" ;
VAL_ 977 BMS_BattModuleTe_81 0 "Valid value" 165 "Valid value" 166 "Reserved" 254 "Reserved" 255 "invalid" ;
VAL_ 977 BMS_BattModuleTe_82 0 "Valid value" 165 "Valid value" 166 "Reserved" 254 "Reserved" 255 "invalid" ;
VAL_ 978 BMS_SingleCellVolt_13 0 "Valid value" 60000 "Valid value" 60001 "Reserved" 65535 "Reserved" ;
VAL_ 978 BMS_SingleCellVolt_14 0 "Valid value" 60000 "Valid value" 60001 "Reserved" 65535 "Reserved" ;
VAL_ 978 BMS_SingleCellVolt_15 0 "Valid value" 60000 "Valid value" 60001 "Reserved" 65535 "Reserved" ;
VAL_ 978 BMS_SingleCellVolt_16 0 "Valid value" 60000 "Valid value" 60001 "Reserved" 65535 "Reserved" ;
VAL_ 978 BMS_SingleCellVolt_17 0 "Valid value" 60000 "Valid value" 60001 "Reserved" 65535 "Reserved" ;
VAL_ 978 BMS_SingleCellVolt_18 0 "Valid value" 60000 "Valid value" 60001 "Reserved" 65535 "Reserved" ;
VAL_ 978 BMS_SingleCellVolt_19 0 "Valid value" 60000 "Valid value" 60001 "Reserved" 65535 "Reserved" ;
VAL_ 978 BMS_SingleCellVolt_20 0 "Valid value" 60000 "Valid value" 60001 "Reserved" 65535 "Reserved" ;
VAL_ 978 BMS_SingleCellVolt_21 0 "Valid value" 60000 "Valid value" 60001 "Reserved" 65535 "Reserved" ;
VAL_ 978 BMS_SingleCellVolt_22 0 "Valid value" 60000 "Valid value" 60001 "Reserved" 65535 "Reserved" ;
VAL_ 978 BMS_SingleCellVolt_23 0 "Valid value" 60000 "Valid value" 60001 "Reserved" 65535 "Reserved" ;
VAL_ 978 BMS_SingleCellVolt_24 0 "Valid value" 60000 "Valid value" 60001 "Reserved" 65535 "Reserved" ;
VAL_ 978 BMS_SingleCellVolt_25 0 "Valid value" 60000 "Valid value" 60001 "Reserved" 65535 "Reserved" ;
VAL_ 978 BMS_SingleCellVolt_26 0 "Valid value" 60000 "Valid value" 60001 "Reserved" 65535 "Reserved" ;
VAL_ 978 BMS_SingleCellVolt_27 0 "Valid value" 60000 "Valid value" 60001 "Reserved" 65535 "Reserved" ;
VAL_ 978 BMS_SingleCellVolt_28 0 "Valid value" 60000 "Valid value" 60001 "Reserved" 65535 "Reserved" ;
VAL_ 978 BMS_SingleCellVolt_29 0 "Valid value" 60000 "Valid value" 60001 "Reserved" 65535 "Reserved" ;
VAL_ 978 BMS_SingleCellVolt_30 0 "Valid value" 60000 "Valid value" 60001 "Reserved" 65535 "Reserved" ;
VAL_ 978 BMS_SingleCellVolt_31 0 "Valid value" 60000 "Valid value" 60001 "Reserved" 65535 "Reserved" ;
VAL_ 978 BMS_SingleCellVolt_32 0 "Valid value" 60000 "Valid value" 60001 "Reserved" 65535 "Reserved" ;
VAL_ 978 BMS_SingleCellVolt_33 0 "Valid value" 60000 "Valid value" 60001 "Reserved" 65535 "Reserved" ;
VAL_ 978 BMS_SingleCellVolt_34 0 "Valid value" 60000 "Valid value" 60001 "Reserved" 65535 "Reserved" ;
VAL_ 978 BMS_SingleCellVolt_35 0 "Valid value" 60000 "Valid value" 60001 "Reserved" 65535 "Reserved" ;
VAL_ 978 BMS_SingleCellVolt_36 0 "Valid value" 60000 "Valid value" 60001 "Reserved" 65535 "Reserved" ;
VAL_ 978 BMS_SingleCellVolt_37 0 "Valid value" 60000 "Valid value" 60001 "Reserved" 65535 "Reserved" ;
VAL_ 978 BMS_SingleCellVolt_38 0 "Valid value" 60000 "Valid value" 60001 "Reserved" 65535 "Reserved" ;
VAL_ 978 BMS_SingleCellVolt_39 0 "Valid value" 60000 "Valid value" 60001 "Reserved" 65535 "Reserved" ;
VAL_ 978 BMS_SingleCellVolt_40 0 "Valid value" 60000 "Valid value" 60001 "Reserved" 65535 "Reserved" ;
VAL_ 979 BMS_SingleCellVolt_41 0 "Valid value" 60000 "Valid value" 60001 "Reserved" 65535 "Reserved" ;
VAL_ 979 BMS_SingleCellVolt_42 0 "Valid value" 60000 "Valid value" 60001 "Reserved" 65535 "Reserved" ;
VAL_ 979 BMS_SingleCellVolt_43 0 "Valid value" 60000 "Valid value" 60001 "Reserved" 65535 "Reserved" ;
VAL_ 979 BMS_SingleCellVolt_44 0 "Valid value" 60000 "Valid value" 60001 "Reserved" 65535 "Reserved" ;
VAL_ 979 BMS_SingleCellVolt_45 0 "Valid value" 60000 "Valid value" 60001 "Reserved" 65535 "Reserved" ;
VAL_ 979 BMS_SingleCellVolt_46 0 "Valid value" 60000 "Valid value" 60001 "Reserved" 65535 "Reserved" ;
VAL_ 979 BMS_SingleCellVolt_47 0 "Valid value" 60000 "Valid value" 60001 "Reserved" 65535 "Reserved" ;
VAL_ 979 BMS_SingleCellVolt_48 0 "Valid value" 60000 "Valid value" 60001 "Reserved" 65535 "Reserved" ;
VAL_ 979 BMS_SingleCellVolt_49 0 "Valid value" 60000 "Valid value" 60001 "Reserved" 65535 "Reserved" ;
VAL_ 979 BMS_SingleCellVolt_50 0 "Valid value" 60000 "Valid value" 60001 "Reserved" 65535 "Reserved" ;
VAL_ 979 BMS_SingleCellVolt_51 0 "Valid value" 60000 "Valid value" 60001 "Reserved" 65535 "Reserved" ;
VAL_ 979 BMS_SingleCellVolt_52 0 "Valid value" 60000 "Valid value" 60001 "Reserved" 65535 "Reserved" ;
VAL_ 979 BMS_SingleCellVolt_53 0 "Valid value" 60000 "Valid value" 60001 "Reserved" 65535 "Reserved" ;
VAL_ 979 BMS_SingleCellVolt_54 0 "Valid value" 60000 "Valid value" 60001 "Reserved" 65535 "Reserved" ;
VAL_ 979 BMS_SingleCellVolt_55 0 "Valid value" 60000 "Valid value" 60001 "Reserved" 65535 "Reserved" ;
VAL_ 979 BMS_SingleCellVolt_56 0 "Valid value" 60000 "Valid value" 60001 "Reserved" 65535 "Reserved" ;
VAL_ 979 BMS_SingleCellVolt_57 0 "Valid value" 60000 "Valid value" 60001 "Reserved" 65535 "Reserved" ;
VAL_ 979 BMS_SingleCellVolt_58 0 "Valid value" 60000 "Valid value" 60001 "Reserved" 65535 "Reserved" ;
VAL_ 979 BMS_SingleCellVolt_59 0 "Valid value" 60000 "Valid value" 60001 "Reserved" 65535 "Reserved" ;
VAL_ 979 BMS_SingleCellVolt_60 0 "Valid value" 60000 "Valid value" 60001 "Reserved" 65535 "Reserved" ;
VAL_ 979 BMS_SingleCellVolt_61 0 "Valid value" 60000 "Valid value" 60001 "Reserved" 65535 "Reserved" ;
VAL_ 979 BMS_SingleCellVolt_62 0 "Valid value" 60000 "Valid value" 60001 "Reserved" 65535 "Reserved" ;
VAL_ 979 BMS_SingleCellVolt_63 0 "Valid value" 60000 "Valid value" 60001 "Reserved" 65535 "Reserved" ;
VAL_ 979 BMS_SingleCellVolt_64 0 "Valid value" 60000 "Valid value" 60001 "Reserved" 65535 "Reserved" ;
VAL_ 979 BMS_SingleCellVolt_65 0 "Valid value" 60000 "Valid value" 60001 "Reserved" 65535 "Reserved" ;
VAL_ 979 BMS_SingleCellVolt_66 0 "Valid value" 60000 "Valid value" 60001 "Reserved" 65535 "Reserved" ;
VAL_ 979 BMS_SingleCellVolt_67 0 "Valid value" 60000 "Valid value" 60001 "Reserved" 65535 "Reserved" ;
VAL_ 979 BMS_SingleCellVolt_68 0 "Valid value" 60000 "Valid value" 60001 "Reserved" 65535 "Reserved" ;
VAL_ 980 BMS_SingleCellVolt_69 0 "Valid value" 60000 "Valid value" 60001 "Reserved" 65535 "Reserved" ;
VAL_ 980 BMS_SingleCellVolt_70 0 "Valid value" 60000 "Valid value" 60001 "Reserved" 65535 "Reserved" ;
VAL_ 980 BMS_SingleCellVolt_71 0 "Valid value" 60000 "Valid value" 60001 "Reserved" 65535 "Reserved" ;
VAL_ 980 BMS_SingleCellVolt_72 0 "Valid value" 60000 "Valid value" 60001 "Reserved" 65535 "Reserved" ;
VAL_ 980 BMS_SingleCellVolt_73 0 "Valid value" 60000 "Valid value" 60001 "Reserved" 65535 "Reserved" ;
VAL_ 980 BMS_SingleCellVolt_74 0 "Valid value" 60000 "Valid value" 60001 "Reserved" 65535 "Reserved" ;
VAL_ 980 BMS_SingleCellVolt_75 0 "Valid value" 60000 "Valid value" 60001 "Reserved" 65535 "Reserved" ;
VAL_ 980 BMS_SingleCellVolt_76 0 "Valid value" 60000 "Valid value" 60001 "Reserved" 65535 "Reserved" ;
VAL_ 980 BMS_SingleCellVolt_77 0 "Valid value" 60000 "Valid value" 60001 "Reserved" 65535 "Reserved" ;
VAL_ 980 BMS_SingleCellVolt_78 0 "Valid value" 60000 "Valid value" 60001 "Reserved" 65535 "Reserved" ;
VAL_ 980 BMS_SingleCellVolt_79 0 "Valid value" 60000 "Valid value" 60001 "Reserved" 65535 "Reserved" ;
VAL_ 980 BMS_SingleCellVolt_80 0 "Valid value" 60000 "Valid value" 60001 "Reserved" 65535 "Reserved" ;
VAL_ 980 BMS_SingleCellVolt_81 0 "Valid value" 60000 "Valid value" 60001 "Reserved" 65535 "Reserved" ;
VAL_ 980 BMS_SingleCellVolt_82 0 "Valid value" 60000 "Valid value" 60001 "Reserved" 65535 "Reserved" ;
VAL_ 980 BMS_SingleCellVolt_83 0 "Valid value" 60000 "Valid value" 60001 "Reserved" 65535 "Reserved" ;
VAL_ 980 BMS_SingleCellVolt_84 0 "Valid value" 60000 "Valid value" 60001 "Reserved" 65535 "Reserved" ;
VAL_ 980 BMS_SingleCellVolt_85 0 "Valid value" 60000 "Valid value" 60001 "Reserved" 65535 "Reserved" ;
VAL_ 980 BMS_SingleCellVolt_86 0 "Valid value" 60000 "Valid value" 60001 "Reserved" 65535 "Reserved" ;
VAL_ 980 BMS_SingleCellVolt_87 0 "Valid value" 60000 "Valid value" 60001 "Reserved" 65535 "Reserved" ;
VAL_ 980 BMS_SingleCellVolt_88 0 "Valid value" 60000 "Valid value" 60001 "Reserved" 65535 "Reserved" ;
VAL_ 980 BMS_SingleCellVolt_89 0 "Valid value" 60000 "Valid value" 60001 "Reserved" 65535 "Reserved" ;
VAL_ 980 BMS_SingleCellVolt_90 0 "Valid value" 60000 "Valid value" 60001 "Reserved" 65535 "Reserved" ;
VAL_ 980 BMS_SingleCellVolt_91 0 "Valid value" 60000 "Valid value" 60001 "Reserved" 65535 "Reserved" ;
VAL_ 980 BMS_SingleCellVolt_92 0 "Valid value" 60000 "Valid value" 60001 "Reserved" 65535 "Reserved" ;
VAL_ 980 BMS_SingleCellVolt_93 0 "Valid value" 60000 "Valid value" 60001 "Reserved" 65535 "Reserved" ;
VAL_ 980 BMS_SingleCellVolt_94 0 "Valid value" 60000 "Valid value" 60001 "Reserved" 65535 "Reserved" ;
VAL_ 980 BMS_SingleCellVolt_95 0 "Valid value" 60000 "Valid value" 60001 "Reserved" 65535 "Reserved" ;
VAL_ 980 BMS_SingleCellVolt_96 0 "Valid value" 60000 "Valid value" 60001 "Reserved" 65535 "Reserved" ;
VAL_ 981 BMS_SingleCellVolt_97 0 "Valid value" 60000 "Valid value" 60001 "Reserved" 65535 "Reserved" ;
VAL_ 981 BMS_SingleCellVolt_98 0 "Valid value" 60000 "Valid value" 60001 "Reserved" 65535 "Reserved" ;
VAL_ 981 BMS_SingleCellVolt_99 0 "Valid value" 60000 "Valid value" 60001 "Reserved" 65535 "Reserved" ;
VAL_ 981 BMS_SingleCellVolt_100 0 "Valid value" 60000 "Valid value" 60001 "Reserved" 65535 "Reserved" ;
VAL_ 981 BMS_SingleCellVolt_101 0 "Valid value" 60000 "Valid value" 60001 "Reserved" 65535 "Reserved" ;
VAL_ 981 BMS_SingleCellVolt_102 0 "Valid value" 60000 "Valid value" 60001 "Reserved" 65535 "Reserved" ;
VAL_ 981 BMS_SingleCellVolt_103 0 "Valid value" 60000 "Valid value" 60001 "Reserved" 65535 "Reserved" ;
VAL_ 981 BMS_SingleCellVolt_104 0 "Valid value" 60000 "Valid value" 60001 "Reserved" 65535 "Reserved" ;
VAL_ 981 BMS_SingleCellVolt_105 0 "Valid value" 60000 "Valid value" 60001 "Reserved" 65535 "Reserved" ;
VAL_ 981 BMS_SingleCellVolt_106 0 "Valid value" 60000 "Valid value" 60001 "Reserved" 65535 "Reserved" ;
VAL_ 981 BMS_SingleCellVolt_107 0 "Valid value" 60000 "Valid value" 60001 "Reserved" 65535 "Reserved" ;
VAL_ 981 BMS_SingleCellVolt_108 0 "Valid value" 60000 "Valid value" 60001 "Reserved" 65535 "Reserved" ;
VAL_ 981 BMS_BattModuleTe_13 0 "Valid value" 165 "Valid value" 166 "Reserved" 254 "Reserved" 255 "invalid" ;
VAL_ 981 BMS_BattModuleTe_23 0 "Valid value" 165 "Valid value" 166 "Reserved" 254 "Reserved" 255 "invalid" ;
VAL_ 981 BMS_BattModuleTe_33 0 "Valid value" 165 "Valid value" 166 "Reserved" 254 "Reserved" 255 "invalid" ;
VAL_ 981 BMS_DTCNumber 0 "Default" 1 "Valid value" 501 "Valid value" 502 "Resrved" 511 "Resrved" ;
VAL_ 981 BMS_BattModuleTe_91 0 "Valid value" 165 "Valid value" 166 "Reserved" 254 "Reserved" 255 "invalid" ;
VAL_ 981 BMS_BattModuleTe_92 0 "Valid value" 165 "Valid value" 166 "Reserved" 254 "Reserved" 255 "invalid" ;
VAL_ 981 BMS_DTCNumber1 0 "Default" 1 "Valid value" 501 "Valid value" 502 "Resrved" 511 "Resrved" ;
VAL_ 981 BMS_DTCNumber2 0 "Default" 1 "Valid value" 501 "Valid value" 502 "Resrved" 511 "Resrved" ;
VAL_ 1010 BMS_CellVoltMin 0 "Valid value" 65535 "Valid value" ;
VAL_ 1010 BMS_NumberCellVoltMin 0 "Cell1~Cell108" 107 "Cell1~Cell108" 108 "Reserved" 255 "Reserved" ;
VAL_ 1010 BMS_CellMaxVolt 0 "Valid value" 65535 "Valid value" ;
VAL_ 1010 BMS_NumberCellMaxVolt 0 "Cell1~Cell108" 107 "Cell1~Cell108" 108 "Reserved" 255 "Reserved" ;
VAL_ 1010 BMS_CellBalanceSts 0 "not active" 1 "active normally" 2 "reserved" 3 "reserved" ;
VAL_ 1010 BMS_RlyCounterSts 0 "Normal" 1 "positive relay OUL(over use of life)" 2 "negative relay OUL" 3 "Precharge relay OUL" ;
VAL_ 1010 BMS_SOH_R 0 "Valid value" 1000 "Valid value" 1001 "Reserved" 1022 "Reserved" 1023 "Invalid" ;
VAL_ 1011 BMS_ModuleMinTemp 0 "Valid Value" 130 "Valid Value" 131 "Reserved" 254 "Reserved" 255 "Invalid" ;
VAL_ 1011 BMS_ModuleNumCellMinTemp 0 "Module1~Module9" 8 "Module1~Module9" ;
VAL_ 1011 BMS_ModuleNumCellMaxTemp 0 "Module1~Module9" 8 "Module1~Module9" ;
VAL_ 1011 BMS_ModuleMaxTemp 0 "Valid Value" 130 "Valid Value" 131 "Reserved" 254 "Reserved" 255 "Invalid" ;
VAL_ 1011 BMS_NumCellMinTemp 0 "Module1~Module17" 17 "Module1~Module17" ;
VAL_ 1011 BMS_NumCellMaxTemp 0 "Module1~Module17" 17 "Module1~Module17" ;
VAL_ 1011 BMS_PackMismatchWarn 0 "Normal" 1 "warning" ;
VAL_ 1011 BMS_OverChargeErr 0 "Normal" 1 "warning" ;
VAL_ 1011 BMS_IsolationErr 0 "Normal" 1 "warning" ;
VAL_ 1011 BMS_HVILErr 0 "Normal" 1 "warning" ;
VAL_ 1011 BMS_BattOverTempWarn 0 "Normal" 1 "warning 1 (55~65ÃƒÂ‚Ã‚ÂºC)" 2 "warning 2 (ÃƒÂ¢Ã‚Â‰Ã‚Â¥65ÃƒÂ‚Ã‚ÂºC)" 3 "Reserved" ;
VAL_ 1011 BMS_ModuleNumberCellMinVolt 0 "Number1~number9" 8 "Number1~number9" ;
VAL_ 1011 BMS_ModuleNumberCellMaxVolt 0 "Number1~number9" 8 "Number1~number9" ;
